VERSION "$Format:%h$"

NS_ :

BS_:

BU_: APB APP APS BCCEN BDY DAS DBG EAS EPAS EPAS2 EPAS3S EPB EPBM ESP GTW GTWU IBST IC MCU OCS PARK PARK3 RADAR RCM RT3000 SCCM SDM SEC TAS TAS2 TAS2DBG TOOL TPMS VCSEATD VCSEATP

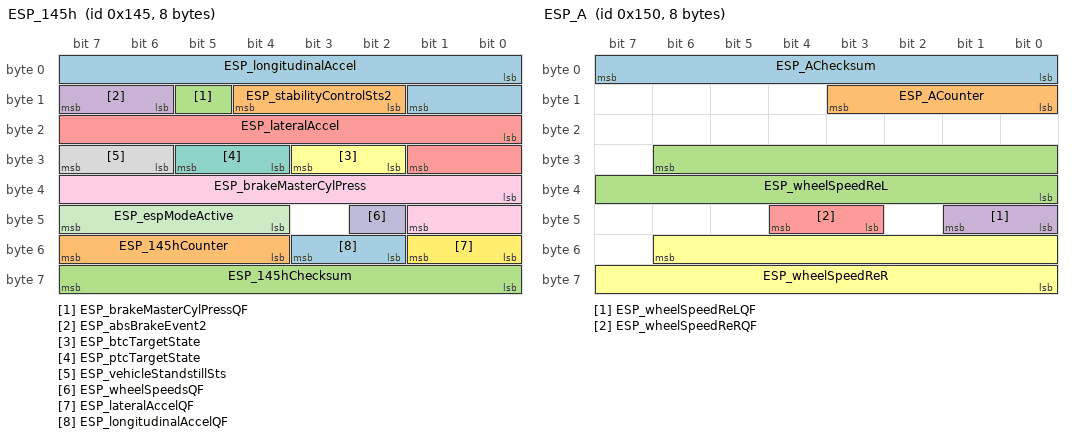
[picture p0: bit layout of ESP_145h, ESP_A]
BO_ 325 ESP_145h: 8 ESP
 SG_ ESP_longitudinalAccel : 0|10@1+ (0.05,-25.6) [-25.6|25.55] "m/s^2" DAS,GTW,PARK,TAS,EPB
 SG_ ESP_stabilityControlSts2 : 10|3@1+ (1,0) [0|0] "" RADAR,GTW,PARK,RCM,APS,TAS2
 SG_ ESP_brakeMasterCylPressQF : 13|1@1+ (1,0) [0|1] "" GTW
 SG_ ESP_absBrakeEvent2 : 14|2@1+ (1,0) [0|0] "" RADAR,GTW,PARK,RCM,APS,TAS2
 SG_ ESP_lateralAccel : 16|10@1+ (0.05,-25.6) [-25.6|25.55] "m/s^2" DAS,GTW,TAS
 SG_ ESP_btcTargetState : 26|2@1+ (1,0) [0|0] "" GTW
 SG_ ESP_ptcTargetState : 28|2@1+ (1,0) [0|0] "" GTW
 SG_ ESP_vehicleStandstillSts : 30|2@1+ (1,0) [0|0] "" RADAR,GTW
 SG_ ESP_brakeMasterCylPress : 32|10@1+ (0.25,-42.5) [-42.5|213.25] "bar" GTW
 SG_ ESP_wheelSpeedsQF : 42|1@1+ (1,0) [0|1] "" GTW,EPB,EPBM,APP
 SG_ ESP_espModeActive : 44|4@1+ (1,0) [0|15] "" GTW
 SG_ ESP_lateralAccelQF : 48|2@1+ (1,0) [0|3] "" GTW,APS,TAS
 SG_ ESP_longitudinalAccelQF : 50|2@1+ (1,0) [0|3] "" GTW,APS,TAS
 SG_ ESP_145hCounter : 52|4@1+ (1,0) [0|0] "" GTW,RCM,TAS
 SG_ ESP_145hChecksum : 56|8@1+ (1,0) [0|0] "" GTW,RCM,TAS

BO_ 336 ESP_A: 8 GTW
 SG_ ESP_AChecksum : 0|8@1+ (1,0) [0|0] "" EPAS
 SG_ ESP_ACounter : 8|4@1+ (1,0) [0|0] "" EPAS
 SG_ ESP_wheelSpeedReL : 30|15@0+ (0.01,0) [0|327.67] "km/h" EPAS
 SG_ ESP_wheelSpeedReLQF : 41|2@0+ (1,0) [0|0] "" EPAS
 SG_ ESP_wheelSpeedReRQF : 44|2@0+ (1,0) [0|0] "" EPAS
 SG_ ESP_wheelSpeedReR : 54|15@0+ (0.01,0) [0|327.67] "km/h" EPAS

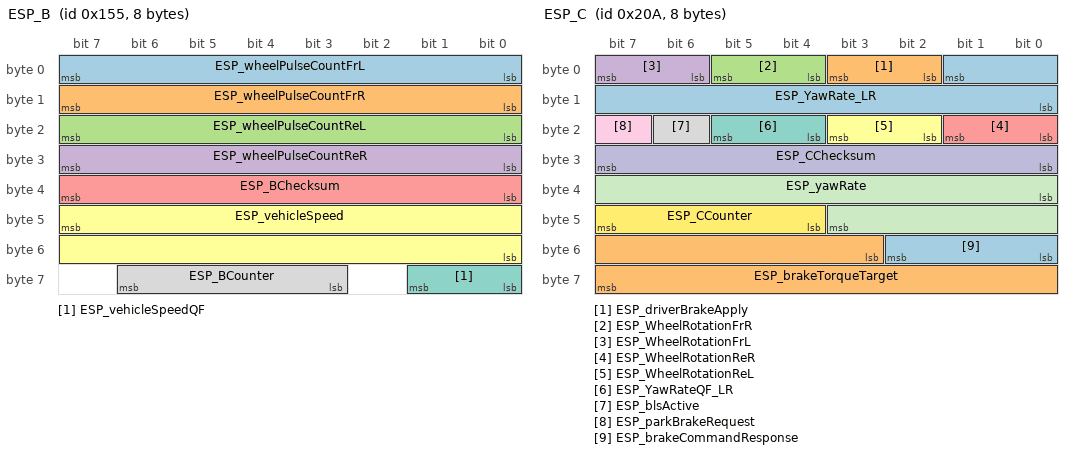
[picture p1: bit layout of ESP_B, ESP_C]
BO_ 341 ESP_B: 8 ESP
 SG_ ESP_wheelPulseCountFrL : 0|8@1+ (1,0) [0|254] "" GTW,TPMS,PARK,APS,APP,EPB,EPBM
 SG_ ESP_wheelPulseCountFrR : 8|8@1+ (1,0) [0|254] "" GTW,TPMS,PARK,APS,APP,EPB,EPBM
 SG_ ESP_wheelPulseCountReL : 16|8@1+ (1,0) [0|254] "" GTW,TPMS,PARK,DAS,EPB,EPBM
 SG_ ESP_wheelPulseCountReR : 24|8@1+ (1,0) [0|254] "" GTW,TPMS,PARK,DAS,EPB,EPBM
 SG_ ESP_BChecksum : 39|8@0+ (1,0) [0|0] "" PARK,SDM,RCM,TPMS,IC,EPAS,EPAS2,EPAS3S,EAS,GTW,TAS
 SG_ ESP_vehicleSpeed : 47|16@0+ (0.01,0) [0|655.35] "kph" PARK,TPMS,IC,SDM,RCM,EAS,EPAS,EPAS2,EPAS3S,GTW,APS,APP,TAS
 SG_ ESP_vehicleSpeedQF : 57|2@0+ (1,0) [0|0] "" PARK,SDM,RCM,TPMS,IC,EPAS,EPAS2,EPAS3S,EAS,GTW,APS,APP,TAS
 SG_ ESP_BCounter : 62|4@0+ (1,0) [0|15] "" PARK,SDM,RCM,TPMS,IC,EAS,EPAS,EPAS2,EPAS3S,GTW,APS,APP,TAS

BO_ 522 ESP_C: 8 ESP
 SG_ ESP_YawRate_LR : 1|10@0+ (0.2,-100) [-100|100] "Degrees/second" GTW,EPAS
 SG_ ESP_driverBrakeApply : 2|2@1+ (1,0) [0|3] "" DAS,GTW,RCM,EPB,TAS2
 SG_ ESP_WheelRotationFrR : 4|2@1+ (1,0) [0|3] "" GTW,PARK,RADAR,APS
 SG_ ESP_WheelRotationFrL : 6|2@1+ (1,0) [0|3] "" GTW,PARK,RADAR,APS
 SG_ ESP_WheelRotationReR : 16|2@1+ (1,0) [0|3] "" GTW,PARK,RADAR,APS
 SG_ ESP_WheelRotationReL : 18|2@1+ (1,0) [0|3] "" GTW,PARK,RADAR,APS
 SG_ ESP_YawRateQF_LR : 21|2@0+ (1,0) [0|0] "" GTW,EPAS,RADAR,APS
 SG_ ESP_blsActive : 22|1@1+ (1,0) [0|1] "" GTW
 SG_ ESP_parkBrakeRequest : 23|1@1+ (1,0) [0|1] "" EPB,EPBM,GTW
 SG_ ESP_CChecksum : 24|8@1+ (1,0) [0|0] "" GTW,EPB,EPBM,EPAS,RCM,TAS2
 SG_ ESP_yawRate : 32|12@1+ (0.001,-2) [-2|2] "rad/s" DAS,GTW,PARK
 SG_ ESP_CCounter : 44|4@1+ (1,0) [0|0] "" GTW,EPB,EPBM,EPAS,RCM,TAS2
 SG_ ESP_brakeCommandResponse : 48|3@1+ (1,0) [0|0] "" RADAR,GTW
 SG_ ESP_brakeTorqueTarget : 51|13@1+ (2,0) [0|16382] "Nm" RADAR,GTW

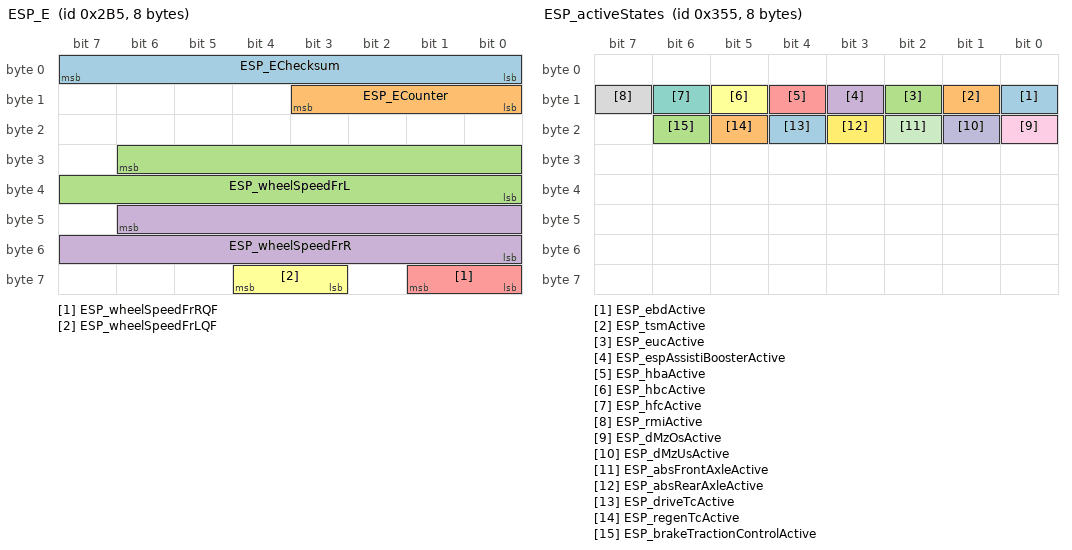
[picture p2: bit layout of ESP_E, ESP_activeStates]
BO_ 693 ESP_E: 8 GTW
 SG_ ESP_EChecksum : 0|8@1+ (1,0) [0|0] "" EPAS
 SG_ ESP_ECounter : 8|4@1+ (1,0) [0|0] "" EPAS
 SG_ ESP_wheelSpeedFrL : 30|15@0+ (0.01,0) [0|327.67] "km/h" EPAS
 SG_ ESP_wheelSpeedFrR : 46|15@0+ (0.01,0) [0|327.67] "km/h" EPAS
 SG_ ESP_wheelSpeedFrRQF : 57|2@0+ (1,0) [0|0] "" EPAS
 SG_ ESP_wheelSpeedFrLQF : 60|2@0+ (1,0) [0|0] "" EPAS

BO_ 853 ESP_activeStates: 8 ESP
 SG_ ESP_ebdActive : 8|1@1+ (1,0) [0|0] "" GTW
 SG_ ESP_tsmActive : 9|1@1+ (1,0) [0|0] "" GTW
 SG_ ESP_eucActive : 10|1@1+ (1,0) [0|0] "" GTW
 SG_ ESP_espAssistiBoosterActive : 11|1@1+ (1,0) [0|0] "" GTW
 SG_ ESP_hbaActive : 12|1@1+ (1,0) [0|0] "" GTW
 SG_ ESP_hbcActive : 13|1@1+ (1,0) [0|0] "" GTW
 SG_ ESP_hfcActive : 14|1@1+ (1,0) [0|0] "" GTW
 SG_ ESP_rmiActive : 15|1@1+ (1,0) [0|0] "" GTW
 SG_ ESP_dMzOsActive : 16|1@1+ (1,0) [0|0] "" GTW
 SG_ ESP_dMzUsActive : 17|1@1+ (1,0) [0|0] "" GTW
 SG_ ESP_absFrontAxleActive : 18|1@1+ (1,0) [0|0] "" GTW
 SG_ ESP_absRearAxleActive : 19|1@1+ (1,0) [0|0] "" GTW
 SG_ ESP_driveTcActive : 20|1@1+ (1,0) [0|0] "" GTW
 SG_ ESP_regenTcActive : 21|1@1+ (1,0) [0|0] "" GTW
 SG_ ESP_brakeTractionControlActive : 22|1@1+ (1,0) [0|0] "" GTW

BO_ 1285 ESP_alertLog: 8 ESP
 SG_ ESP_alertID M : 0|15@1+ (1,0) [0|0] "" GTW
 SG_ ESP_alertType : 15|1@1+ (1,0) [0|0] "" GTW
 SG_ ESP_acmHydReturnPumpWeak m16384 : 16|1@1+ (1,0) [0|0] "" GTW
 SG_ ESP_rfpActUbmrSupplyError m16384 : 17|1@1+ (1,0) [0|0] "" GTW
 SG_ ESP_rfpIFsTstFld m16384 : 18|1@1+ (1,0) [0|0] "" GTW
 SG_ ESP_rfpMrAuCLinTstFld m16384 : 19|1@1+ (1,0) [0|0] "" GTW
 SG_ ESP_rfpMrdSupErr m16384 : 20|1@1+ (1,0) [0|0] "" GTW
 SG_ ESP_rfpMrgInvrsTstFld m16384 : 21|1@1+ (1,0) [0|0] "" GTW
 SG_ ESP_rfpMrgTstFld m16384 : 22|1@1+ (1,0) [0|0] "" GTW
 SG_ ESP_rfpMRolErr m16384 : 23|1@1+ (1,0) [0|0] "" GTW
 SG_ ESP_rfpMrPuTstFld m16384 : 24|1@1+ (1,0) [0|0] "" GTW
 SG_ ESP_rfpMRscErr m16384 : 25|1@1+ (1,0) [0|0] "" GTW
 SG_ ESP_rfpPMTFld m16384 : 26|1@1+ (1,0) [0|0] "" GTW
 SG_ ESP_rfpStopMonFld m16384 : 27|1@1+ (1,0) [0|0] "" GTW
 SG_ ESP_acmHydPumpVoltHigh m16384 : 28|1@1+ (1,0) [0|0] "" GTW
 SG_ ESP_wssFLLineGnd m16385 : 16|1@1+ (1,0) [0|0] "" GTW
 SG_ ESP_wssFLLineHigh m16386 : 16|1@1+ (1,0) [0|0] "" GTW
 SG_ ESP_wssFLLineUndef m16387 : 16|1@1+ (1,0) [0|0] "" GTW
 SG_ ESP_wssMonRangeFL m16388 : 16|1@1+ (1,0) [0|0] "" GTW
 SG_ ESP_wssFLHetBufNoise m16388 : 17|1@1+ (1,0) [0|0] "" GTW
 SG_ ESP_wssSignalLostFL m16389 : 16|1@1+ (1,0) [0|0] "" GTW
 SG_ ESP_wssFLNoEdge m16389 : 17|1@1+ (1,0) [0|0] "" GTW
 SG_ ESP_wssFLWrongSen m16390 : 16|1@1+ (1,0) [0|0] "" GTW
 SG_ ESP_wssMonNoiseFL m16391 : 16|1@1+ (1,0) [0|0] "" GTW
 SG_ ESP_wssMonVDiffFL m16391 : 17|1@1+ (1,0) [0|0] "" GTW
 SG_ ESP_wssMonDoHiFL m16391 : 18|1@1+ (1,0) [0|0] "" GTW
 SG_ ESP_wssMonDoLoFL m16391 : 19|1@1+ (1,0) [0|0] "" GTW
 SG_ ESP_wssMonDynFL m16391 : 20|1@1+ (1,0) [0|0] "" GTW
 SG_ ESP_wssPermanentSusFL m16391 : 21|1@1+ (1,0) [0|0] "" GTW
 SG_ ESP_wssMonWheelDirFL m16392 : 16|1@1+ (1,0) [0|0] "" GTW
 SG_ ESP_wssSignFa m16392 : 17|1@1+ (1,0) [0|0] "" GTW
 SG_ ESP_wssFLAirGap m16393 : 16|1@1+ (1,0) [0|0] "" GTW
 SG_ ESP_wssFLSupGnd m16394 : 16|1@1+ (1,0) [0|0] "" GTW
 SG_ ESP_wssTstFLFld m16395 : 16|1@1+ (1,0) [0|0] "" GTW
 SG_ ESP_wssFRLineGnd m16396 : 16|1@1+ (1,0) [0|0] "" GTW
 SG_ ESP_wssFRLineHigh m16397 : 16|1@1+ (1,0) [0|0] "" GTW
 SG_ ESP_wssFRLineUndef m16398 : 16|1@1+ (1,0) [0|0] "" GTW
 SG_ ESP_wssMonRangeFR m16399 : 16|1@1+ (1,0) [0|0] "" GTW
 SG_ ESP_wssFRHetBufNoise m16399 : 17|1@1+ (1,0) [0|0] "" GTW
 SG_ ESP_wssSignalLostFR m16400 : 16|1@1+ (1,0) [0|0] "" GTW
 SG_ ESP_wssFRNoEdge m16400 : 17|1@1+ (1,0) [0|0] "" GTW
 SG_ ESP_wssFRWrongSen m16401 : 16|1@1+ (1,0) [0|0] "" GTW
 SG_ ESP_wssMonNoiseFR m16402 : 16|1@1+ (1,0) [0|0] "" GTW
 SG_ ESP_wssMonVDiffFR m16402 : 17|1@1+ (1,0) [0|0] "" GTW
 SG_ ESP_wssMonDoHiFR m16402 : 18|1@1+ (1,0) [0|0] "" GTW
 SG_ ESP_wssMonDoLoFR m16402 : 19|1@1+ (1,0) [0|0] "" GTW
 SG_ ESP_wssMonDynFR m16402 : 20|1@1+ (1,0) [0|0] "" GTW
 SG_ ESP_wssPermanentSusFR m16402 : 21|1@1+ (1,0) [0|0] "" GTW
 SG_ ESP_wssMonWheelDirFR m16403 : 16|1@1+ (1,0) [0|0] "" GTW
 SG_ ESP_wssFRAirGap m16404 : 16|1@1+ (1,0) [0|0] "" GTW
 SG_ ESP_wssFRSupGnd m16405 : 16|1@1+ (1,0) [0|0] "" GTW
 SG_ ESP_wssTstFRFld m16406 : 16|1@1+ (1,0) [0|0] "" GTW
 SG_ ESP_wssRLLineGnd m16407 : 16|1@1+ (1,0) [0|0] "" GTW
 SG_ ESP_wssRLLineHigh m16408 : 16|1@1+ (1,0) [0|0] "" GTW
 SG_ ESP_wssRLLineUndef m16409 : 16|1@1+ (1,0) [0|0] "" GTW
 SG_ ESP_wssMonRangeRL m16410 : 16|1@1+ (1,0) [0|0] "" GTW
 SG_ ESP_wssRLHetBufNoise m16410 : 17|1@1+ (1,0) [0|0] "" GTW
 SG_ ESP_wssSignalLostRL m16411 : 16|1@1+ (1,0) [0|0] "" GTW
 SG_ ESP_wssRLNoEdge m16411 : 17|1@1+ (1,0) [0|0] "" GTW
 SG_ ESP_wssRLWrongSen m16412 : 16|1@1+ (1,0) [0|0] "" GTW
 SG_ ESP_wssMonNoiseRL m16413 : 16|1@1+ (1,0) [0|0] "" GTW
 SG_ ESP_wssMonVDiffRL m16413 : 17|1@1+ (1,0) [0|0] "" GTW
 SG_ ESP_wssMonDoHiRL m16413 : 18|1@1+ (1,0) [0|0] "" GTW
 SG_ ESP_wssMonDoLoRL m16413 : 19|1@1+ (1,0) [0|0] "" GTW
 SG_ ESP_wssMonDynRL m16413 : 20|1@1+ (1,0) [0|0] "" GTW
 SG_ ESP_wssPermanentSusRL m16413 : 21|1@1+ (1,0) [0|0] "" GTW
 SG_ ESP_wssMonWheelDirRL m16414 : 16|1@1+ (1,0) [0|0] "" GTW
 SG_ ESP_wssSignRA m16414 : 17|1@1+ (1,0) [0|0] "" GTW
 SG_ ESP_wssRLAirGap m16415 : 16|1@1+ (1,0) [0|0] "" GTW
 SG_ ESP_wssRLSupGnd m16416 : 16|1@1+ (1,0) [0|0] "" GTW
 SG_ ESP_wssTstRLFld m16417 : 16|1@1+ (1,0) [0|0] "" GTW
 SG_ ESP_wssRRLineGnd m16418 : 16|1@1+ (1,0) [0|0] "" GTW
 SG_ ESP_wssRRLineHigh m16419 : 16|1@1+ (1,0) [0|0] "" GTW
 SG_ ESP_wssRRLineUndef m16420 : 16|1@1+ (1,0) [0|0] "" GTW
 SG_ ESP_wssMonRangeRR m16421 : 16|1@1+ (1,0) [0|0] "" GTW
 SG_ ESP_wssRRHetBufNoise m16421 : 17|1@1+ (1,0) [0|0] "" GTW
 SG_ ESP_wssSignalLostRR m16422 : 16|1@1+ (1,0) [0|0] "" GTW
 SG_ ESP_wssRRNoEdge m16422 : 17|1@1+ (1,0) [0|0] "" GTW
 SG_ ESP_wssRRWrongSen m16423 : 16|1@1+ (1,0) [0|0] "" GTW
 SG_ ESP_wssMonNoiseRR m16424 : 16|1@1+ (1,0) [0|0] "" GTW
 SG_ ESP_wssMonVDiffRR m16424 : 17|1@1+ (1,0) [0|0] "" GTW
 SG_ ESP_wssMonDoHiRR m16424 : 18|1@1+ (1,0) [0|0] "" GTW
 SG_ ESP_wssMonDoLoRR m16424 : 19|1@1+ (1,0) [0|0] "" GTW
 SG_ ESP_wssMonDynRR m16424 : 20|1@1+ (1,0) [0|0] "" GTW
 SG_ ESP_wssPermanentSusRR m16424 : 21|1@1+ (1,0) [0|0] "" GTW
 SG_ ESP_wssMonWheelDirRR m16425 : 16|1@1+ (1,0) [0|0] "" GTW
 SG_ ESP_wssRRAirGap m16426 : 16|1@1+ (1,0) [0|0] "" GTW
 SG_ ESP_wssRRSupGnd m16427 : 16|1@1+ (1,0) [0|0] "" GTW
 SG_ ESP_wssTstRRFld m16428 : 16|1@1+ (1,0) [0|0] "" GTW
 SG_ ESP_wssMonGenTempFld m16429 : 16|1@1+ (1,0) [0|0] "" GTW
 SG_ ESP_wssMonVDiffGen m16429 : 17|1@1+ (1,0) [0|0] "" GTW
 SG_ ESP_wssMonWheelDirGen m16429 : 18|1@1+ (1,0) [0|0] "" GTW
 SG_ ESP_wssMoreThanOneSusp m16429 : 19|1@1+ (1,0) [0|0] "" GTW
 SG_ ESP_wssMoreThanOneSuspSt m16429 : 20|1@1+ (1,0) [0|0] "" GTW
 SG_ ESP_wssReverseCurr m16429 : 21|1@1+ (1,0) [0|0] "" GTW
 SG_ ESP_acmBlsPermHigh m16430 : 16|1@1+ (1,0) [0|0] "" GTW
 SG_ ESP_acmBlsPermHighHhc m16430 : 17|1@1+ (1,0) [0|0] "" GTW
 SG_ ESP_blsStatusInvd m16431 : 16|1@1+ (1,0) [0|0] "" GTW
 SG_ ESP_acmPbsPlausPsBlsTh1 m16432 : 16|1@1+ (1,0) [0|0] "" GTW
 SG_ ESP_acmPbsPlausPsBlsTh3 m16432 : 17|1@1+ (1,0) [0|0] "" GTW
 SG_ ESP_pressSenMc1Line m16433 : 16|1@1+ (1,0) [0|0] "" GTW
 SG_ ESP_acmPsOfstMc1 m16434 : 16|1@1+ (1,0) [0|0] "" GTW
 SG_ ESP_acmPsTstpulseMc1 m16435 : 16|1@1+ (1,0) [0|0] "" GTW
 SG_ ESP_comSclLowBrakeFluid m16436 : 16|1@1+ (1,0) [0|0] "" GTW
 SG_ ESP_sasMonConstSig m16437 : 16|1@1+ (1,0) [0|0] "" GTW
 SG_ ESP_sasMonOfst m16438 : 16|1@1+ (1,0) [0|0] "" GTW
 SG_ ESP_sasPls m16439 : 16|1@1+ (1,0) [0|0] "" GTW
 SG_ ESP_sasSign m16439 : 17|1@1+ (1,0) [0|0] "" GTW
 SG_ ESP_sclMm3Ay1AltrnFlt m16440 : 16|1@1+ (1,0) [0|0] "" GTW
 SG_ ESP_sclMm3Ay1InitFl m16440 : 17|1@1+ (1,0) [0|0] "" GTW
 SG_ ESP_sclMm3Ay1InvlidVal m16440 : 18|1@1+ (1,0) [0|0] "" GTW
 SG_ ESP_sclMm3Ay1PermFl m16440 : 19|1@1+ (1,0) [0|0] "" GTW
 SG_ ESP_sclMm3Ay1SenNotAvail m16440 : 20|1@1+ (1,0) [0|0] "" GTW
 SG_ ESP_sclMm3Ay1SigFl m16440 : 21|1@1+ (1,0) [0|0] "" GTW
 SG_ ESP_aysMonRange m16441 : 16|1@1+ (1,0) [0|0] "" GTW
 SG_ ESP_aysOffset m16442 : 16|1@1+ (1,0) [0|0] "" GTW
 SG_ ESP_aysPlaus m16443 : 16|1@1+ (1,0) [0|0] "" GTW
 SG_ ESP_aysStandstill m16443 : 17|1@1+ (1,0) [0|0] "" GTW
 SG_ ESP_sclMm3CalInvValFlt m16444 : 16|1@1+ (1,0) [0|0] "" GTW
 SG_ ESP_sclMm3CalOfstPlsFlt m16444 : 17|1@1+ (1,0) [0|0] "" GTW
 SG_ ESP_sclMm3EEpromAcsErr m16444 : 18|1@1+ (1,0) [0|0] "" GTW
 SG_ ESP_sclMm3SenInfoTimeout m16444 : 19|1@1+ (1,0) [0|0] "" GTW
 SG_ ESP_sclMm3SerNumChanged m16444 : 20|1@1+ (1,0) [0|0] "" GTW
 SG_ ESP_sclMm3Ax1AltrnteFlts m16444 : 21|1@1+ (1,0) [0|0] "" GTW
 SG_ ESP_sclMm3Ax1InitFl m16444 : 22|1@1+ (1,0) [0|0] "" GTW
 SG_ ESP_sclMm3Ax1InvdVal m16444 : 23|1@1+ (1,0) [0|0] "" GTW
 SG_ ESP_sclMm3Ax1PermFl m16444 : 24|1@1+ (1,0) [0|0] "" GTW
 SG_ ESP_sclMm3Ax1SenNotAvail m16444 : 25|1@1+ (1,0) [0|0] "" GTW
 SG_ ESP_sclMm3Ax1SigFl m16444 : 26|1@1+ (1,0) [0|0] "" GTW
 SG_ ESP_axsMonRange m16445 : 16|1@1+ (1,0) [0|0] "" GTW
 SG_ ESP_acmBtmOverheatWarn m16446 : 16|1@1+ (1,0) [0|0] "" GTW
 SG_ ESP_axsOffset m16446 : 17|1@1+ (1,0) [0|0] "" GTW
 SG_ ESP_axsMonConstSig m16447 : 16|1@1+ (1,0) [0|0] "" GTW
 SG_ ESP_axsMonPlaus m16447 : 17|1@1+ (1,0) [0|0] "" GTW
 SG_ ESP_axsPlausHighAccel m16447 : 18|1@1+ (1,0) [0|0] "" GTW
 SG_ ESP_sclMm3Yaw1AltFlts m16448 : 16|1@1+ (1,0) [0|0] "" GTW
 SG_ ESP_sclMm3Yaw1InitFl m16448 : 17|1@1+ (1,0) [0|0] "" GTW
 SG_ ESP_sclMm3Yaw1InvdVal m16448 : 18|1@1+ (1,0) [0|0] "" GTW
 SG_ ESP_sclMm3Yaw1PermFl m16448 : 19|1@1+ (1,0) [0|0] "" GTW
 SG_ ESP_sclMm3Yaw1SenNotAvl m16448 : 20|1@1+ (1,0) [0|0] "" GTW
 SG_ ESP_sclMm3Yaw1SigFl m16448 : 21|1@1+ (1,0) [0|0] "" GTW
 SG_ ESP_yrsSign m16449 : 16|1@1+ (1,0) [0|0] "" GTW
 SG_ ESP_yrsPlaus m16449 : 17|1@1+ (1,0) [0|0] "" GTW
 SG_ ESP_absContCon m16450 : 16|1@1+ (1,0) [0|0] "" GTW
 SG_ ESP_absEmergencyBrake m16450 : 17|1@1+ (1,0) [0|0] "" GTW
 SG_ ESP_vdcContCon m16450 : 18|1@1+ (1,0) [0|0] "" GTW
 SG_ ESP_hydSupHwUndvolt m16451 : 16|1@1+ (1,0) [0|0] "" GTW
 SG_ ESP_hydSupUndvolt m16451 : 17|1@1+ (1,0) [0|0] "" GTW
 SG_ ESP_netUndvolt m16451 : 18|1@1+ (1,0) [0|0] "" GTW
 SG_ ESP_sysUndvolt m16451 : 19|1@1+ (1,0) [0|0] "" GTW
 SG_ ESP_sysNetUndvolt m16451 : 20|1@1+ (1,0) [0|0] "" GTW
 SG_ ESP_sysUBVrUndvolt m16451 : 21|1@1+ (1,0) [0|0] "" GTW
 SG_ ESP_wssUndvolt m16451 : 22|1@1+ (1,0) [0|0] "" GTW
 SG_ ESP_netOvrvolt m16452 : 16|1@1+ (1,0) [0|0] "" GTW
 SG_ ESP_supOvrvolt m16452 : 17|1@1+ (1,0) [0|0] "" GTW
 SG_ ESP_sysOvrvolt m16452 : 18|1@1+ (1,0) [0|0] "" GTW
 SG_ ESP_sysNetOvrvolt m16452 : 19|1@1+ (1,0) [0|0] "" GTW
 SG_ ESP_canEHwError m16453 : 16|1@1+ (1,0) [0|0] "" GTW
 SG_ ESP_pdurEPduInstanceLost m16453 : 17|1@1+ (1,0) [0|0] "" GTW
 SG_ ESP_bertFlt m16454 : 16|1@1+ (1,0) [0|0] "" GTW
 SG_ ESP_canETimeout m16454 : 17|1@1+ (1,0) [0|0] "" GTW
 SG_ ESP_ccmFlt m16454 : 18|1@1+ (1,0) [0|0] "" GTW
 SG_ ESP_cpuException m16454 : 19|1@1+ (1,0) [0|0] "" GTW
 SG_ ESP_deadlineMonTaskx1Ovr m16454 : 20|1@1+ (1,0) [0|0] "" GTW
 SG_ ESP_esmNmiFlt m16454 : 21|1@1+ (1,0) [0|0] "" GTW
 SG_ ESP_esmSafetyFlt m16454 : 22|1@1+ (1,0) [0|0] "" GTW
 SG_ ESP_hetRefError m16454 : 23|1@1+ (1,0) [0|0] "" GTW
 SG_ ESP_micInitSpiTstFld m16454 : 24|1@1+ (1,0) [0|0] "" GTW
 SG_ ESP_micInitSpiTransfError m16454 : 25|1@1+ (1,0) [0|0] "" GTW
 SG_ ESP_micIntMonGenBitMon m16454 : 26|1@1+ (1,0) [0|0] "" GTW
 SG_ ESP_micIntVoltMonFld m16454 : 27|1@1+ (1,0) [0|0] "" GTW
 SG_ ESP_micSpiTout m16454 : 28|1@1+ (1,0) [0|0] "" GTW
 SG_ ESP_micSpiTransferErr m16454 : 29|1@1+ (1,0) [0|0] "" GTW
 SG_ ESP_osErrHook m16454 : 30|1@1+ (1,0) [0|0] "" GTW
 SG_ ESP_pbistErr m16454 : 31|1@1+ (1,0) [0|0] "" GTW
 SG_ ESP_pdmCustomerIdMis m16454 : 32|1@1+ (1,0) [0|0] "" GTW
 SG_ ESP_pdmDtFormatMis m16454 : 33|1@1+ (1,0) [0|0] "" GTW
 SG_ ESP_pdmDeviceOutOfMemory m16454 : 34|1@1+ (1,0) [0|0] "" GTW
 SG_ ESP_pdmFieldSizeMis m16454 : 35|1@1+ (1,0) [0|0] "" GTW
 SG_ ESP_pdmHwAcsErr m16454 : 36|1@1+ (1,0) [0|0] "" GTW
 SG_ ESP_pdmInternalHWErr m16454 : 37|1@1+ (1,0) [0|0] "" GTW
 SG_ ESP_pdmWriteCyclesExceed m16454 : 38|1@1+ (1,0) [0|0] "" GTW
 SG_ ESP_ramInitErr m16454 : 39|1@1+ (1,0) [0|0] "" GTW
 SG_ ESP_ramsinlgeFlt m16454 : 40|1@1+ (1,0) [0|0] "" GTW
 SG_ ESP_rfpDiagHydrProt m16454 : 41|1@1+ (1,0) [0|0] "" GTW
 SG_ ESP_rtpEnaHigh m16454 : 42|1@1+ (1,0) [0|0] "" GTW
 SG_ ESP_smmOneReqsInit m16454 : 43|1@1+ (1,0) [0|0] "" GTW
 SG_ ESP_stackOvrUndFlow m16454 : 44|1@1+ (1,0) [0|0] "" GTW
 SG_ ESP_stmAswSysTout m16454 : 45|1@1+ (1,0) [0|0] "" GTW
 SG_ ESP_sysErrHook m16454 : 46|1@1+ (1,0) [0|0] "" GTW
 SG_ ESP_ucSafetyFlt m16454 : 47|1@1+ (1,0) [0|0] "" GTW
 SG_ ESP_unsupportedHw m16454 : 48|1@1+ (1,0) [0|0] "" GTW
 SG_ ESP_ecuAdcConversionErr m16455 : 16|1@1+ (1,0) [0|0] "" GTW
 SG_ ESP_ecuAdcSelftestErr m16455 : 17|1@1+ (1,0) [0|0] "" GTW
 SG_ ESP_ecuBandGap m16455 : 18|1@1+ (1,0) [0|0] "" GTW
 SG_ ESP_ecuEnableElFls m16455 : 19|1@1+ (1,0) [0|0] "" GTW
 SG_ ESP_ecuEnableHyFls m16455 : 20|1@1+ (1,0) [0|0] "" GTW
 SG_ ESP_ecuEnContErr m16455 : 21|1@1+ (1,0) [0|0] "" GTW
 SG_ ESP_ecuErrpinCntTstFls m16455 : 22|1@1+ (1,0) [0|0] "" GTW
 SG_ ESP_ecuHetException m16455 : 23|1@1+ (1,0) [0|0] "" GTW
 SG_ ESP_ecuHetTuAddErr m16455 : 24|1@1+ (1,0) [0|0] "" GTW
 SG_ ESP_ecuHetTuBusErr m16455 : 25|1@1+ (1,0) [0|0] "" GTW
 SG_ ESP_ecuHetTuBusyErr m16455 : 26|1@1+ (1,0) [0|0] "" GTW
 SG_ ESP_ecuHetTuException m16455 : 27|1@1+ (1,0) [0|0] "" GTW
 SG_ ESP_ecuRomCheck m16455 : 28|1@1+ (1,0) [0|0] "" GTW
 SG_ ESP_ecuSupVoltDivDrift m16455 : 29|1@1+ (1,0) [0|0] "" GTW
 SG_ ESP_ecuTaskMissing m16455 : 30|1@1+ (1,0) [0|0] "" GTW
 SG_ ESP_ecuVrOnWhileWdTout m16455 : 31|1@1+ (1,0) [0|0] "" GTW
 SG_ ESP_ecuVrViaSpiFls m16455 : 32|1@1+ (1,0) [0|0] "" GTW
 SG_ ESP_ecuWdErrCntContErr m16455 : 33|1@1+ (1,0) [0|0] "" GTW
 SG_ ESP_ecuWdFltCntTstFls m16455 : 34|1@1+ (1,0) [0|0] "" GTW
 SG_ ESP_ecuWdScheduleTout m16455 : 35|1@1+ (1,0) [0|0] "" GTW
 SG_ ESP_ecuWdStarttestFls m16455 : 36|1@1+ (1,0) [0|0] "" GTW
 SG_ ESP_ecuWdStatusContErr m16455 : 37|1@1+ (1,0) [0|0] "" GTW
 SG_ ESP_vlvInverseActTstFlt m16456 : 16|1@1+ (1,0) [0|0] "" GTW
 SG_ ESP_vlvOvrHeatProt m16456 : 17|1@1+ (1,0) [0|0] "" GTW
 SG_ ESP_vlvPwmCheckContOn m16456 : 18|1@1+ (1,0) [0|0] "" GTW
 SG_ ESP_vlvRefEepromErr m16456 : 19|1@1+ (1,0) [0|0] "" GTW
 SG_ ESP_vlvRefResistor m16456 : 20|1@1+ (1,0) [0|0] "" GTW
 SG_ ESP_vlvSvdtContOn m16456 : 21|1@1+ (1,0) [0|0] "" GTW
 SG_ ESP_vlvAsicCfgEchoErr m16456 : 22|1@1+ (1,0) [0|0] "" GTW
 SG_ ESP_vlvAvCfg m16456 : 23|1@1+ (1,0) [0|0] "" GTW
 SG_ ESP_vlvBist m16456 : 24|1@1+ (1,0) [0|0] "" GTW
 SG_ ESP_vlvINxFl m16456 : 25|1@1+ (1,0) [0|0] "" GTW
 SG_ ESP_vlvOpLdUndCurrFld m16456 : 26|1@1+ (1,0) [0|0] "" GTW
 SG_ ESP_vlvPromParityErr m16456 : 27|1@1+ (1,0) [0|0] "" GTW
 SG_ ESP_vlvSGndLoss m16456 : 28|1@1+ (1,0) [0|0] "" GTW
 SG_ ESP_vlvSupLineTst m16456 : 29|1@1+ (1,0) [0|0] "" GTW
 SG_ ESP_vlvU3VFld m16456 : 30|1@1+ (1,0) [0|0] "" GTW
 SG_ ESP_vlvUvrLowSpiBitFld m16456 : 31|1@1+ (1,0) [0|0] "" GTW
 SG_ ESP_vlvUVRmeasureCmpFld m16456 : 32|1@1+ (1,0) [0|0] "" GTW
 SG_ ESP_vlvUvrToUbvrLeakage m16456 : 33|1@1+ (1,0) [0|0] "" GTW
 SG_ ESP_vlvVzpFld m16456 : 34|1@1+ (1,0) [0|0] "" GTW
 SG_ ESP_voltPreRegModeFld m16456 : 35|1@1+ (1,0) [0|0] "" GTW
 SG_ ESP_vrHighOhmShToGndCont m16456 : 36|1@1+ (1,0) [0|0] "" GTW
 SG_ ESP_vrOnFls m16456 : 37|1@1+ (1,0) [0|0] "" GTW
 SG_ ESP_vrOnFlsCont m16456 : 38|1@1+ (1,0) [0|0] "" GTW
 SG_ ESP_vrSafetySwitchTout m16456 : 39|1@1+ (1,0) [0|0] "" GTW
 SG_ ESP_vrShortToGndCont m16456 : 40|1@1+ (1,0) [0|0] "" GTW
 SG_ ESP_vrStuck m16456 : 41|1@1+ (1,0) [0|0] "" GTW
 SG_ ESP_vrStuckCont m16456 : 42|1@1+ (1,0) [0|0] "" GTW
 SG_ ESP_wSSHetMonMuxSigErr m16456 : 43|1@1+ (1,0) [0|0] "" GTW
 SG_ ESP_wssModeFld m16456 : 44|1@1+ (1,0) [0|0] "" GTW
 SG_ ESP_wssTstSysICFl m16456 : 45|1@1+ (1,0) [0|0] "" GTW
 SG_ ESP_xpassEchoCountErr m16456 : 46|1@1+ (1,0) [0|0] "" GTW
 SG_ ESP_xpassToutErr m16456 : 47|1@1+ (1,0) [0|0] "" GTW
 SG_ ESP_vlvChanUnusedFreeWhl m16456 : 48|1@1+ (1,0) [0|0] "" GTW
 SG_ ESP_vlvFreeWhlContOn m16456 : 49|1@1+ (1,0) [0|0] "" GTW
 SG_ ESP_vlvAvFlGen m16457 : 16|1@1+ (1,0) [0|0] "" GTW
 SG_ ESP_vlvAvFlLeakage m16457 : 17|1@1+ (1,0) [0|0] "" GTW
 SG_ ESP_vlvAvFlPwm m16457 : 18|1@1+ (1,0) [0|0] "" GTW
 SG_ ESP_vlvAvFlQx m16457 : 19|1@1+ (1,0) [0|0] "" GTW
 SG_ ESP_vlvAvFlResOutOfRange m16457 : 20|1@1+ (1,0) [0|0] "" GTW
 SG_ ESP_vlvAvFlSvdt m16457 : 21|1@1+ (1,0) [0|0] "" GTW
 SG_ ESP_vlvAvFlVart m16457 : 22|1@1+ (1,0) [0|0] "" GTW
 SG_ ESP_vlvAvFrGen m16457 : 23|1@1+ (1,0) [0|0] "" GTW
 SG_ ESP_vlvAvFrLeakage m16457 : 24|1@1+ (1,0) [0|0] "" GTW
 SG_ ESP_vlvAvFrPwm m16457 : 25|1@1+ (1,0) [0|0] "" GTW
 SG_ ESP_vlvAvFrQx m16457 : 26|1@1+ (1,0) [0|0] "" GTW
 SG_ ESP_vlvAvFrResOutOfRange m16457 : 27|1@1+ (1,0) [0|0] "" GTW
 SG_ ESP_vlvAvFrSvdt m16457 : 28|1@1+ (1,0) [0|0] "" GTW
 SG_ ESP_vlvAvFrVart m16457 : 29|1@1+ (1,0) [0|0] "" GTW
 SG_ ESP_vlvAvRlGen m16457 : 30|1@1+ (1,0) [0|0] "" GTW
 SG_ ESP_vlvAvRlLeakage m16457 : 31|1@1+ (1,0) [0|0] "" GTW
 SG_ ESP_vlvAvRlPwm m16457 : 32|1@1+ (1,0) [0|0] "" GTW
 SG_ ESP_vlvAvRlQx m16457 : 33|1@1+ (1,0) [0|0] "" GTW
 SG_ ESP_vlvAvRlResOutOfRange m16457 : 34|1@1+ (1,0) [0|0] "" GTW
 SG_ ESP_vlvAvRlSvdt m16457 : 35|1@1+ (1,0) [0|0] "" GTW
 SG_ ESP_vlvAvRlVart m16457 : 36|1@1+ (1,0) [0|0] "" GTW
 SG_ ESP_vlvAvRrGen m16457 : 37|1@1+ (1,0) [0|0] "" GTW
 SG_ ESP_vlvAvRrLeakage m16457 : 38|1@1+ (1,0) [0|0] "" GTW
 SG_ ESP_vlvAvRrPwm m16457 : 39|1@1+ (1,0) [0|0] "" GTW
 SG_ ESP_vlvAvRrQx m16457 : 40|1@1+ (1,0) [0|0] "" GTW
 SG_ ESP_vlvAvRrResOutOfRange m16457 : 41|1@1+ (1,0) [0|0] "" GTW
 SG_ ESP_vlvAvRrSvdt m16457 : 42|1@1+ (1,0) [0|0] "" GTW
 SG_ ESP_vlvAvRrVart m16457 : 43|1@1+ (1,0) [0|0] "" GTW
 SG_ ESP_vlvEvFlFreeWhl m16458 : 16|1@1+ (1,0) [0|0] "" GTW
 SG_ ESP_vlvEvFlGen m16458 : 17|1@1+ (1,0) [0|0] "" GTW
 SG_ ESP_vlvEvFlLeakage m16458 : 18|1@1+ (1,0) [0|0] "" GTW
 SG_ ESP_vlvEvFlPwm m16458 : 19|1@1+ (1,0) [0|0] "" GTW
 SG_ ESP_vlvEvFlQx m16458 : 20|1@1+ (1,0) [0|0] "" GTW
 SG_ ESP_vlvEvFlResOutOfRange m16458 : 21|1@1+ (1,0) [0|0] "" GTW
 SG_ ESP_vlvEvFlSvdt m16458 : 22|1@1+ (1,0) [0|0] "" GTW
 SG_ ESP_vlvEvFlVart m16458 : 23|1@1+ (1,0) [0|0] "" GTW
 SG_ ESP_vlvEvFrFreeWhl m16458 : 24|1@1+ (1,0) [0|0] "" GTW
 SG_ ESP_vlvEvFrGen m16458 : 25|1@1+ (1,0) [0|0] "" GTW
 SG_ ESP_vlvEvFrLeakage m16458 : 26|1@1+ (1,0) [0|0] "" GTW
 SG_ ESP_vlvEvFrPwm m16458 : 27|1@1+ (1,0) [0|0] "" GTW
 SG_ ESP_vlvEvFrQx m16458 : 28|1@1+ (1,0) [0|0] "" GTW
 SG_ ESP_vlvEvFrResOutOfRange m16458 : 29|1@1+ (1,0) [0|0] "" GTW
 SG_ ESP_vlvEvFrSvdt m16458 : 30|1@1+ (1,0) [0|0] "" GTW
 SG_ ESP_vlvEvFrVart m16458 : 31|1@1+ (1,0) [0|0] "" GTW
 SG_ ESP_vlvEvRlFreeWhl m16458 : 32|1@1+ (1,0) [0|0] "" GTW
 SG_ ESP_vlvEvRlGen m16458 : 33|1@1+ (1,0) [0|0] "" GTW
 SG_ ESP_vlvEvRlLeakage m16458 : 34|1@1+ (1,0) [0|0] "" GTW
 SG_ ESP_vlvEvRlPwm m16458 : 35|1@1+ (1,0) [0|0] "" GTW
 SG_ ESP_vlvEvRlQx m16458 : 36|1@1+ (1,0) [0|0] "" GTW
 SG_ ESP_vlvEvRlResOutOfRange m16458 : 37|1@1+ (1,0) [0|0] "" GTW
 SG_ ESP_vlvEvRlSvdt m16458 : 38|1@1+ (1,0) [0|0] "" GTW
 SG_ ESP_vlvEvRlVart m16458 : 39|1@1+ (1,0) [0|0] "" GTW
 SG_ ESP_vlvEvRrFreeWhl m16458 : 40|1@1+ (1,0) [0|0] "" GTW
 SG_ ESP_vlvEvRrGen m16458 : 41|1@1+ (1,0) [0|0] "" GTW
 SG_ ESP_vlvEvRrLeakage m16458 : 42|1@1+ (1,0) [0|0] "" GTW
 SG_ ESP_vlvEvRrPwm m16458 : 43|1@1+ (1,0) [0|0] "" GTW
 SG_ ESP_vlvEvRrQx m16458 : 44|1@1+ (1,0) [0|0] "" GTW
 SG_ ESP_vlvEvRrResOutOfRange m16458 : 45|1@1+ (1,0) [0|0] "" GTW
 SG_ ESP_vlvEvRrSvdt m16458 : 46|1@1+ (1,0) [0|0] "" GTW
 SG_ ESP_vlvEvRrVart m16458 : 47|1@1+ (1,0) [0|0] "" GTW
 SG_ ESP_vlvHsv1FreeWhl m16459 : 16|1@1+ (1,0) [0|0] "" GTW
 SG_ ESP_vlvHsv1Gen m16459 : 17|1@1+ (1,0) [0|0] "" GTW
 SG_ ESP_vlvHsv1Leakage m16459 : 18|1@1+ (1,0) [0|0] "" GTW
 SG_ ESP_vlvHsv1Pwm m16459 : 19|1@1+ (1,0) [0|0] "" GTW
 SG_ ESP_vlvHsv1Qx m16459 : 20|1@1+ (1,0) [0|0] "" GTW
 SG_ ESP_vlvHsv1ResOutOfRange m16459 : 21|1@1+ (1,0) [0|0] "" GTW
 SG_ ESP_vlvHsv1Svdt m16459 : 22|1@1+ (1,0) [0|0] "" GTW
 SG_ ESP_vlvHsv1Vart m16459 : 23|1@1+ (1,0) [0|0] "" GTW
 SG_ ESP_vlvHsv2FreeWhl m16459 : 24|1@1+ (1,0) [0|0] "" GTW
 SG_ ESP_vlvHsv2Gen m16459 : 25|1@1+ (1,0) [0|0] "" GTW
 SG_ ESP_vlvHsv2Leakage m16459 : 26|1@1+ (1,0) [0|0] "" GTW
 SG_ ESP_vlvHsv2Pwm m16459 : 27|1@1+ (1,0) [0|0] "" GTW
 SG_ ESP_vlvHsv2Qx m16459 : 28|1@1+ (1,0) [0|0] "" GTW
 SG_ ESP_vlvHsv2ResOutOfRange m16459 : 29|1@1+ (1,0) [0|0] "" GTW
 SG_ ESP_vlvHsv2Svdt m16459 : 30|1@1+ (1,0) [0|0] "" GTW
 SG_ ESP_vlvHsv2Vart m16459 : 31|1@1+ (1,0) [0|0] "" GTW
 SG_ ESP_vlvUsv1FreeWhl m16460 : 16|1@1+ (1,0) [0|0] "" GTW
 SG_ ESP_vlvUsv1Gen m16460 : 17|1@1+ (1,0) [0|0] "" GTW
 SG_ ESP_vlvUsv1Leakage m16460 : 18|1@1+ (1,0) [0|0] "" GTW
 SG_ ESP_vlvUsv1Pwm m16460 : 19|1@1+ (1,0) [0|0] "" GTW
 SG_ ESP_vlvUsv1Qx m16460 : 20|1@1+ (1,0) [0|0] "" GTW
 SG_ ESP_vlvUsv1ResOutOfRange m16460 : 21|1@1+ (1,0) [0|0] "" GTW
 SG_ ESP_vlvUsv1Svdt m16460 : 22|1@1+ (1,0) [0|0] "" GTW
 SG_ ESP_vlvUsv1Vart m16460 : 23|1@1+ (1,0) [0|0] "" GTW
 SG_ ESP_vlvUsv1Vdc m16460 : 24|1@1+ (1,0) [0|0] "" GTW
 SG_ ESP_vlvUsv2FreeWhl m16460 : 25|1@1+ (1,0) [0|0] "" GTW
 SG_ ESP_vlvUsv2Gen m16460 : 26|1@1+ (1,0) [0|0] "" GTW
 SG_ ESP_vlvUsv2Leakage m16460 : 27|1@1+ (1,0) [0|0] "" GTW
 SG_ ESP_vlvUsv2Pwm m16460 : 28|1@1+ (1,0) [0|0] "" GTW
 SG_ ESP_vlvUsv2Qx m16460 : 29|1@1+ (1,0) [0|0] "" GTW
 SG_ ESP_vlvUsv2ResOutOfRange m16460 : 30|1@1+ (1,0) [0|0] "" GTW
 SG_ ESP_vlvUsv2Svdt m16460 : 31|1@1+ (1,0) [0|0] "" GTW
 SG_ ESP_vlvUsv2Vart m16460 : 32|1@1+ (1,0) [0|0] "" GTW
 SG_ ESP_vlvUsv2Vdc m16460 : 33|1@1+ (1,0) [0|0] "" GTW
 SG_ ESP_wssHetMonRefSigErr m16460 : 34|1@1+ (1,0) [0|0] "" GTW
 SG_ ESP_EsmNotHandledErr m16460 : 35|1@1+ (1,0) [0|0] "" GTW
 SG_ ESP_tcsRefNotInitInTime m16461 : 16|1@1+ (1,0) [0|0] "" GTW
 SG_ ESP_vdcRefNotInitInTime m16461 : 17|1@1+ (1,0) [0|0] "" GTW
 SG_ ESP_acmBtmOheatBraking m16462 : 16|1@1+ (1,0) [0|0] "" GTW
 SG_ ESP_acmBtmOverheatDeact m16462 : 17|1@1+ (1,0) [0|0] "" GTW
 SG_ ESP_varCodeEeprom m16463 : 16|1@1+ (1,0) [0|0] "" GTW
 SG_ ESP_varCodeValNotRel m16463 : 17|1@1+ (1,0) [0|0] "" GTW
 SG_ ESP_varEcuUncoded m16463 : 18|1@1+ (1,0) [0|0] "" GTW
 SG_ ESP_reverseGearHigh m16464 : 16|1@1+ (1,0) [0|0] "" GTW
 SG_ ESP_reverseGearLow m16464 : 17|1@1+ (1,0) [0|0] "" GTW
 SG_ ESP_comSclVinAllZeroFF m16465 : 16|1@1+ (1,0) [0|0] "" GTW
 SG_ ESP_comSclVip405HsImpVin m16466 : 16|1@1+ (1,0) [0|0] "" GTW
 SG_ ESP_comSclVip405HsDtCrpt m16467 : 16|1@1+ (1,0) [0|0] "" GTW
 SG_ ESP_comSclVip405HsTout m16468 : 16|1@1+ (1,0) [0|0] "" GTW
 SG_ ESP_comSclVinTout m16468 : 17|1@1+ (1,0) [0|0] "" GTW
 SG_ ESP_rollerBenchActv m16469 : 16|1@1+ (1,0) [0|0] "" GTW
 SG_ ESP_netBusOffNetwork0 m16470 : 16|1@1+ (1,0) [0|0] "" GTW
 SG_ ESP_netErrPassivNetwork0 m16470 : 17|1@1+ (1,0) [0|0] "" GTW
 SG_ ESP_netBusOffNetwork1 m16471 : 16|1@1+ (1,0) [0|0] "" GTW
 SG_ ESP_netErrPassivNetwork1 m16471 : 17|1@1+ (1,0) [0|0] "" GTW
 SG_ ESP_comSclDiBtcReqTout m16472 : 16|1@1+ (1,0) [0|0] "" GTW
 SG_ ESP_comSclDiEspConTout m16472 : 17|1@1+ (1,0) [0|0] "" GTW
 SG_ ESP_comSclDiTrq1Tout m16472 : 18|1@1+ (1,0) [0|0] "" GTW
 SG_ ESP_comSclDiTrq2Tout m16472 : 19|1@1+ (1,0) [0|0] "" GTW
 SG_ ESP_comSclDisTrq1Tout m16472 : 20|1@1+ (1,0) [0|0] "" GTW
 SG_ ESP_comSclDrsTxId1Tout m16473 : 16|1@1+ (1,0) [0|0] "" GTW
 SG_ ESP_comSclDrsTxId2Tout m16473 : 17|1@1+ (1,0) [0|0] "" GTW
 SG_ ESP_comSclDrsTxId7Tout m16473 : 18|1@1+ (1,0) [0|0] "" GTW
 SG_ ESP_comSclStwAnglhpTout m16474 : 16|1@1+ (1,0) [0|0] "" GTW
 SG_ ESP_comSclEpbStatusTout m16475 : 16|1@1+ (1,0) [0|0] "" GTW
 SG_ ESP_comSclIbEsp1Tout m16476 : 16|1@1+ (1,0) [0|0] "" GTW
 SG_ ESP_comSclIbEsp2Tout m16476 : 17|1@1+ (1,0) [0|0] "" GTW
 SG_ ESP_comSclBdyStatusTout m16477 : 16|1@1+ (1,0) [0|0] "" GTW
 SG_ ESP_comSclGtwEsp1Tout m16478 : 16|1@1+ (1,0) [0|0] "" GTW
 SG_ ESP_comSclGtwOdoTout m16479 : 16|1@1+ (1,0) [0|0] "" GTW
 SG_ ESP_comSclGtwCarCfgTout m16480 : 16|1@1+ (1,0) [0|0] "" GTW
 SG_ ESP_comSclDiReqCsumFlt m16481 : 16|1@1+ (1,0) [0|0] "" GTW
 SG_ ESP_comSclDiBtcReqDtCrpt m16481 : 17|1@1+ (1,0) [0|0] "" GTW
 SG_ ESP_comSclDiEspCsumFlt m16481 : 18|1@1+ (1,0) [0|0] "" GTW
 SG_ ESP_comSclDiEspConDtCrpt m16481 : 19|1@1+ (1,0) [0|0] "" GTW
 SG_ ESP_comSclDiTrq1CsumFlt m16481 : 20|1@1+ (1,0) [0|0] "" GTW
 SG_ ESP_comSclDiTrq1DtCrpt m16481 : 21|1@1+ (1,0) [0|0] "" GTW
 SG_ ESP_comSclDiTrq2CsumFlt m16481 : 22|1@1+ (1,0) [0|0] "" GTW
 SG_ ESP_comSclDiTrq2DtCrpt m16481 : 23|1@1+ (1,0) [0|0] "" GTW
 SG_ ESP_comSclDisTrq1CsumFlt m16481 : 24|1@1+ (1,0) [0|0] "" GTW
 SG_ ESP_comSclDisTrq1DtCrpt m16481 : 25|1@1+ (1,0) [0|0] "" GTW
 SG_ ESP_comSclDiBtcReqCntFlt m16482 : 16|1@1+ (1,0) [0|0] "" GTW
 SG_ ESP_comSclDiEspConCntFlt m16482 : 17|1@1+ (1,0) [0|0] "" GTW
 SG_ ESP_comSclDiTrq1CntFlt m16482 : 18|1@1+ (1,0) [0|0] "" GTW
 SG_ ESP_comSclDiTrq2CntFlt m16482 : 19|1@1+ (1,0) [0|0] "" GTW
 SG_ ESP_comSclDisTrq1CntFlt m16482 : 20|1@1+ (1,0) [0|0] "" GTW
 SG_ ESP_comSclDrvTrqFaInvd m16483 : 16|1@1+ (1,0) [0|0] "" GTW
 SG_ ESP_comSclDrvTrqRaInvd m16483 : 17|1@1+ (1,0) [0|0] "" GTW
 SG_ ESP_comSclMotorRpmFAInvd m16483 : 18|1@1+ (1,0) [0|0] "" GTW
 SG_ ESP_comSclMotorRpmRaInvd m16483 : 19|1@1+ (1,0) [0|0] "" GTW
 SG_ ESP_comSclMotorTrqFaInvd m16483 : 20|1@1+ (1,0) [0|0] "" GTW
 SG_ ESP_comSclMotorTrqRaInvd m16483 : 21|1@1+ (1,0) [0|0] "" GTW
 SG_ ESP_comSclPedalPosInvd m16483 : 22|1@1+ (1,0) [0|0] "" GTW
 SG_ ESP_comSclTrqIntfcInvd m16483 : 23|1@1+ (1,0) [0|0] "" GTW
 SG_ ESP_sclDiPtcStateInvd m16483 : 24|1@1+ (1,0) [0|0] "" GTW
 SG_ ESP_comSclEpbStatusCrpt m16484 : 16|1@1+ (1,0) [0|0] "" GTW
 SG_ ESP_comSclIbEsp1CsumFlt m16485 : 16|1@1+ (1,0) [0|0] "" GTW
 SG_ ESP_comSclIbEsp1DtCrpt m16485 : 17|1@1+ (1,0) [0|0] "" GTW
 SG_ ESP_comSclIbEsp2CsumFlt m16485 : 18|1@1+ (1,0) [0|0] "" GTW
 SG_ ESP_comSclIbEsp2DtCrpt m16485 : 19|1@1+ (1,0) [0|0] "" GTW
 SG_ ESP_comSclIbEsp1CntFlt m16486 : 16|1@1+ (1,0) [0|0] "" GTW
 SG_ ESP_comSclIbEsp2CntFlt m16486 : 17|1@1+ (1,0) [0|0] "" GTW
 SG_ ESP_sclIbEsp1SOtptRdInvd m16487 : 16|1@1+ (1,0) [0|0] "" GTW
 SG_ ESP_sclIbEsp2IbStatusOff m16487 : 17|1@1+ (1,0) [0|0] "" GTW
 SG_ ESP_sclIbEsp2PrunoInvd m16487 : 18|1@1+ (1,0) [0|0] "" GTW
 SG_ ESP_ibEsp2RampOffFFCBckup m16487 : 19|1@1+ (1,0) [0|0] "" GTW
 SG_ ESP_sclExtReqStatusNotAvail m16487 : 20|1@1+ (1,0) [0|0] "" GTW
 SG_ ESP_comSclBdyStatusCrpt m16488 : 16|1@1+ (1,0) [0|0] "" GTW
 SG_ ESP_comSclStwAngCsumFlt m16489 : 16|1@1+ (1,0) [0|0] "" GTW
 SG_ ESP_comSclStwAngDtCrpt m16489 : 17|1@1+ (1,0) [0|0] "" GTW
 SG_ ESP_comSclStwAngCntFlt m16490 : 16|1@1+ (1,0) [0|0] "" GTW
 SG_ ESP_sasMonMsgCnt m16490 : 17|1@1+ (1,0) [0|0] "" GTW
 SG_ ESP_comSclCanSasErr m16491 : 16|1@1+ (1,0) [0|0] "" GTW
 SG_ ESP_sasCondActvAboveThr m16491 : 17|1@1+ (1,0) [0|0] "" GTW
 SG_ ESP_comSclDrsTxID1DtCrpt m16492 : 16|1@1+ (1,0) [0|0] "" GTW
 SG_ ESP_comSclDrsTxID2DtCrpt m16492 : 17|1@1+ (1,0) [0|0] "" GTW
 SG_ ESP_comSclDrsTxID7DtCrpt m16492 : 18|1@1+ (1,0) [0|0] "" GTW
 SG_ ESP_sclMm3PwrOnMntrFlt m16493 : 16|1@1+ (1,0) [0|0] "" GTW
 SG_ ESP_sclMm3SysCfgErr m16493 : 17|1@1+ (1,0) [0|0] "" GTW
 SG_ ESP_sclMm3ScInternalFlt m16493 : 18|1@1+ (1,0) [0|0] "" GTW
 SG_ ESP_sclMm3ScOvrvoltDtctd m16493 : 19|1@1+ (1,0) [0|0] "" GTW
 SG_ ESP_sclMm3ScDtctsCrcFl m16493 : 20|1@1+ (1,0) [0|0] "" GTW
 SG_ ESP_sclMm3ScDtctsSyncFl m16493 : 21|1@1+ (1,0) [0|0] "" GTW
 SG_ ESP_sclMm3ScDtctsSyncOvr m16493 : 22|1@1+ (1,0) [0|0] "" GTW
 SG_ ESP_sclMm3ScDtctsSyncUnd m16493 : 23|1@1+ (1,0) [0|0] "" GTW
 SG_ ESP_sclMm3ScUndvoltDtctd m16493 : 24|1@1+ (1,0) [0|0] "" GTW
 SG_ ESP_comSclGtwEsp1CsumFlt m16494 : 16|1@1+ (1,0) [0|0] "" GTW
 SG_ ESP_comSclGtwEsp1DtCrpt m16494 : 17|1@1+ (1,0) [0|0] "" GTW
 SG_ ESP_comSclGtwEsp1CntFlt m16495 : 16|1@1+ (1,0) [0|0] "" GTW
 SG_ ESP_comSclGtwOdoDtCrpt m16496 : 16|1@1+ (1,0) [0|0] "" GTW
 SG_ ESP_comSclGtwCrCfgDtCrpt m16497 : 16|1@1+ (1,0) [0|0] "" GTW
 SG_ ESP_teslaChassisTypeSna m16498 : 16|1@1+ (1,0) [0|0] "" GTW
 SG_ ESP_varPlatCalMismtch m16499 : 16|1@1+ (1,0) [0|0] "" GTW
 SG_ ESP_ptsBlsStatusInvd m16500 : 16|1@1+ (1,0) [0|0] "" GTW
 SG_ ESP_comSclBdwReqInvalid m16501 : 16|1@1+ (1,0) [0|0] "" GTW
 SG_ ESP_rcmAx1SignalFail m16502 : 16|1@1+ (1,0) [0|0] "" GTW
 SG_ ESP_rcmAx1SensNotAvail m16502 : 17|1@1+ (1,0) [0|0] "" GTW
 SG_ ESP_rcmAx1InitFail m16502 : 18|1@1+ (1,0) [0|0] "" GTW
 SG_ ESP_rcmAx1InvalidValue m16502 : 19|1@1+ (1,0) [0|0] "" GTW
 SG_ ESP_rcmAx1AlternateFlt m16502 : 20|1@1+ (1,0) [0|0] "" GTW
 SG_ ESP_rcmAy1SignalFail m16503 : 16|1@1+ (1,0) [0|0] "" GTW
 SG_ ESP_rcmAy1SensNotAvail m16503 : 17|1@1+ (1,0) [0|0] "" GTW
 SG_ ESP_rcmAy1InitFail m16503 : 18|1@1+ (1,0) [0|0] "" GTW
 SG_ ESP_rcmAy1InvalidValue m16503 : 19|1@1+ (1,0) [0|0] "" GTW
 SG_ ESP_rcmAy1AlternateFlt m16503 : 20|1@1+ (1,0) [0|0] "" GTW
 SG_ ESP_rcmYaw1SignalFail m16504 : 16|1@1+ (1,0) [0|0] "" GTW
 SG_ ESP_rcmYaw1SensNotAvail m16504 : 17|1@1+ (1,0) [0|0] "" GTW
 SG_ ESP_rcmYaw1InitFail m16504 : 18|1@1+ (1,0) [0|0] "" GTW
 SG_ ESP_rcmYaw1InvalidVal m16504 : 19|1@1+ (1,0) [0|0] "" GTW
 SG_ ESP_rcmYaw1AlternateFlt m16504 : 20|1@1+ (1,0) [0|0] "" GTW
 SG_ ESP_comSclTxId7CsumFlt m16505 : 16|1@1+ (1,0) [0|0] "" GTW
 SG_ ESP_comSclTxId7DtCrpt m16505 : 17|1@1+ (1,0) [0|0] "" GTW
 SG_ ESP_comSclTxId2CsumFlt m16505 : 18|1@1+ (1,0) [0|0] "" GTW
 SG_ ESP_comSclTxId2DtCrpt m16505 : 19|1@1+ (1,0) [0|0] "" GTW
 SG_ ESP_comSclTxId1CsumFlt m16505 : 20|1@1+ (1,0) [0|0] "" GTW
 SG_ ESP_comSclTxId1DtCrpt m16505 : 21|1@1+ (1,0) [0|0] "" GTW
 SG_ ESP_comSclTxId7CntFlt m16506 : 16|1@1+ (1,0) [0|0] "" GTW
 SG_ ESP_comSclTxId2CntFlt m16506 : 17|1@1+ (1,0) [0|0] "" GTW
 SG_ ESP_comSclTxId1CntFlt m16506 : 18|1@1+ (1,0) [0|0] "" GTW
 SG_ ESP_comSclTxId7Tout m16507 : 16|1@1+ (1,0) [0|0] "" GTW
 SG_ ESP_comSclTxId2Tout m16507 : 17|1@1+ (1,0) [0|0] "" GTW
 SG_ ESP_comSclTxId1Tout m16507 : 18|1@1+ (1,0) [0|0] "" GTW
 SG_ ESP_rcmSensorInfoTout m16508 : 16|1@1+ (1,0) [0|0] "" GTW
 SG_ ESP_rcmSerialNumChanged m16509 : 16|1@1+ (1,0) [0|0] "" GTW
 SG_ ESP_rcmBothFramesReceived m16510 : 16|1@1+ (1,0) [0|0] "" GTW
 SG_ ESP_rcmNoFramesReceived m16510 : 17|1@1+ (1,0) [0|0] "" GTW
 SG_ ESP_rcmCalibInvValueFlt m16511 : 16|1@1+ (1,0) [0|0] "" GTW
 SG_ ESP_rcmCalibOffsPlausFlt m16511 : 17|1@1+ (1,0) [0|0] "" GTW
 SG_ ESP_comSclPmState2TOut m16512 : 16|1@1+ (1,0) [0|0] "" GTW
 SG_ ESP_sclBdwReqActiveInvd m16513 : 16|1@1+ (1,0) [0|0] "" GTW
 SG_ ESP_comSclPmState2CsumFlt m16514 : 16|1@1+ (1,0) [0|0] "" GTW
 SG_ ESP_comSclPmState2DtCrpt m16514 : 17|1@1+ (1,0) [0|0] "" GTW
 SG_ ESP_comSclPmState2CntFlt m16515 : 16|1@1+ (1,0) [0|0] "" GTW
 SG_ ESP_sclPmEbrCmdStateInvd m16516 : 16|1@1+ (1,0) [0|0] "" GTW
 SG_ ESP_acmVsSignalPlaus m16517 : 16|1@1+ (1,0) [0|0] "" GTW
 SG_ ESP_sasMonRange m16518 : 16|1@1+ (1,0) [0|0] "" GTW
 SG_ ESP_sasMonGrad m16519 : 16|1@1+ (1,0) [0|0] "" GTW
 SG_ ESP_yrsMonRangeDriving m16520 : 16|1@1+ (1,0) [0|0] "" GTW
 SG_ ESP_yrsMonRangeStandstill m16520 : 17|1@1+ (1,0) [0|0] "" GTW
 SG_ ESP_yrsMonGrad m16521 : 16|1@1+ (1,0) [0|0] "" GTW
 SG_ ESP_yrsOffset1 m16522 : 16|1@1+ (1,0) [0|0] "" GTW
 SG_ ESP_yrsOffset2 m16522 : 17|1@1+ (1,0) [0|0] "" GTW
 SG_ ESP_yrsGain m16522 : 18|1@1+ (1,0) [0|0] "" GTW
 SG_ ESP_yrsNormalOffset m16522 : 19|1@1+ (1,0) [0|0] "" GTW
 SG_ ESP_yrsStandstillComp m16522 : 20|1@1+ (1,0) [0|0] "" GTW
 SG_ ESP_evpFault m16523 : 16|1@1+ (1,0) [0|0] "" GTW
 SG_ ESP_vamEvpRuntimeFault m16523 : 17|1@1+ (1,0) [0|0] "" GTW
 SG_ ESP_acmVsBoosterLowVac m16524 : 16|1@1+ (1,0) [0|0] "" GTW
 SG_ ESP_acmVsLowVacHbcOff m16524 : 17|1@1+ (1,0) [0|0] "" GTW
 SG_ ESP_vamLowVacEvp m16524 : 18|1@1+ (1,0) [0|0] "" GTW
 SG_ ESP_vacFrntAdcSlftestErr m16525 : 16|1@1+ (1,0) [0|0] "" GTW
 SG_ ESP_vacFrntChamberLine m16525 : 17|1@1+ (1,0) [0|0] "" GTW
 SG_ ESP_vacSupply m16525 : 18|1@1+ (1,0) [0|0] "" GTW
 SG_ ESP_vacSupplyUndervolt m16525 : 19|1@1+ (1,0) [0|0] "" GTW
 SG_ ESP_cubasCanEHwError m16526 : 16|1@1+ (1,0) [0|0] "" GTW
 SG_ ESP_cubasCanETimeout m16526 : 17|1@1+ (1,0) [0|0] "" GTW
 SG_ ESP_cubasEPduInstLost m16526 : 18|1@1+ (1,0) [0|0] "" GTW
 SG_ ESP_mcuChassisContrDtCrpt m16527 : 16|1@1+ (1,0) [0|0] "" GTW
 SG_ ESP_mcuChassisContrTout m16528 : 16|1@1+ (1,0) [0|0] "" GTW

BO_ 1606 ESP_bootID: 8 ESP
 SG_ ESP_bootIdData : 0|64@1+ (1,0) [0|0] "" GTW

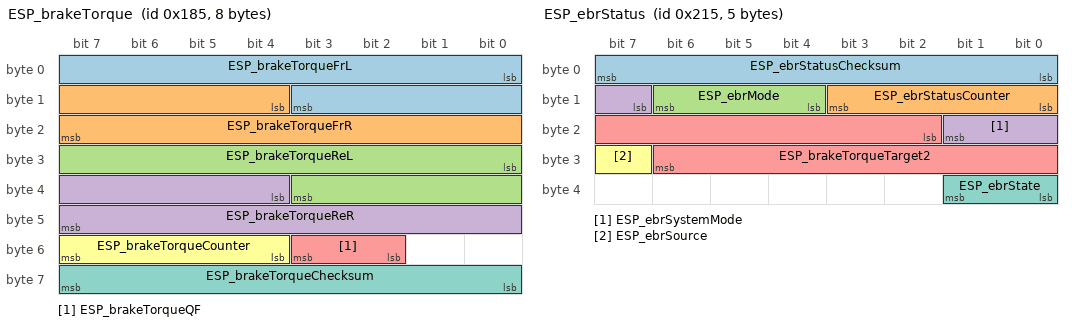
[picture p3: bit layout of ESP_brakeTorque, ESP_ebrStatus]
BO_ 389 ESP_brakeTorque: 8 ESP
 SG_ ESP_brakeTorqueFrL : 0|12@1+ (2,0) [0|8190] "Nm" GTW,TAS2
 SG_ ESP_brakeTorqueFrR : 12|12@1+ (2,0) [0|8190] "Nm" GTW,TAS2
 SG_ ESP_brakeTorqueReL : 24|12@1+ (2,0) [0|8190] "Nm" GTW,TAS2
 SG_ ESP_brakeTorqueReR : 36|12@1+ (2,0) [0|8190] "Nm" GTW,TAS2
 SG_ ESP_brakeTorqueQF : 50|2@1+ (1,0) [0|3] "" GTW,TAS2
 SG_ ESP_brakeTorqueCounter : 52|4@1+ (1,0) [0|0] "" GTW,TAS2
 SG_ ESP_brakeTorqueChecksum : 56|8@1+ (1,0) [0|0] "" GTW,TAS2

BO_ 949 ESP_dtcMatrix: 8 ESP
 SG_ ESP_dtcIndex M : 0|8@1+ (1,0) [0|255] "" GTW
 SG_ ESP_d000_absPumpMotorControl m0 : 8|2@1+ (1,0) [0|0] "" GTW
 SG_ ESP_d001_wssFLLineGnd m0 : 10|2@1+ (1,0) [0|0] "" GTW
 SG_ ESP_d002_wssFLLineHigh m0 : 12|2@1+ (1,0) [0|0] "" GTW
 SG_ ESP_d003_wssFLLineUndef m0 : 14|2@1+ (1,0) [0|0] "" GTW
 SG_ ESP_d004_wssFLOutOfRange m0 : 16|2@1+ (1,0) [0|0] "" GTW
 SG_ ESP_d005_wssFLSignalMissing m0 : 18|2@1+ (1,0) [0|0] "" GTW
 SG_ ESP_d006_wssFLWrongSen m0 : 20|2@1+ (1,0) [0|0] "" GTW
 SG_ ESP_d007_wssFLPlausibility m0 : 22|2@1+ (1,0) [0|0] "" GTW
 SG_ ESP_d008_wssFAWrongMounting m0 : 24|2@1+ (1,0) [0|0] "" GTW
 SG_ ESP_d009_wssFLAirGap m0 : 26|2@1+ (1,0) [0|0] "" GTW
 SG_ ESP_d010_wssFLSupGnd m0 : 28|2@1+ (1,0) [0|0] "" GTW
 SG_ ESP_d011_wssTstFLFld m0 : 30|2@1+ (1,0) [0|0] "" GTW
 SG_ ESP_d012_wssFRLineGnd m0 : 32|2@1+ (1,0) [0|0] "" GTW
 SG_ ESP_d013_wssFRLineHigh m0 : 34|2@1+ (1,0) [0|0] "" GTW
 SG_ ESP_d014_wssFRLineUndef m0 : 36|2@1+ (1,0) [0|0] "" GTW
 SG_ ESP_d015_wssFROutOfRange m0 : 38|2@1+ (1,0) [0|0] "" GTW
 SG_ ESP_d016_wssFRSignalMissing m0 : 40|2@1+ (1,0) [0|0] "" GTW
 SG_ ESP_d017_wssFRWrongSen m0 : 42|2@1+ (1,0) [0|0] "" GTW
 SG_ ESP_d018_wssFRPlausibility m0 : 44|2@1+ (1,0) [0|0] "" GTW
 SG_ ESP_d019_wssMonWheelDirFR m0 : 46|2@1+ (1,0) [0|0] "" GTW
 SG_ ESP_d020_wssFRAirGap m0 : 48|2@1+ (1,0) [0|0] "" GTW
 SG_ ESP_d021_wssFRSupGnd m0 : 50|2@1+ (1,0) [0|0] "" GTW
 SG_ ESP_d022_wssTstFRFld m0 : 52|2@1+ (1,0) [0|0] "" GTW
 SG_ ESP_d023_wssRLLineGnd m0 : 54|2@1+ (1,0) [0|0] "" GTW
 SG_ ESP_d024_wssRLLineHigh m0 : 56|2@1+ (1,0) [0|0] "" GTW
 SG_ ESP_d025_wssRLLineUndef m0 : 58|2@1+ (1,0) [0|0] "" GTW
 SG_ ESP_d026_wssRLOutOfRange m0 : 60|2@1+ (1,0) [0|0] "" GTW
 SG_ ESP_d027_wssRLSignalMissing m0 : 62|2@1+ (1,0) [0|0] "" GTW
 SG_ ESP_d028_wssRLWrongSen m1 : 8|2@1+ (1,0) [0|0] "" GTW
 SG_ ESP_d029_wssRLPlausibility m1 : 10|2@1+ (1,0) [0|0] "" GTW
 SG_ ESP_d030_wssRAWrongMounting m1 : 12|2@1+ (1,0) [0|0] "" GTW
 SG_ ESP_d031_wssRLAirGap m1 : 14|2@1+ (1,0) [0|0] "" GTW
 SG_ ESP_d032_wssRLSupGnd m1 : 16|2@1+ (1,0) [0|0] "" GTW
 SG_ ESP_d033_wssTstRLFld m1 : 18|2@1+ (1,0) [0|0] "" GTW
 SG_ ESP_d034_wssRRLineGnd m1 : 20|2@1+ (1,0) [0|0] "" GTW
 SG_ ESP_d035_wssRRLineHigh m1 : 22|2@1+ (1,0) [0|0] "" GTW
 SG_ ESP_d036_wssRRLineUndef m1 : 24|2@1+ (1,0) [0|0] "" GTW
 SG_ ESP_d037_wssRROutOfRange m1 : 26|2@1+ (1,0) [0|0] "" GTW
 SG_ ESP_d038_wssRRSignalMissing m1 : 28|2@1+ (1,0) [0|0] "" GTW
 SG_ ESP_d039_wssRRWrongSen m1 : 30|2@1+ (1,0) [0|0] "" GTW
 SG_ ESP_d040_wssRRPlausibility m1 : 32|2@1+ (1,0) [0|0] "" GTW
 SG_ ESP_d041_wssMonWheelDirRR m1 : 34|2@1+ (1,0) [0|0] "" GTW
 SG_ ESP_d042_wssRRAirGap m1 : 36|2@1+ (1,0) [0|0] "" GTW
 SG_ ESP_d043_wssRRSupGnd m1 : 38|2@1+ (1,0) [0|0] "" GTW
 SG_ ESP_d044_wssTstRRFld m1 : 40|2@1+ (1,0) [0|0] "" GTW
 SG_ ESP_d045_wssGeneralFault m1 : 42|2@1+ (1,0) [0|0] "" GTW
 SG_ ESP_d046_brakeSwitchStuckHigh m1 : 44|2@1+ (1,0) [0|0] "" GTW
 SG_ ESP_d047_blsStatusInvd m1 : 46|2@1+ (1,0) [0|0] "" GTW
 SG_ ESP_d048_brakeSwitchPlausib m1 : 48|2@1+ (1,0) [0|0] "" GTW
 SG_ ESP_d049_pressSenMc1Line m1 : 50|2@1+ (1,0) [0|0] "" GTW
 SG_ ESP_d050_acmPsOfstMc1 m1 : 52|2@1+ (1,0) [0|0] "" GTW
 SG_ ESP_d051_acmPsTstpulseMc1 m1 : 54|2@1+ (1,0) [0|0] "" GTW
 SG_ ESP_d052_comSclLowBrakeFluid m1 : 56|2@1+ (1,0) [0|0] "" GTW
 SG_ ESP_d053_sasMonConstSig m1 : 58|2@1+ (1,0) [0|0] "" GTW
 SG_ ESP_d054_sasMonOfst m1 : 60|2@1+ (1,0) [0|0] "" GTW
 SG_ ESP_d055_sasPlausibility m1 : 62|2@1+ (1,0) [0|0] "" GTW
 SG_ ESP_d056_aySensorFault m2 : 8|2@1+ (1,0) [0|0] "" GTW
 SG_ ESP_d057_aysMonRange m2 : 10|2@1+ (1,0) [0|0] "" GTW
 SG_ ESP_d058_aysOffset m2 : 12|2@1+ (1,0) [0|0] "" GTW
 SG_ ESP_d059_aysPlaus m2 : 14|2@1+ (1,0) [0|0] "" GTW
 SG_ ESP_d060_axSensorFault m2 : 16|2@1+ (1,0) [0|0] "" GTW
 SG_ ESP_d061_axsMonRange m2 : 18|2@1+ (1,0) [0|0] "" GTW
 SG_ ESP_d062_axOffsTooLarge m2 : 20|2@1+ (1,0) [0|0] "" GTW
 SG_ ESP_d063_axSensorPlaus m2 : 22|2@1+ (1,0) [0|0] "" GTW
 SG_ ESP_d064_yawSensorFault m2 : 24|2@1+ (1,0) [0|0] "" GTW
 SG_ ESP_d065_yawSensorPlaus m2 : 26|2@1+ (1,0) [0|0] "" GTW
 SG_ ESP_d066_absVdcContControl m2 : 28|2@1+ (1,0) [0|0] "" GTW
 SG_ ESP_d067_undervoltage m2 : 30|2@1+ (1,0) [0|0] "" GTW
 SG_ ESP_d068_overvoltage m2 : 32|2@1+ (1,0) [0|0] "" GTW
 SG_ ESP_d069_memoryFault m2 : 34|2@1+ (1,0) [0|0] "" GTW
 SG_ ESP_d070_ecuInternalGeneric m2 : 36|2@1+ (1,0) [0|0] "" GTW
 SG_ ESP_d071_ecuInternalEcu m2 : 38|2@1+ (1,0) [0|0] "" GTW
 SG_ ESP_d072_valveGeneric m2 : 40|2@1+ (1,0) [0|0] "" GTW
 SG_ ESP_d073_valveAvFaults m2 : 42|2@1+ (1,0) [0|0] "" GTW
 SG_ ESP_d074_valveEvFaults m2 : 44|2@1+ (1,0) [0|0] "" GTW
 SG_ ESP_d075_valveHsvFaults m2 : 46|2@1+ (1,0) [0|0] "" GTW
 SG_ ESP_d076_valveUsvFaults m2 : 48|2@1+ (1,0) [0|0] "" GTW
 SG_ ESP_d077_refNotInitInTime m2 : 50|2@1+ (1,0) [0|0] "" GTW
 SG_ ESP_d078_acmBtmOheatBraking m2 : 52|2@1+ (1,0) [0|0] "" GTW
 SG_ ESP_d079_varCodeEeprom m2 : 54|2@1+ (1,0) [0|0] "" GTW
 SG_ ESP_d080_reverseGearPlaus m2 : 56|2@1+ (1,0) [0|0] "" GTW
 SG_ ESP_d081_comSclVinAllZeroFF m2 : 58|2@1+ (1,0) [0|0] "" GTW
 SG_ ESP_d082_comSclVip405HsImpVin m2 : 60|2@1+ (1,0) [0|0] "" GTW
 SG_ ESP_d083_comSclVip405HsDtCrpt m2 : 62|2@1+ (1,0) [0|0] "" GTW
 SG_ ESP_d084_comSclVip405HsTout m3 : 8|2@1+ (1,0) [0|0] "" GTW
 SG_ ESP_d085_rollerBenchActv m3 : 10|2@1+ (1,0) [0|0] "" GTW
 SG_ ESP_d086_network0 m3 : 12|2@1+ (1,0) [0|0] "" GTW
 SG_ ESP_d087_network1 m3 : 14|2@1+ (1,0) [0|0] "" GTW
 SG_ ESP_d088_comMotorTOut m3 : 16|2@1+ (1,0) [0|0] "" GTW
 SG_ ESP_d089_comDrsTxTOut m3 : 18|2@1+ (1,0) [0|0] "" GTW
 SG_ ESP_d090_comSclStwAnglhpTout m3 : 20|2@1+ (1,0) [0|0] "" GTW
 SG_ ESP_d091_comSclEpbStatusTout m3 : 22|2@1+ (1,0) [0|0] "" GTW
 SG_ ESP_d092_comIbEsptTOut m3 : 24|2@1+ (1,0) [0|0] "" GTW
 SG_ ESP_d093_comSclBdyStatusTout m3 : 26|2@1+ (1,0) [0|0] "" GTW
 SG_ ESP_d094_comSclGtwEsp1Tout m3 : 28|2@1+ (1,0) [0|0] "" GTW
 SG_ ESP_d095_comSclGtwOdoTout m3 : 30|2@1+ (1,0) [0|0] "" GTW
 SG_ ESP_d096_comSclGtwCarCfgTout m3 : 32|2@1+ (1,0) [0|0] "" GTW
 SG_ ESP_d097_comMotorCrpt m3 : 34|2@1+ (1,0) [0|0] "" GTW
 SG_ ESP_d098_comMotorMsgCount m3 : 36|2@1+ (1,0) [0|0] "" GTW
 SG_ ESP_d099_comMotorInvalidSig m3 : 38|2@1+ (1,0) [0|0] "" GTW
 SG_ ESP_d100_comSclEpbStatusCrpt m3 : 40|2@1+ (1,0) [0|0] "" GTW
 SG_ ESP_d101_comIbEspCrpt m3 : 42|2@1+ (1,0) [0|0] "" GTW
 SG_ ESP_d102_comIbEspMsgCount m3 : 44|2@1+ (1,0) [0|0] "" GTW
 SG_ ESP_d103_sclIbEspInvalidSig m3 : 46|2@1+ (1,0) [0|0] "" GTW
 SG_ ESP_d104_comSclBdyStatusCrpt m3 : 48|2@1+ (1,0) [0|0] "" GTW
 SG_ ESP_d105_comStwAnglHpCrpt m3 : 50|2@1+ (1,0) [0|0] "" GTW
 SG_ ESP_d106_comStwAnglHpMsgCount m3 : 52|2@1+ (1,0) [0|0] "" GTW
 SG_ ESP_d107_comSasInvalidSig m3 : 54|2@1+ (1,0) [0|0] "" GTW
 SG_ ESP_d108_comDrsTxCrpt m3 : 56|2@1+ (1,0) [0|0] "" GTW
 SG_ ESP_d109_sclMm3InvalidSig m3 : 58|2@1+ (1,0) [0|0] "" GTW
 SG_ ESP_d110_comGtwEsp1Crpt m3 : 60|2@1+ (1,0) [0|0] "" GTW
 SG_ ESP_d111_comSclGtwEsp1CntFlt m3 : 62|2@1+ (1,0) [0|0] "" GTW
 SG_ ESP_d112_comSclGtwOdoDtCrpt m4 : 8|2@1+ (1,0) [0|0] "" GTW
 SG_ ESP_d113_comSclGtwCrCfgDtCrpt m4 : 10|2@1+ (1,0) [0|0] "" GTW
 SG_ ESP_d114_teslaChassisTypeSna m4 : 12|2@1+ (1,0) [0|0] "" GTW
 SG_ ESP_d115_varPlatCalMismtch m4 : 14|2@1+ (1,0) [0|0] "" GTW
 SG_ ESP_d116_ptsBlsStatusInvd m4 : 16|2@1+ (1,0) [0|0] "" GTW
 SG_ ESP_d117_comSclBdwReqInvalid m4 : 18|2@1+ (1,0) [0|0] "" GTW
 SG_ ESP_d118_rcmInvalidAx m4 : 20|2@1+ (1,0) [0|0] "" GTW
 SG_ ESP_d119_rcmInvalidAy m4 : 22|2@1+ (1,0) [0|0] "" GTW
 SG_ ESP_d120_rcmInvalidYaw m4 : 24|2@1+ (1,0) [0|0] "" GTW
 SG_ ESP_d121_rcmInvalidFrame1 m4 : 26|2@1+ (1,0) [0|0] "" GTW
 SG_ ESP_d122_rcmInvalidFrame2 m4 : 28|2@1+ (1,0) [0|0] "" GTW
 SG_ ESP_d123_rcmLostComm m4 : 30|2@1+ (1,0) [0|0] "" GTW
 SG_ ESP_d124_rcmIncompleteSensInfo m4 : 32|2@1+ (1,0) [0|0] "" GTW
 SG_ ESP_d125_rcmSerialNumMismatch m4 : 34|2@1+ (1,0) [0|0] "" GTW
 SG_ ESP_d126_rcmWrongSensorConfig m4 : 36|2@1+ (1,0) [0|0] "" GTW
 SG_ ESP_d127_rcmInvalidCalibration m4 : 38|2@1+ (1,0) [0|0] "" GTW
 SG_ ESP_d128_comSclPmState2TOut m4 : 40|2@1+ (1,0) [0|0] "" GTW
 SG_ ESP_d129_sclBdwReqActiveInvd m4 : 42|2@1+ (1,0) [0|0] "" GTW
 SG_ ESP_d130_comPmState2Crpt m4 : 44|2@1+ (1,0) [0|0] "" GTW
 SG_ ESP_d131_comSclPmState2CntFlt m4 : 46|2@1+ (1,0) [0|0] "" GTW
 SG_ ESP_d132_sclPmEbrCmdStateInvd m4 : 48|2@1+ (1,0) [0|0] "" GTW
 SG_ ESP_d133_acmVsSignalPlaus m5 : 8|2@1+ (1,0) [0|0] "" GTW
 SG_ ESP_d134_sasMonRange m5 : 10|2@1+ (1,0) [0|0] "" GTW
 SG_ ESP_d135_sasMonGrad m5 : 12|2@1+ (1,0) [0|0] "" GTW
 SG_ ESP_d136_yrsSignalOutOfRange m5 : 14|2@1+ (1,0) [0|0] "" GTW
 SG_ ESP_d137_yrsMonGrad m5 : 16|2@1+ (1,0) [0|0] "" GTW
 SG_ ESP_d138_yrsOffsetTooLarge m5 : 18|2@1+ (1,0) [0|0] "" GTW
 SG_ ESP_d139_evpSigPlausibility m5 : 20|2@1+ (1,0) [0|0] "" GTW
 SG_ ESP_d140_evpVacSigLow m5 : 22|2@1+ (1,0) [0|0] "" GTW
 SG_ ESP_d141_vacSensorElectFail m5 : 24|2@1+ (1,0) [0|0] "" GTW
 SG_ ESP_d142_canCommGeneral m5 : 26|2@1+ (1,0) [0|0] "" GTW
 SG_ ESP_d143_mcuChassisContrDtCrpt m5 : 28|2@1+ (1,0) [0|0] "" GTW
 SG_ ESP_d144_mcuChassisContrTout m5 : 30|2@1+ (1,0) [0|0] "" GTW

BO_ 533 ESP_ebrStatus: 5 ESP
 SG_ ESP_ebrStatusChecksum : 0|8@1+ (1,0) [0|255] "" GTW
 SG_ ESP_ebrStatusCounter : 8|4@1+ (1,0) [0|15] "" GTW
 SG_ ESP_ebrMode : 12|3@1+ (1,0) [0|7] "" GTW
 SG_ ESP_ebrSystemMode : 15|3@1+ (1,0) [0|7] "" GTW
 SG_ ESP_brakeTorqueTarget2 : 18|13@1+ (2,0) [0|16382] "Nm" GTW
 SG_ ESP_ebrSource : 31|1@1+ (1,0) [0|2] "" GTW
 SG_ ESP_ebrState : 32|2@1+ (1,0) [0|3] "" GTW

BO_ 805 ESP_info: 8 ESP
 SG_ ESP_infoIndex M : 0|8@1+ (1,0) [0|255] "" GTW
 SG_ ESP_buildType m10 : 8|8@1+ (1,0) [0|255] "" GTW
 SG_ ESP_componentId m10 : 48|16@1+ (1,0) [0|65535] "" GTW
 SG_ ESP_pcbaId m11 : 16|8@1+ (1,0) [0|0] "" GTW
 SG_ ESP_assemblyId m11 : 24|8@1+ (1,0) [0|0] "" GTW
 SG_ ESP_usageId m11 : 32|16@1+ (1,0) [0|0] "" GTW
 SG_ ESP_applicationCrc m13 : 32|32@1+ (1,0) [0|0] "" GTW
 SG_ ESP_vehicleVariant m16 : 16|8@1+ (1,0) [0|0] "" GTW
 SG_ ESP_udsProtocolVersion m20 : 8|8@1+ (1,0) [0|0] "" GTW
 SG_ ESP_bootloaderCrc m20 : 32|32@1+ (1,0) [0|0] "" GTW
 SG_ ESP_variantCrc m22 : 32|32@1+ (1,0) [0|0] "" GTW,GTWU

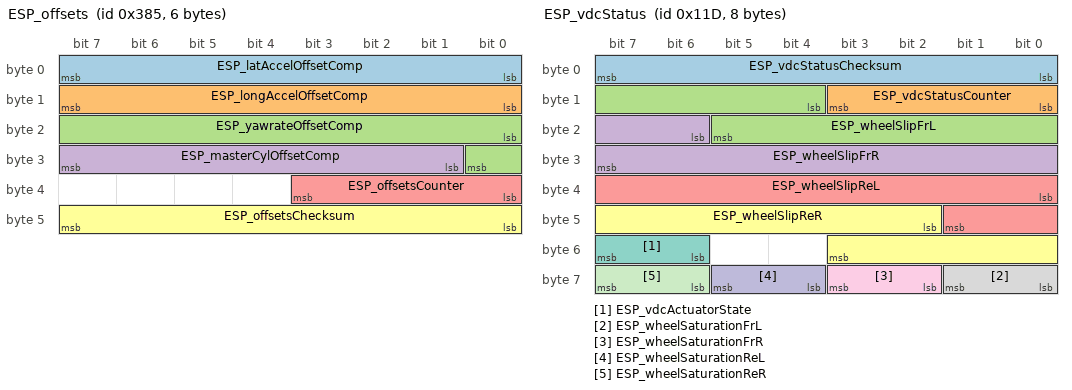
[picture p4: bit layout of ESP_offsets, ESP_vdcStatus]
BO_ 901 ESP_offsets: 6 ESP
 SG_ ESP_latAccelOffsetComp : 0|8@1+ (0.02,-2.25) [-2.25|2.25] "m/s^2" GTW
 SG_ ESP_longAccelOffsetComp : 8|8@1+ (0.02,-2.25) [-2.25|2.25] "m/s^2" GTW
 SG_ ESP_yawrateOffsetComp : 16|9@1+ (0.0009765625,-0.24) [-0.24|0.24] "rad/s" GTW
 SG_ ESP_masterCylOffsetComp : 25|7@1+ (0.25,-16) [-16|15.75] "bar" GTW
 SG_ ESP_offsetsCounter : 32|4@1+ (1,0) [0|0] "" GTW
 SG_ ESP_offsetsChecksum : 40|8@1+ (1,0) [0|0] "" GTW

BO_ 1621 ESP_udsResponse: 8 ESP
 SG_ ESP_udsResponse : 7|64@0+ (1,0) [0|0] "" GTW,GTWU

BO_ 285 ESP_vdcStatus: 8 ESP
 SG_ ESP_vdcStatusChecksum : 0|8@1+ (1,0) [0|0] "" GTW
 SG_ ESP_vdcStatusCounter : 8|4@1+ (1,0) [0|0] "" GTW
 SG_ ESP_wheelSlipFrL : 12|10@1+ (0.001,0) [0|1] "1" GTW
 SG_ ESP_wheelSlipFrR : 22|10@1+ (0.001,0) [0|1] "1" GTW
 SG_ ESP_wheelSlipReL : 32|10@1+ (0.001,0) [0|1] "1" GTW
 SG_ ESP_wheelSlipReR : 42|10@1+ (0.001,0) [0|1] "1" GTW
 SG_ ESP_vdcActuatorState : 54|2@1+ (1,0) [0|0] "" GTW
 SG_ ESP_wheelSaturationFrL : 56|2@1+ (1,0) [0|0] "" GTW
 SG_ ESP_wheelSaturationFrR : 58|2@1+ (1,0) [0|0] "" GTW
 SG_ ESP_wheelSaturationReL : 60|2@1+ (1,0) [0|0] "" GTW
 SG_ ESP_wheelSaturationReR : 62|2@1+ (1,0) [0|0] "" GTW

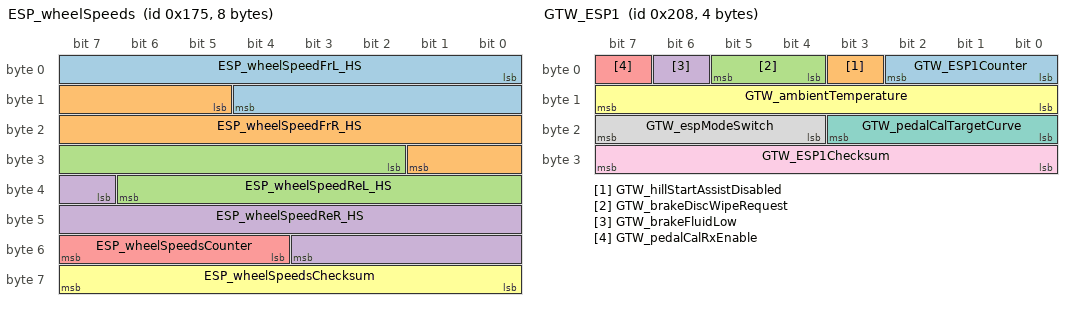
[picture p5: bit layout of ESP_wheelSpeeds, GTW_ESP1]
BO_ 373 ESP_wheelSpeeds: 8 ESP
 SG_ ESP_wheelSpeedFrL_HS : 0|13@1+ (0.04,0) [0|327.64] "km/h" GTW,PARK,RADAR,EPAS,EPB,EPBM,APS,APP,TAS2
 SG_ ESP_wheelSpeedFrR_HS : 13|13@1+ (0.04,0) [0|327.64] "km/h" GTW,PARK,RADAR,EPAS,EPB,EPBM,APS,APP,TAS2
 SG_ ESP_wheelSpeedReL_HS : 26|13@1+ (0.04,0) [0|327.64] "km/h" GTW,PARK,RADAR,EPAS,EPB,EPBM,APS,APP,TAS2
 SG_ ESP_wheelSpeedReR_HS : 39|13@1+ (0.04,0) [0|327.64] "km/h" GTW,PARK,RADAR,EPAS,EPB,EPBM,APS,APP,TAS2
 SG_ ESP_wheelSpeedsCounter : 52|4@1+ (1,0) [0|0] "" GTW,PARK,DAS,EPAS,APS,TAS2
 SG_ ESP_wheelSpeedsChecksum : 56|8@1+ (1,0) [0|0] "" GTW,PARK,EPAS,APS,TAS2

BO_ 520 GTW_ESP1: 4 GTW
 SG_ GTW_ESP1Counter : 0|3@1+ (1,0) [0|1] "" IBST,ESP,TAS
 SG_ GTW_hillStartAssistDisabled : 3|1@1+ (1,0) [0|0] "" ESP
 SG_ GTW_brakeDiscWipeRequest : 4|2@1+ (1,0) [0|0] "" ESP
 SG_ GTW_brakeFluidLow : 6|1@1+ (1,0) [0|0] "" ESP
 SG_ GTW_pedalCalRxEnable : 7|1@1+ (1,0) [0|1] "" IBST
 SG_ GTW_ambientTemperature : 8|8@1+ (0.5,-40) [-40|60] "dgr. Celsius" BDY,BCCEN,ESP,TAS
 SG_ GTW_pedalCalTargetCurve : 16|4@1+ (1,0) [0|15] "" IBST
 SG_ GTW_espModeSwitch : 20|4@1+ (1,0) [0|15] "" ESP
 SG_ GTW_ESP1Checksum : 24|8@1+ (1,0) [0|0] "" IBST,ESP,TAS

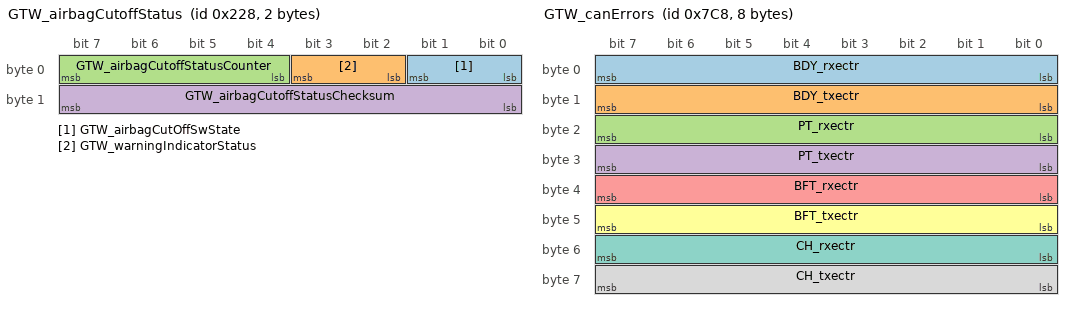
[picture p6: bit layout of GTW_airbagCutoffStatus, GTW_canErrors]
BO_ 552 GTW_airbagCutoffStatus: 2 GTW
 SG_ GTW_airbagCutOffSwState : 0|2@1+ (1,0) [0|3] "" SDM,RCM
 SG_ GTW_warningIndicatorStatus : 2|2@1+ (1,0) [0|3] "" SDM,RCM
 SG_ GTW_airbagCutoffStatusCounter : 4|4@1+ (1,0) [0|15] "" SDM,RCM
 SG_ GTW_airbagCutoffStatusChecksum : 8|8@1+ (1,0) [0|255] "" SDM,RCM

BO_ 1992 GTW_canErrors: 8 GTW
 SG_ BDY_rxectr : 0|8@1+ (1,0) [0|0] "" Vector__XXX
 SG_ BDY_txectr : 8|8@1+ (1,0) [0|0] "" Vector__XXX
 SG_ PT_rxectr : 16|8@1+ (1,0) [0|0] "" Vector__XXX
 SG_ PT_txectr : 24|8@1+ (1,0) [0|0] "" Vector__XXX
 SG_ BFT_rxectr : 32|8@1+ (1,0) [0|0] "" Vector__XXX
 SG_ BFT_txectr : 40|8@1+ (1,0) [0|0] "" Vector__XXX
 SG_ CH_rxectr : 48|8@1+ (1,0) [0|0] "" Vector__XXX
 SG_ CH_txectr : 56|8@1+ (1,0) [0|0] "" Vector__XXX

BO_ 920 GTW_carConfig: 8 GTW
 SG_ GTW_performanceConfig : 2|3@0+ (1,0) [0|7] "" ESP
 SG_ GTW_fourWheelDrive : 4|2@0+ (1,0) [0|3] "" APP,APS,ESP,RADAR,TAS
 SG_ GTW_rearDriveUnitType : 5|1@0+ (1,0) [0|1] "" TAS
 SG_ GTW_brakeHwType : 7|2@0+ (1,0) [0|2] "" EPB,EPBM
 SG_ GTW_parkAssistInstalled : 9|2@0+ (1,0) [0|3] "" DAS
 SG_ GTW_forwardRadarHw : 11|2@0+ (1,0) [0|2] "" APP,APS,RADAR
 SG_ GTW_airSuspensionInstalled : 14|3@0+ (1,0) [0|5] "" DAS
 SG_ GTW_foldingMirrorsInstalled : 15|1@0+ (1,0) [0|1] "" DAS
 SG_ GTW_country : 23|16@0+ (1,0) [0|65535] "" APS,BDY,PARK
 SG_ GTW_parkSensorGeometryType : 33|2@0+ (1,0) [0|2] "" PARK
 SG_ GTW_rhd : 34|1@0+ (1,0) [0|1] "" APP,APS,RCM,VCSEATD,VCSEATP
 SG_ GTW_bodyControlsType : 35|1@0+ (1,0) [0|1] "" APS
 SG_ GTW_radarPosition : 39|4@0+ (1,0) [0|2] "" APP,APS,RADAR
 SG_ GTW_dasHw : 43|4@0+ (1,0) [0|4] "" APP,EPB
 SG_ GTW_epasType : 46|3@0+ (1,0) [0|4] "" DAS,EPB,RADAR
 SG_ GTW_restraintControlsType : 47|1@0+ (1,0) [0|1] "" DAS
 SG_ GTW_wheelType : 52|5@0+ (1,0) [0|31] "" PARK,TAS
 SG_ GTW_rearSeatControllerMask : 55|3@0+ (1,0) [0|7] "" RCM
 SG_ GTW_efuseType : 57|2@0+ (1,0) [0|1] "" EPB,TAS
 SG_ GTW_autopilot : 61|3@0+ (1,0) [0|4] "" DAS,EPB
 SG_ GTW_chassisType : 63|2@0+ (1,0) [0|2] "" APP,DAS,EPB,EPBM,TAS

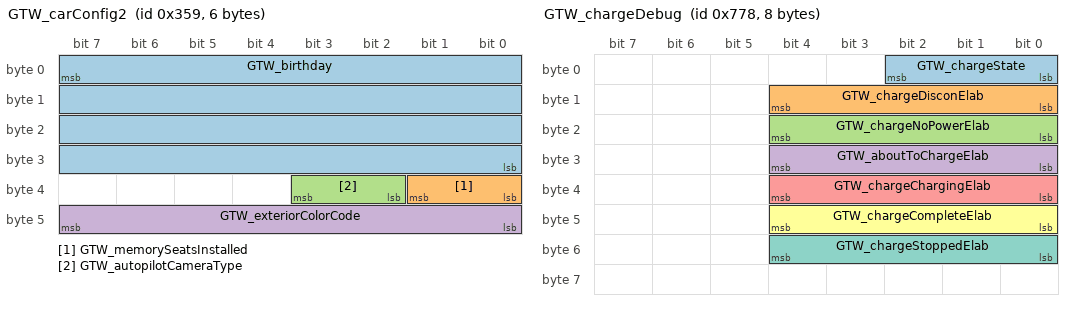
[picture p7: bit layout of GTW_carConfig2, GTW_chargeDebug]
BO_ 857 GTW_carConfig2: 6 GTW
 SG_ GTW_birthday : 7|32@0+ (1,0) [0|4294967295] "" APP
 SG_ GTW_memorySeatsInstalled : 33|2@0+ (1,0) [0|3] "" APP,APS
 SG_ GTW_autopilotCameraType : 35|2@0+ (1,0) [0|2] "" APP
 SG_ GTW_exteriorColorCode : 47|8@0+ (1,0) [0|255] "" Vector__XXX

BO_ 792 GTW_carState: 8 GTW
 SG_ YEAR : 0|7@1+ (1,2000) [2000|2127] "Year" RCM,EAS
 SG_ CERRD : 7|1@1+ (1,0) [0|1] "" EAS
 SG_ MONTH : 8|4@1+ (1,0) [1|12] "Month" RCM,EAS
 SG_ DOOR_STATE_FL : 12|2@1+ (1,0) [0|3] "" EAS,TAS,APP,VCSEATD,VCSEATP
 SG_ DOOR_STATE_FR : 14|2@1+ (1,0) [0|3] "" EAS,TAS,APP,VCSEATD,VCSEATP
 SG_ SECOND : 16|6@1+ (1,0) [0|59] "s" RCM,EAS
 SG_ DOOR_STATE_RL : 22|2@1+ (1,0) [0|3] "" EAS,TAS,APP
 SG_ Hour : 24|5@1+ (1,0) [0|23] "h" RCM,EAS
 SG_ DOOR_STATE_RR : 29|2@1+ (1,0) [0|3] "" EAS,TAS,APP
 SG_ DAY : 32|5@1+ (1,0) [0|31] "" RCM,EAS
 SG_ MCU_gameMode : 37|1@1+ (1,0) [0|1] "" Vector__XXX
 SG_ BC_courtesyLightingActive : 39|2@0+ (1,0) [0|3] "" VCSEATD
 SG_ MINUTE : 40|6@1+ (1,0) [0|59] "min" RCM,EAS
 SG_ BOOT_STATE : 46|2@1+ (1,0) [0|3] "" EAS,TAS
 SG_ GTW_updateInProgress : 48|2@1+ (1,0) [0|3] "" EPB,EPBM,TAS,APS,APP
 SG_ DOOR_STATE_FrontTrunk : 50|2@1+ (1,0) [0|3] "" EAS,TAS
 SG_ MCU_factoryMode : 52|1@1+ (1,0) [0|1] "" TAS,APP,APS
 SG_ MCU_transportModeOn : 53|1@0+ (1,0) [0|1] "" TAS,APP,APS
 SG_ BC_headLightLStatus : 55|2@0+ (1,0) [0|3] "" APP,APS
 SG_ BC_headLightRStatus : 57|2@0+ (1,0) [0|3] "" APP,APS
 SG_ BC_indicatorLStatus : 59|2@0+ (1,0) [0|3] "" APP,APS
 SG_ BC_indicatorRStatus : 61|2@0+ (1,0) [0|3] "" APP,APS
 SG_ GTW_apGoToFullPower : 63|1@1+ (1,0) [0|1] "" APP,APS

BO_ 1048 GTW_chNm: 1 GTW
 SG_ GTW_chGotoSleep : 0|1@1+ (1,0) [0|0] "" IC,DAS,TAS,EPB,EPBM
 SG_ GTW_chHeartBeatCounter : 4|4@1+ (1,0) [0|0] "" IC,TAS

BO_ 1912 GTW_chargeDebug: 8 GTW
 SG_ GTW_chargeState : 2|3@0+ (1,0) [0|0] "" Vector__XXX
 SG_ GTW_chargeDisconElab : 12|5@0+ (1,0) [0|0] "" Vector__XXX
 SG_ GTW_chargeNoPowerElab : 20|5@0+ (1,0) [0|0] "" Vector__XXX
 SG_ GTW_aboutToChargeElab : 28|5@0+ (1,0) [0|0] "" Vector__XXX
 SG_ GTW_chargeChargingElab : 36|5@0+ (1,0) [0|0] "" Vector__XXX
 SG_ GTW_chargeCompleteElab : 44|5@0+ (1,0) [0|0] "" Vector__XXX
 SG_ GTW_chargeStoppedElab : 52|5@0+ (1,0) [0|0] "" Vector__XXX

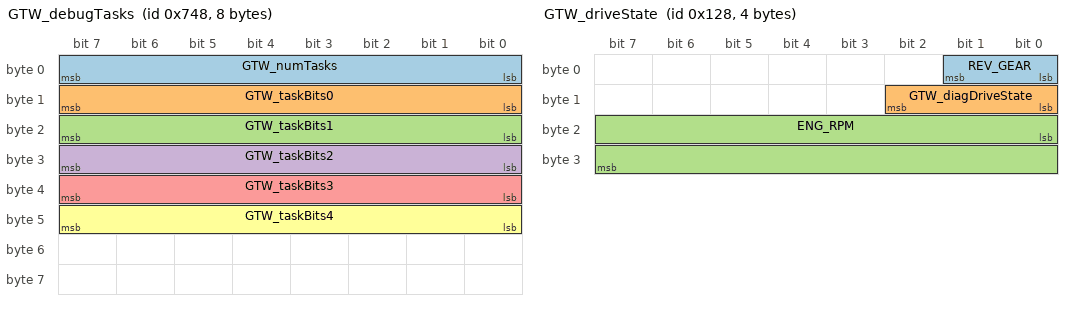
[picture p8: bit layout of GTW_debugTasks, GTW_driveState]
BO_ 1864 GTW_debugTasks: 8 GTW
 SG_ GTW_numTasks : 7|8@0+ (1,0) [0|0] "" GTW
 SG_ GTW_taskBits0 : 15|8@0+ (1,0) [0|0] "" Vector__XXX
 SG_ GTW_taskBits1 : 23|8@0+ (1,0) [0|0] "" Vector__XXX
 SG_ GTW_taskBits2 : 31|8@0+ (1,0) [0|0] "" Vector__XXX
 SG_ GTW_taskBits3 : 39|8@0+ (1,0) [0|0] "" Vector__XXX
 SG_ GTW_taskBits4 : 47|8@0+ (1,0) [0|0] "" Vector__XXX

BO_ 296 GTW_driveState: 4 GTW
 SG_ REV_GEAR : 0|2@1+ (1,0) [0|3] "" EAS
 SG_ GTW_diagDriveState : 8|3@1+ (1,0) [0|4] "" TOOL
 SG_ ENG_RPM : 16|16@1+ (1,0) [0|65533] "rpm" EAS

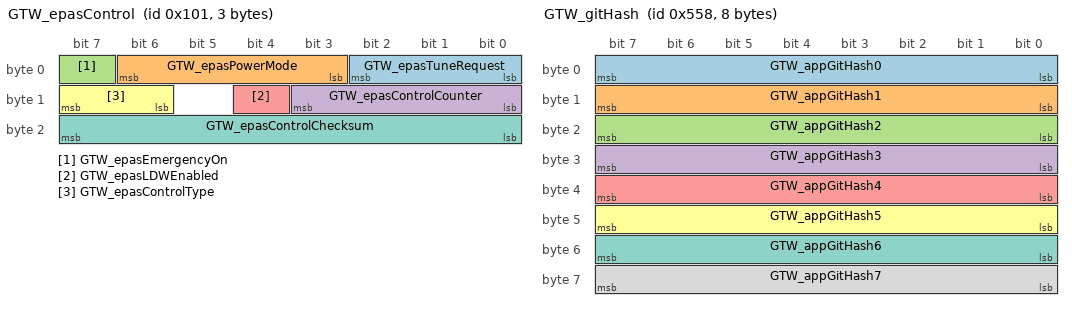
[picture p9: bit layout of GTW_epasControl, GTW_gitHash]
BO_ 257 GTW_epasControl: 3 GTW
 SG_ GTW_epasTuneRequest : 2|3@0+ (1,0) [0|0] "" EPAS,EPAS2,EPAS3S
 SG_ GTW_epasPowerMode : 6|4@0+ (1,0) [0|0] "" EPAS,EPAS2,EPAS3S
 SG_ GTW_epasEmergencyOn : 7|1@0+ (1,0) [0|1] "" EPAS,EPAS2,EPAS3S
 SG_ GTW_epasControlCounter : 11|4@0+ (1,0) [0|0] "" EPAS,EPAS2,EPAS3S
 SG_ GTW_epasLDWEnabled : 12|1@0+ (1,0) [0|1] "" EPAS,EPAS2,EPAS3S
 SG_ GTW_epasControlType : 15|2@0+ (1,0) [0|0] "" EPAS,EPAS2,EPAS3S,APS
 SG_ GTW_epasControlChecksum : 23|8@0+ (1,0) [0|0] "" EPAS,EPAS2,EPAS3S

BO_ 1281 GTW_epasNM: 8 GTW
 SG_ EPAS_destinationAddress : 0|8@1+ (1,0) [0|0] "" EPAS
 SG_ EPAS_controlField : 8|8@1+ (1,0) [0|0] "" EPAS

BO_ 1368 GTW_gitHash: 8 GTW
 SG_ GTW_appGitHash0 : 0|8@1+ (1,0) [0|0] "" APS
 SG_ GTW_appGitHash1 : 8|8@1+ (1,0) [0|0] "" APS
 SG_ GTW_appGitHash2 : 16|8@1+ (1,0) [0|0] "" APS
 SG_ GTW_appGitHash3 : 24|8@1+ (1,0) [0|0] "" APS
 SG_ GTW_appGitHash4 : 32|8@1+ (1,0) [0|0] "" APS
 SG_ GTW_appGitHash5 : 40|8@1+ (1,0) [0|0] "" APS
 SG_ GTW_appGitHash6 : 48|8@1+ (1,0) [0|0] "" APS
 SG_ GTW_appGitHash7 : 56|8@1+ (1,0) [0|0] "" APS

BO_ 888 GTW_ibsData: 8 GTW
 SG_ GTW_ibsVoltage : 39|16@0+ (1,0) [0|50000] "mV" PARK

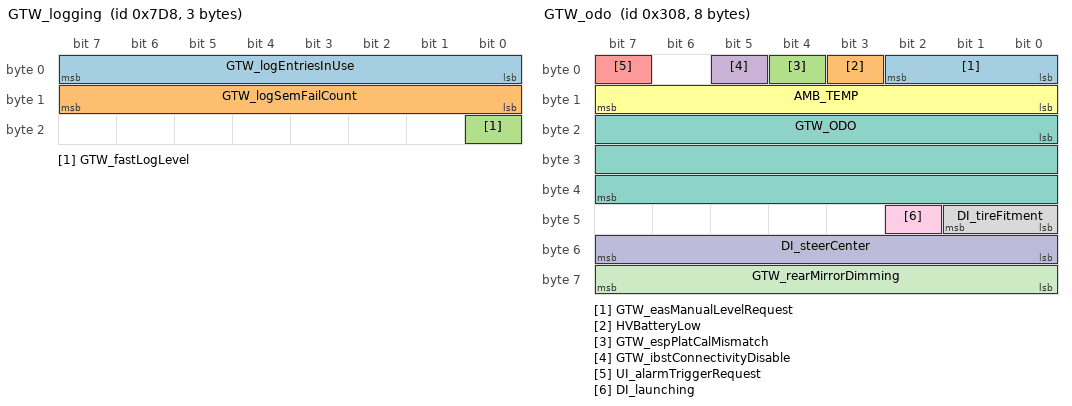
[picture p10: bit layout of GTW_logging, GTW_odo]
BO_ 2008 GTW_logging: 3 GTW
 SG_ GTW_logEntriesInUse : 7|8@0+ (1,0) [0|255] "" Vector__XXX
 SG_ GTW_logSemFailCount : 15|8@0+ (1,0) [0|255] "" Vector__XXX
 SG_ GTW_fastLogLevel : 16|1@0+ (1,0) [0|1] "" GTW

BO_ 776 GTW_odo: 8 GTW
 SG_ GTW_easManualLevelRequest : 0|3@1+ (1,0) [0|7] "" EAS
 SG_ HVBatteryLow : 3|1@1+ (1,0) [0|1] "" EAS,TAS
 SG_ GTW_espPlatCalMismatch : 4|1@1+ (1,0) [0|1] "" ESP
 SG_ GTW_ibstConnectivityDisable : 5|1@1+ (1,0) [0|1] "" IBST
 SG_ UI_alarmTriggerRequest : 7|1@0+ (1,0) [0|0] "" APP
 SG_ AMB_TEMP : 8|8@1+ (0.5,-40) [-40|87.5] "C" TPMS,PARK,EAS,EPB,EPBM,TAS,DAS,EPAS,EPAS2
 SG_ GTW_ODO : 16|24@1+ (0.1,0) [0|1677721.5] "km" ESP,RCM,EAS,RADAR,PARK,DAS
 SG_ DI_tireFitment : 40|2@1+ (1,0) [0|3] "" PARK,TAS2
 SG_ DI_launching : 42|1@1+ (1,0) [0|0] "" TAS2
 SG_ DI_steerCenter : 48|8@1- (0.2,0) [-25.6|25.4] "deg" TAS2
 SG_ GTW_rearMirrorDimming : 56|8@1+ (1,0) [0|255] "" APP

BO_ 1960 GTW_powerDebug: 8 GTW
 SG_ GTW_powerControlFlags : 7|32@0+ (1,0) [0|0] "" Vector__XXX
 SG_ GTW_powerRailsFlags : 39|32@0+ (1,0) [0|0] "" Vector__XXX

BO_ 936 GTW_sleepDebug: 8 GTW
 SG_ GTW_accRailReqIsOn : 0|1@0+ (1,0) [0|0] "" Vector__XXX
 SG_ GTW_hvacRailReqIsOn : 1|1@0+ (1,0) [0|0] "" Vector__XXX
 SG_ GTW_driveRailReqIsOn : 2|1@0+ (1,0) [0|0] "" Vector__XXX
 SG_ GTW_bdyBusAwake : 4|1@0+ (1,0) [0|0] "" Vector__XXX
 SG_ GTW_bftBusAwake : 5|1@0+ (1,0) [0|0] "" Vector__XXX
 SG_ GTW_chgWantsKeepAwake : 6|1@0+ (1,0) [0|0] "" Vector__XXX
 SG_ GTW_sleepInhibitedByXfer : 7|1@0+ (1,0) [0|0] "" Vector__XXX
 SG_ GTW_secHadKeepWake : 8|1@0+ (1,0) [0|0] "" Vector__XXX
 SG_ GTW_bdyHadKeepWake : 9|1@0+ (1,0) [0|0] "" Vector__XXX
 SG_ GTW_sunHadKeepWake : 10|1@0+ (1,0) [0|0] "" Vector__XXX
 SG_ GTW_lftHadKeepWake : 11|1@0+ (1,0) [0|0] "" Vector__XXX
 SG_ GTW_ddmHadKeepWake : 12|1@0+ (1,0) [0|0] "" Vector__XXX
 SG_ GTW_pdmHadKeepWake : 13|1@0+ (1,0) [0|0] "" Vector__XXX
 SG_ GTW_cpWantsKeepAwake : 14|1@0+ (1,0) [0|0] "" Vector__XXX
 SG_ GTW_wouldSleep : 15|1@0+ (1,0) [0|0] "" Vector__XXX
 SG_ GTW_ethLocked : 17|1@0+ (1,0) [0|0] "" Vector__XXX
 SG_ MCU_requestBusWake : 18|2@1+ (1,0) [0|0] "" Vector__XXX
 SG_ GTW_icOff : 20|1@0+ (1,0) [0|0] "" Vector__XXX
 SG_ GTW_icWillBePoweredOff : 21|1@0+ (1,0) [0|0] "" Vector__XXX
 SG_ GTW_willBeGoingToSleep : 23|2@0+ (1,0) [0|0] "" Vector__XXX
 SG_ GTW_clusterState : 26|3@0+ (1,0) [0|0] "" Vector__XXX
 SG_ MCU_clusterInstantOn : 27|1@1+ (1,0) [0|0] "" Vector__XXX
 SG_ GTW_keyAuthenticated : 28|1@0+ (1,0) [0|0] "" Vector__XXX
 SG_ MCU_gatewaySleepReq : 29|3@1+ (1,0) [0|0] "" Vector__XXX
 SG_ MCU_updaterSleepDelay : 47|8@0+ (5,0) [0|0] "" Vector__XXX
 SG_ GTW_delayMinutesRemaining : 48|8@1+ (1,0) [0|0] "min" Vector__XXX
 SG_ GTW_updaterMinutesRemaining : 56|8@1+ (1,0) [0|0] "min" Vector__XXX

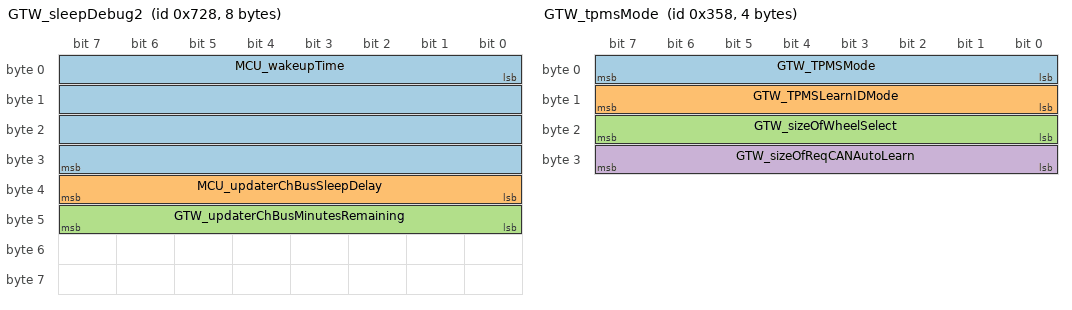
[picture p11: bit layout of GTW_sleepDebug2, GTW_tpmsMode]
BO_ 1832 GTW_sleepDebug2: 8 GTW
 SG_ MCU_wakeupTime : 0|32@1+ (1,0) [0|0] "" Vector__XXX
 SG_ MCU_updaterChBusSleepDelay : 39|8@0+ (5,0) [0|0] "" Vector__XXX
 SG_ GTW_updaterChBusMinutesRemaining : 47|8@0+ (1,0) [0|0] "min" Vector__XXX

BO_ 1880 GTW_sleepDebug3: 8 GTW
 SG_ GTW_deepSleepMinutes : 7|14@0+ (1,0) [0|0] "" Vector__XXX
 SG_ GTW_wantDeepSleep : 8|1@0+ (1,0) [0|0] "" Vector__XXX

BO_ 1896 GTW_sleepDebug4: 8 GTW
 SG_ GTW_lastUserAction : 7|32@0+ (1,0) [0|0] "secs" Vector__XXX

BO_ 840 GTW_status: 8 GTW
 SG_ GTW_driveRailReq : 0|1@0+ (1,0) [0|1] "" IBST,IC,EPB,EPBM,DAS,TAS
 SG_ GTW_brakePressed : 1|1@0+ (1,0) [0|0] "" EPB,EPBM
 SG_ GTW_driverPresent : 2|1@0+ (1,0) [0|0] "" DAS
 SG_ GTW_notEnough12VForDrive : 3|1@0+ (1,0) [0|0] "" EPB,EPBM
 SG_ GTW_icPowerOff : 4|1@0+ (1,0) [0|0] "" IC
 SG_ GTW_driverIsLeaving : 5|1@0+ (1,0) [0|0] "" EPB,EPBM
 SG_ GTW_accGoingDown : 6|1@0+ (1,0) [0|0] "" EPB,EPBM
 SG_ GTW_driveGoingDown : 7|1@0+ (1,0) [0|0] "" EPB,EPBM
 SG_ GTW_accRailReq : 8|1@0+ (1,0) [0|1] "" IBST,DAS,TAS,EPB,EPBM
 SG_ GTW_hvacRailReq : 9|1@0+ (1,0) [0|1] "" DAS
 SG_ GTW_preconditionCabinRequest : 10|1@0+ (1,0) [0|1] "" DAS
 SG_ GTW_hvacGoingDown : 11|1@1+ (1,0) [0|0] "" DAS
 SG_ GTW_ptBusAwake : 12|1@0+ (1,0) [0|0] "" EPB,EPBM
 SG_ GTW_mcuOff : 13|1@0+ (1,0) [0|0] "" APP
 SG_ GTW_hvacRailIsOn : 14|1@0+ (1,0) [0|0] "" APS
 SG_ GTW_gameModeAvailable : 15|1@0+ (1,0) [0|4] "" Vector__XXX
 SG_ GTW_vehiclePowerState : 16|1@0+ (1,0) [0|1] "" TAS
 SG_ GTW_driverIsLeavingAnySpeed : 17|1@0+ (1,0) [0|1] "" BCCEN
 SG_ DOOR_STATE_RearTrunk : 18|2@1+ (1,0) [0|3] "" EAS,TAS
 SG_ GTW_statusCounter : 51|4@0+ (1,0) [0|0] "" IC,TAS
 SG_ GTW_statusChecksum : 63|8@0+ (1,0) [0|0] "" IC,TAS

BO_ 1800 GTW_time: 4 GTW
 SG_ GTW_timeSecs : 7|32@0+ (1,0) [0|0] "" IC

BO_ 856 GTW_tpmsMode: 4 GTW
 SG_ GTW_TPMSMode : 0|8@1+ (1,0) [0|0] "" TPMS
 SG_ GTW_TPMSLearnIDMode : 8|8@1+ (1,0) [0|0] "" TPMS
 SG_ GTW_sizeOfWheelSelect : 16|8@1+ (1,0) [0|0] "" TPMS
 SG_ GTW_sizeOfReqCANAutoLearn : 24|8@1+ (1,0) [0|0] "" TPMS

BO_ 1469 IBST_alertLog: 8 IBST
 SG_ IBST_alertID M : 0|15@1+ (1,0) [0|0] "" GTW
 SG_ IBST_alertType : 15|1@1+ (1,0) [0|0] "" GTW
 SG_ IBST_bmsInitTestFail m16384 : 16|1@1+ (1,0) [0|0] "" GTW
 SG_ IBST_bmcSingleTransTest m16385 : 16|1@1+ (1,0) [0|0] "" GTW
 SG_ IBST_tle5012SsccrcFail m16386 : 16|1@1+ (1,0) [0|0] "" GTW
 SG_ IBST_tle5012Config m16387 : 16|1@1+ (1,0) [0|0] "" GTW
 SG_ IBST_deadlMonTaskx1Ovr m16388 : 16|1@1+ (1,0) [0|0] "" GTW
 SG_ IBST_ecuWdFltCntTstFls m16389 : 16|1@1+ (1,0) [0|0] "" GTW
 SG_ IBST_ecuWdScheduleTout m16390 : 16|1@1+ (1,0) [0|0] "" GTW
 SG_ IBST_ecuWdStarttestFls m16391 : 16|1@1+ (1,0) [0|0] "" GTW
 SG_ IBST_ecuWdStatusContErr m16392 : 16|1@1+ (1,0) [0|0] "" GTW
 SG_ IBST_netOvrvolt m16393 : 16|1@1+ (1,0) [0|0] "" GTW
 SG_ IBST_micSpiTout m16394 : 16|1@1+ (1,0) [0|0] "" GTW
 SG_ IBST_micSpiTransferErr m16395 : 16|1@1+ (1,0) [0|0] "" GTW
 SG_ IBST_netUndvolt m16396 : 16|1@1+ (1,0) [0|0] "" GTW
 SG_ IBST_xpassToutErr m16397 : 16|1@1+ (1,0) [0|0] "" GTW
 SG_ IBST_rpsOffsEeReadEmpty m16398 : 16|1@1+ (1,0) [0|0] "" GTW
 SG_ IBST_rtpEnaHigh m16399 : 16|1@1+ (1,0) [0|0] "" GTW
 SG_ IBST_xpassEchoCountErr m16400 : 16|1@1+ (1,0) [0|0] "" GTW
 SG_ IBST_preDriveChckFail m16401 : 16|1@1+ (1,0) [0|0] "" GTW
 SG_ IBST_ucSafetyFlt m16402 : 16|1@1+ (1,0) [0|0] "" GTW
 SG_ IBST_unsupportedHw m16403 : 16|1@1+ (1,0) [0|0] "" GTW
 SG_ IBST_voltPreRegModeFld m16404 : 16|1@1+ (1,0) [0|0] "" GTW
 SG_ IBST_ubbSupplyLine m16405 : 16|1@1+ (1,0) [0|0] "" GTW
 SG_ IBST_stmAswSysTout m16406 : 16|1@1+ (1,0) [0|0] "" GTW
 SG_ IBST_stackOvrUndFlow m16407 : 16|1@1+ (1,0) [0|0] "" GTW
 SG_ IBST_smmOneReqsInit m16408 : 16|1@1+ (1,0) [0|0] "" GTW
 SG_ IBST_ptsSupply m16409 : 16|1@1+ (1,0) [0|0] "" GTW
 SG_ IBST_ptsSupplyUndvolt m16410 : 16|1@1+ (1,0) [0|0] "" GTW
 SG_ IBST_tempB6Plaus m16411 : 16|1@1+ (1,0) [0|0] "" GTW
 SG_ IBST_ecuWdErrCntContErr m16412 : 16|1@1+ (1,0) [0|0] "" GTW
 SG_ IBST_bmcShortedGateTest m16413 : 16|1@1+ (1,0) [0|0] "" GTW
 SG_ IBST_controllerDevTooBig m16414 : 16|1@1+ (1,0) [0|0] "" GTW
 SG_ IBST_ibDtrFail m16415 : 16|1@1+ (1,0) [0|0] "" GTW
 SG_ IBST_oc6InitTestFail m16416 : 16|1@1+ (1,0) [0|0] "" GTW
 SG_ IBST_oc6Monitor m16417 : 16|1@1+ (1,0) [0|0] "" GTW
 SG_ IBST_motorOscillationDet m16418 : 16|1@1+ (1,0) [0|0] "" GTW
 SG_ IBST_rpsOffsEeReadFail m16419 : 16|1@1+ (1,0) [0|0] "" GTW
 SG_ IBST_sysErrHook m16420 : 16|1@1+ (1,0) [0|0] "" GTW
 SG_ IBST_calIdlePosNotPlaus m16421 : 16|1@1+ (1,0) [0|0] "" GTW
 SG_ IBST_boostSupUndrvolt m16422 : 16|1@1+ (1,0) [0|0] "" GTW
 SG_ IBST_calRoutineAbort m16423 : 16|1@1+ (1,0) [0|0] "" GTW
 SG_ IBST_bmcGateUndervoltPro m16424 : 16|1@1+ (1,0) [0|0] "" GTW
 SG_ IBST_hswInitPhseUndrvolt m16425 : 16|1@1+ (1,0) [0|0] "" GTW
 SG_ IBST_ltmWarnLevelReached m16426 : 16|1@1+ (1,0) [0|0] "" GTW
 SG_ IBST_rpsVctrLengthRelErr m16427 : 16|1@1+ (1,0) [0|0] "" GTW
 SG_ IBST_b6TempDegradeLevel1 m16428 : 16|1@1+ (1,0) [0|0] "" GTW
 SG_ IBST_B6TempDegradeLevel2 m16429 : 16|1@1+ (1,0) [0|0] "" GTW
 SG_ IBST_spiAnglOrRawNotUp m16430 : 16|1@1+ (1,0) [0|0] "" GTW
 SG_ IBST_dcomIboosterNotInit m16431 : 16|1@1+ (1,0) [0|0] "" GTW
 SG_ IBST_unintendMotorReturn m16432 : 16|1@1+ (1,0) [0|0] "" GTW
 SG_ IBST_cdmOvrvoltLevel1 m16433 : 16|1@1+ (1,0) [0|0] "" GTW
 SG_ IBST_cdmUndrvoltLevel2 m16434 : 16|1@1+ (1,0) [0|0] "" GTW
 SG_ IBST_cdmUndrvoltLevel1 m16435 : 16|1@1+ (1,0) [0|0] "" GTW
 SG_ IBST_motTrvlRelReadFail m16436 : 16|1@1+ (1,0) [0|0] "" GTW
 SG_ IBST_tle5012UnexpReset m16437 : 16|1@1+ (1,0) [0|0] "" GTW
 SG_ IBST_bmsGateUndrvolt m16438 : 16|1@1+ (1,0) [0|0] "" GTW
 SG_ IBST_kl15HwPlausSw m16439 : 16|1@1+ (1,0) [0|0] "" GTW
 SG_ IBST_ibNotShutDownRight m16440 : 16|1@1+ (1,0) [0|0] "" GTW
 SG_ IBST_cdmHardUndrvolt m16441 : 16|1@1+ (1,0) [0|0] "" GTW
 SG_ IBST_cdmHardOvrvolt m16442 : 16|1@1+ (1,0) [0|0] "" GTW
 SG_ IBST_maxTrvlAdjstUpdFail m16443 : 16|1@1+ (1,0) [0|0] "" GTW
 SG_ IBST_ltmLimitReached m16444 : 16|1@1+ (1,0) [0|0] "" GTW
 SG_ IBST_dcomEcuDefect m16445 : 16|1@1+ (1,0) [0|0] "" GTW
 SG_ IBST_inputStroke1RngHigh m16446 : 16|1@1+ (1,0) [0|0] "" GTW
 SG_ IBST_inputStroke1RngLow m16447 : 16|1@1+ (1,0) [0|0] "" GTW
 SG_ IBST_inputStroke2RngHigh m16448 : 16|1@1+ (1,0) [0|0] "" GTW
 SG_ IBST_inputStroke2RngLow m16449 : 16|1@1+ (1,0) [0|0] "" GTW
 SG_ IBST_ibSupVoltDivDrift m16450 : 16|1@1+ (1,0) [0|0] "" GTW
 SG_ IBST_sOutRodToPressVal m16451 : 16|1@1+ (1,0) [0|0] "" GTW
 SG_ IBST_tle5012LifeCnt m16452 : 16|1@1+ (1,0) [0|0] "" GTW
 SG_ IBST_cdmExtendedUndrvolt m16453 : 16|1@1+ (1,0) [0|0] "" GTW
 SG_ IBST_cdmExtendedOvrvolt m16454 : 16|1@1+ (1,0) [0|0] "" GTW
 SG_ IBST_tempB6Ch1LineHigh m16455 : 16|1@1+ (1,0) [0|0] "" GTW
 SG_ IBST_tempB6Ch1LineLow m16456 : 16|1@1+ (1,0) [0|0] "" GTW
 SG_ IBST_tempB6Ch2LineHigh m16457 : 16|1@1+ (1,0) [0|0] "" GTW
 SG_ IBST_tempB6Ch2LineLow m16458 : 16|1@1+ (1,0) [0|0] "" GTW
 SG_ IBST_hevSwitchOffDcom m16459 : 16|1@1+ (1,0) [0|0] "" GTW
 SG_ IBST_tle5012VoltFail m16460 : 16|1@1+ (1,0) [0|0] "" GTW
 SG_ IBST_bcsFltCurrentHigh m16461 : 16|1@1+ (1,0) [0|0] "" GTW
 SG_ IBST_bcsFltCurrentLow m16462 : 16|1@1+ (1,0) [0|0] "" GTW
 SG_ IBST_ecuSupVoltDivDrift m16463 : 16|1@1+ (1,0) [0|0] "" GTW
 SG_ IBST_inputstroke1Grad m16464 : 16|1@1+ (1,0) [0|0] "" GTW
 SG_ IBST_pts1Err m16465 : 16|1@1+ (1,0) [0|0] "" GTW
 SG_ IBST_pts1LineGnd m16466 : 16|1@1+ (1,0) [0|0] "" GTW
 SG_ IBST_pts1LineHigh m16467 : 16|1@1+ (1,0) [0|0] "" GTW
 SG_ IBST_inputStroke2Grad m16468 : 16|1@1+ (1,0) [0|0] "" GTW
 SG_ IBST_pts2Err m16469 : 16|1@1+ (1,0) [0|0] "" GTW
 SG_ IBST_pts2LineGnd m16470 : 16|1@1+ (1,0) [0|0] "" GTW
 SG_ IBST_pts2LineHigh m16471 : 16|1@1+ (1,0) [0|0] "" GTW
 SG_ IBST_faildevInputStroke m16472 : 16|1@1+ (1,0) [0|0] "" GTW
 SG_ IBST_ptsOffsTooHigh m16473 : 16|1@1+ (1,0) [0|0] "" GTW
 SG_ IBST_pbistErr m16474 : 16|1@1+ (1,0) [0|0] "" GTW
 SG_ IBST_ramInitErr m16475 : 16|1@1+ (1,0) [0|0] "" GTW
 SG_ IBST_ramsinlgeFlt m16476 : 16|1@1+ (1,0) [0|0] "" GTW
 SG_ IBST_bertFlt m16477 : 16|1@1+ (1,0) [0|0] "" GTW
 SG_ IBST_CalDataNotPlaus m16478 : 16|1@1+ (1,0) [0|0] "" GTW
 SG_ IBST_canEHwError m16479 : 16|1@1+ (1,0) [0|0] "" GTW
 SG_ IBST_canETout m16480 : 16|1@1+ (1,0) [0|0] "" GTW
 SG_ IBST_cpuException m16481 : 16|1@1+ (1,0) [0|0] "" GTW
 SG_ IBST_ecuBandGap m16482 : 16|1@1+ (1,0) [0|0] "" GTW
 SG_ IBST_ecuBmsOnWhileWdTout m16483 : 16|1@1+ (1,0) [0|0] "" GTW
 SG_ IBST_ecuErrpinCntTstFls m16484 : 16|1@1+ (1,0) [0|0] "" GTW
 SG_ IBST_ecuHetException m16485 : 16|1@1+ (1,0) [0|0] "" GTW
 SG_ IBST_ecuHetTuAddErr m16486 : 16|1@1+ (1,0) [0|0] "" GTW
 SG_ IBST_ecuHetTuBusErr m16487 : 16|1@1+ (1,0) [0|0] "" GTW
 SG_ IBST_ecuHetTuBusyErr m16488 : 16|1@1+ (1,0) [0|0] "" GTW
 SG_ IBST_ecuHetTuException m16489 : 16|1@1+ (1,0) [0|0] "" GTW
 SG_ IBST_ecuTaskMissing m16490 : 16|1@1+ (1,0) [0|0] "" GTW
 SG_ IBST_hetRefError m16491 : 16|1@1+ (1,0) [0|0] "" GTW
 SG_ IBST_micInitSpiTstFld m16492 : 16|1@1+ (1,0) [0|0] "" GTW
 SG_ IBST_micInitSpiTransfErr m16493 : 16|1@1+ (1,0) [0|0] "" GTW
 SG_ IBST_micIntMonGenBitMon m16494 : 16|1@1+ (1,0) [0|0] "" GTW
 SG_ IBST_micIntVoltMonFld m16495 : 16|1@1+ (1,0) [0|0] "" GTW
 SG_ IBST_motPosTrvlReadEmpty m16496 : 16|1@1+ (1,0) [0|0] "" GTW
 SG_ IBST_motAngBoundReadEmpt m16497 : 16|1@1+ (1,0) [0|0] "" GTW
 SG_ IBST_motShaftShiftDetect m16498 : 16|1@1+ (1,0) [0|0] "" GTW
 SG_ IBST_osErrHook m16499 : 16|1@1+ (1,0) [0|0] "" GTW
 SG_ IBST_pdurEInitFail m16500 : 16|1@1+ (1,0) [0|0] "" GTW
 SG_ IBST_pdurEPduInstLost m16501 : 16|1@1+ (1,0) [0|0] "" GTW
 SG_ IBST_pts1OffsEeReadEmpty m16502 : 16|1@1+ (1,0) [0|0] "" GTW
 SG_ IBST_pts2OffsEeReadEmpty m16503 : 16|1@1+ (1,0) [0|0] "" GTW
 SG_ IBST_rpsOffsXEeReadFail m16504 : 16|1@1+ (1,0) [0|0] "" GTW
 SG_ IBST_rpsOffsYEeReadFail m16505 : 16|1@1+ (1,0) [0|0] "" GTW
 SG_ IBST_rpsSynchEeReadFail m16506 : 16|1@1+ (1,0) [0|0] "" GTW
 SG_ IBST_rpsAnglRecalcErr m16507 : 16|1@1+ (1,0) [0|0] "" GTW
 SG_ IBST_motTrvlRelWriteFail m16508 : 16|1@1+ (1,0) [0|0] "" GTW
 SG_ IBST_motTrvlRelReadEmpty m16509 : 16|1@1+ (1,0) [0|0] "" GTW
 SG_ IBST_ptsEeReadEmpty m16510 : 16|1@1+ (1,0) [0|0] "" GTW
 SG_ IBST_ecuAdcConversionErr m16511 : 16|1@1+ (1,0) [0|0] "" GTW
 SG_ IBST_ecuAdcSelftestErr m16512 : 16|1@1+ (1,0) [0|0] "" GTW
 SG_ IBST_ccmFlt m16513 : 16|1@1+ (1,0) [0|0] "" GTW
 SG_ IBST_ecuRomCheck m16514 : 16|1@1+ (1,0) [0|0] "" GTW
 SG_ IBST_esmNmiFlt m16515 : 16|1@1+ (1,0) [0|0] "" GTW
 SG_ IBST_esmSafetyFlt m16516 : 16|1@1+ (1,0) [0|0] "" GTW
 SG_ IBST_motPosTrvlReadFail m16517 : 16|1@1+ (1,0) [0|0] "" GTW
 SG_ IBST_motPosTrvlWriteFail m16518 : 16|1@1+ (1,0) [0|0] "" GTW
 SG_ IBST_motAnglBndReadErr m16519 : 16|1@1+ (1,0) [0|0] "" GTW
 SG_ IBST_motAnglBndWriteErr m16520 : 16|1@1+ (1,0) [0|0] "" GTW
 SG_ IBST_motAnglGradTooLarge m16521 : 16|1@1+ (1,0) [0|0] "" GTW
 SG_ IBST_pdmCustomerIdMis m16522 : 16|1@1+ (1,0) [0|0] "" GTW
 SG_ IBST_pdmDtFormatMis m16523 : 16|1@1+ (1,0) [0|0] "" GTW
 SG_ IBST_pdmOutOfMemory m16524 : 16|1@1+ (1,0) [0|0] "" GTW
 SG_ IBST_pdmFieldSizeMis m16525 : 16|1@1+ (1,0) [0|0] "" GTW
 SG_ IBST_pdmHwAcsErr m16526 : 16|1@1+ (1,0) [0|0] "" GTW
 SG_ IBST_pdmMaxWriteCycles m16526 : 17|1@1+ (1,0) [0|0] "" GTW
 SG_ IBST_pdmInternalHWErr m16527 : 16|1@1+ (1,0) [0|0] "" GTW
 SG_ IBST_ptsCalHysWritFail m16528 : 16|1@1+ (1,0) [0|0] "" GTW
 SG_ IBST_ptsCalValuesChkFail m16529 : 16|1@1+ (1,0) [0|0] "" GTW
 SG_ IBST_pts1CalEeReadFail m16530 : 16|1@1+ (1,0) [0|0] "" GTW
 SG_ IBST_pts1CalEeWriteFail m16531 : 16|1@1+ (1,0) [0|0] "" GTW
 SG_ IBST_rpsFailCompErr m16532 : 16|1@1+ (1,0) [0|0] "" GTW
 SG_ IBST_pts1OffsEeWriteFail m16533 : 16|1@1+ (1,0) [0|0] "" GTW
 SG_ IBST_pts2CalEeReadFail m16534 : 16|1@1+ (1,0) [0|0] "" GTW
 SG_ IBST_pts2CalEeWriteFail m16535 : 16|1@1+ (1,0) [0|0] "" GTW
 SG_ IBST_pts2OffsEeReadFail m16536 : 16|1@1+ (1,0) [0|0] "" GTW
 SG_ IBST_pts2OffsEeWriteFail m16537 : 16|1@1+ (1,0) [0|0] "" GTW
 SG_ IBST_rpsOffsXEeReadEmpty m16538 : 16|1@1+ (1,0) [0|0] "" GTW
 SG_ IBST_rpsOffsXEeWriteFail m16539 : 16|1@1+ (1,0) [0|0] "" GTW
 SG_ IBST_rpsOffsYEeReadEmpty m16540 : 16|1@1+ (1,0) [0|0] "" GTW
 SG_ IBST_rpsOffsYEeWriteFail m16541 : 16|1@1+ (1,0) [0|0] "" GTW
 SG_ IBST_rpsSynchEeReadEmpty m16542 : 16|1@1+ (1,0) [0|0] "" GTW
 SG_ IBST_rpsSynchEeWriteFail m16543 : 16|1@1+ (1,0) [0|0] "" GTW
 SG_ IBST_assertionFail m16544 : 16|1@1+ (1,0) [0|0] "" GTW
 SG_ IBST_comsclBrkPrsPduLen m16545 : 16|1@1+ (1,0) [0|0] "" GTW
 SG_ IBST_comsclBrkPrsPduTout m16546 : 16|1@1+ (1,0) [0|0] "" GTW
 SG_ IBST_comsclEspIb1CntErr m16547 : 16|1@1+ (1,0) [0|0] "" GTW
 SG_ IBST_comsclEspIb1CsErr m16548 : 16|1@1+ (1,0) [0|0] "" GTW
 SG_ IBST_comsclEspIb1DlcErr m16549 : 16|1@1+ (1,0) [0|0] "" GTW
 SG_ IBST_comsclEspIb1Tout m16550 : 16|1@1+ (1,0) [0|0] "" GTW
 SG_ IBST_comsclEspIb2CntErr m16551 : 16|1@1+ (1,0) [0|0] "" GTW
 SG_ IBST_comsclEspIb2CsErr m16552 : 16|1@1+ (1,0) [0|0] "" GTW
 SG_ IBST_comsclEspIb2DlcErr m16553 : 16|1@1+ (1,0) [0|0] "" GTW
 SG_ IBST_comsclEspIb2Tout m16554 : 16|1@1+ (1,0) [0|0] "" GTW
 SG_ IBST_comsclEspIb3CntErr m16555 : 16|1@1+ (1,0) [0|0] "" GTW
 SG_ IBST_comsclEspIb3CsErr m16556 : 16|1@1+ (1,0) [0|0] "" GTW
 SG_ IBST_comsclEspIb3DlcErr m16557 : 16|1@1+ (1,0) [0|0] "" GTW
 SG_ IBST_comsclEspIb3Tout m16558 : 16|1@1+ (1,0) [0|0] "" GTW
 SG_ IBST_comsclGtwEsp1CntErr m16559 : 16|1@1+ (1,0) [0|0] "" GTW
 SG_ IBST_comsclGtwEsp1CsErr m16560 : 16|1@1+ (1,0) [0|0] "" GTW
 SG_ IBST_comsclGtwEsp1Corrpt m16561 : 16|1@1+ (1,0) [0|0] "" GTW
 SG_ IBST_comsclGtwEsp1Tout m16562 : 16|1@1+ (1,0) [0|0] "" GTW
 SG_ IBST_dcomSmrtActuNotInit m16563 : 16|1@1+ (1,0) [0|0] "" GTW
 SG_ IBST_rpsLengthAbsolHigh m16564 : 16|1@1+ (1,0) [0|0] "" GTW
 SG_ IBST_rpsLengthAbsolLow m16565 : 16|1@1+ (1,0) [0|0] "" GTW
 SG_ IBST_shutDownEeReadFail m16566 : 16|1@1+ (1,0) [0|0] "" GTW
 SG_ IBST_shutDownEeWriteFail m16567 : 16|1@1+ (1,0) [0|0] "" GTW
 SG_ IBST_maxTrvlAdjstReadErr m16568 : 16|1@1+ (1,0) [0|0] "" GTW
 SG_ IBST_psOffsMcEeReadFail m16569 : 16|1@1+ (1,0) [0|0] "" GTW
 SG_ IBST_psOffsMcEeWriteFail m16570 : 16|1@1+ (1,0) [0|0] "" GTW
 SG_ IBST_ltmSelfProtDeact m16571 : 16|1@1+ (1,0) [0|0] "" GTW
 SG_ IBST_pts1OffsEeReadFail m16572 : 16|1@1+ (1,0) [0|0] "" GTW
 SG_ IBST_diffStrokeRange m16573 : 16|1@1+ (1,0) [0|0] "" GTW
 SG_ IBST_notProgVin m16574 : 16|1@1+ (1,0) [0|0] "" GTW
 SG_ IBST_plausVin m16575 : 16|1@1+ (1,0) [0|0] "" GTW
 SG_ IBST_dlCorCSumVin m16576 : 16|1@1+ (1,0) [0|0] "" GTW
 SG_ IBST_ToutVin m16577 : 16|1@1+ (1,0) [0|0] "" GTW
 SG_ IBST_ecuEnableB6Fail m16578 : 16|1@1+ (1,0) [0|0] "" GTW
 SG_ IBST_ecuIbEnContErr m16579 : 16|1@1+ (1,0) [0|0] "" GTW
 SG_ IBST_sclEspIb1pEstMax m16580 : 16|1@1+ (1,0) [0|0] "" GTW
 SG_ IBST_sclEspIb1VehSpd m16581 : 16|1@1+ (1,0) [0|0] "" GTW
 SG_ IBST_sclEspIb2pLimExt m16582 : 16|1@1+ (1,0) [0|0] "" GTW
 SG_ IBST_sclEspIb2qTarExt m16583 : 16|1@1+ (1,0) [0|0] "" GTW
 SG_ IBST_sclEspIb3pFBlend m16584 : 16|1@1+ (1,0) [0|0] "" GTW
 SG_ IBST_sclEspIb3pMc1 m16585 : 16|1@1+ (1,0) [0|0] "" GTW
 SG_ IBST_sclEspIb3pTarDriver m16586 : 16|1@1+ (1,0) [0|0] "" GTW
 SG_ IBST_netBusOffNet0 m16587 : 16|1@1+ (1,0) [0|0] "" GTW
 SG_ IBST_netErrPassivNet0 m16588 : 16|1@1+ (1,0) [0|0] "" GTW
 SG_ IBST_netBusOffNet1 m16589 : 16|1@1+ (1,0) [0|0] "" GTW
 SG_ IBST_netErrPassivNet1 m16590 : 16|1@1+ (1,0) [0|0] "" GTW
 SG_ IBST_maxStrokeReached m16591 : 16|1@1+ (1,0) [0|0] "" GTW
 SG_ IBST_sysSwClockMismatch m16592 : 16|1@1+ (1,0) [0|0] "" GTW
 SG_ IBST_comsclGtwOdoCorrpt m16593 : 16|1@1+ (1,0) [0|0] "" GTW
 SG_ IBST_comsclGtwStatCorrpt m16594 : 16|1@1+ (1,0) [0|0] "" GTW
 SG_ IBST_comsclEpbStatCorrpt m16595 : 16|1@1+ (1,0) [0|0] "" GTW
 SG_ IBST_comsclGtwOdoTout m16596 : 16|1@1+ (1,0) [0|0] "" GTW
 SG_ IBST_comsclGtwStatTout m16597 : 16|1@1+ (1,0) [0|0] "" GTW
 SG_ IBST_comsclEpbStatTout m16598 : 16|1@1+ (1,0) [0|0] "" GTW
 SG_ IBST_comSclEpbStatCsErr m16599 : 16|1@1+ (1,0) [0|0] "" GTW
 SG_ IBST_comSclEpbStatCntFlt m16600 : 16|1@1+ (1,0) [0|0] "" GTW
 SG_ IBST_comSclDiTrq1Tout m16601 : 16|1@1+ (1,0) [0|0] "" GTW
 SG_ IBST_comSclDiTrq1Corrpt m16602 : 16|1@1+ (1,0) [0|0] "" GTW
 SG_ IBST_comSclDiTrq1CsErr m16603 : 16|1@1+ (1,0) [0|0] "" GTW
 SG_ IBST_comSclDiTrq1CntFlt m16604 : 16|1@1+ (1,0) [0|0] "" GTW

BO_ 1645 IBST_bootID: 8 IBST
 SG_ IBST_bootIdData : 0|64@1+ (1,0) [0|0] "" Vector__XXX

CM_ BO_ 853 "Indicates ESP controller states.";
CM_ BO_ 901 "Slow-speed message for sensor offsets";
CM_ BO_ 520 "These are signals the brake system needs from us";
CM_ SG_ 325 ESP_longitudinalAccel "Positive acceleration when the vehicle is accelerating. Offset compensated.";
CM_ SG_ 325 ESP_stabilityControlSts2 "Indicates the availability and active state of stability control including SNA.";
CM_ SG_ 325 ESP_brakeMasterCylPressQF "Qualifier from ESP for master cylinder pressure sensor.";
CM_ SG_ 325 ESP_absBrakeEvent2 "Indicates if ABS is active and on which axle.";
CM_ SG_ 325 ESP_lateralAccel "Positive acceleration during a left turn. Offset compensated.";
CM_ SG_ 325 ESP_btcTargetState "ESP commanded Tesla brake traction control state";
CM_ SG_ 325 ESP_ptcTargetState "ESP commanded Tesla motor traction control state";
CM_ SG_ 325 ESP_vehicleStandstillSts "Indicates that the vehicle is completely stationary.";
CM_ SG_ 325 ESP_brakeMasterCylPress "Master cylinder pressure measured within the ESP.";
CM_ SG_ 325 ESP_wheelSpeedsQF "Qualifier from ESP for wheel speed signals. Single QF covers all wheel speed signals.";
CM_ SG_ 325 ESP_espModeActive "Indicates the active ESP mode, which correlates to stability control and traction control settings.";
CM_ SG_ 325 ESP_lateralAccelQF "Laterall accel sensor quialifier from ESP";
CM_ SG_ 325 ESP_longitudinalAccelQF "Longitudinal accel sensor quialifier from ESP";
CM_ SG_ 325 ESP_145hCounter "Message counter for ESP_145h message: increments in each message.";
CM_ SG_ 325 ESP_145hChecksum "Message checksum for ESP_145h message: sum of all bytes in message + 0x46";
CM_ SG_ 341 ESP_wheelPulseCountFrL "Wheel speed sensor cumulative pulse counter for front left wheel.";
CM_ SG_ 341 ESP_wheelPulseCountFrR "Wheel speed sensor cumulative pulse counter for front right wheel.";
CM_ SG_ 341 ESP_wheelPulseCountReL "Wheel speed sensor cumulative pulse counter for rear left wheel.";
CM_ SG_ 341 ESP_wheelPulseCountReR "Wheel speed sensor cumulative pulse counter for rear right wheel.";
CM_ SG_ 341 ESP_BChecksum "Unique checksum calculation. See Electronic Stability Control Specification.";
CM_ SG_ 341 ESP_vehicleSpeed "ESP calculated vehicle speed. Average of front wheels on rear wheel drive vehicles. Average of all four wheels on dual motor vehicles.";
CM_ SG_ 341 ESP_vehicleSpeedQF "Qualifier for the validity of the vehicle speed signal.";
CM_ SG_ 341 ESP_BCounter "4 Bit counter, min 0, max 15 (0x0 - 0xF)";
CM_ SG_ 522 ESP_YawRate_LR "Low resolution yaw rate. Positive during a right turn. Offset compensated.";
CM_ SG_ 522 ESP_driverBrakeApply "Indicates when the driver applies the brake pedal.";
CM_ SG_ 522 ESP_WheelRotationFrR "Rolling direction for front right wheel.";
CM_ SG_ 522 ESP_WheelRotationFrL "Rolling direction for front left wheel.";
CM_ SG_ 522 ESP_WheelRotationReR "Rolling direction for rear right wheel.";
CM_ SG_ 522 ESP_WheelRotationReL "Rolling direction for rear left wheel.";
CM_ SG_ 522 ESP_YawRateQF_LR "Yaw rate sensor qualifier";
CM_ SG_ 522 ESP_blsActive "Indicates when the brakes are applied by the driver or through ESP build.";
CM_ SG_ 522 ESP_parkBrakeRequest "ESP request to apply the park brake.";
CM_ SG_ 522 ESP_CChecksum "Message checksum for ESP_C: sum of all bytes in message (Unused fields are set to 0) + originating CAN ID (0x2 + 0x0A = 0x0C).";
CM_ SG_ 522 ESP_yawRate "Yaw rate is positive during a left turn. Offset compensated.";
CM_ SG_ 522 ESP_CCounter "Message counter for ESP_C message: increments in each message.";
CM_ SG_ 522 ESP_brakeCommandResponse "Brake command type executed by ESP.";
CM_ SG_ 522 ESP_brakeTorqueTarget "Brake torque that the ESP targets in response to an external request.";
CM_ SG_ 853 ESP_ebdActive "Electronic Brake Force Distribution is active. 1 = active.";
CM_ SG_ 853 ESP_tsmActive "Trailer Sway Mitigation controller is active. 1 = active.";
CM_ SG_ 853 ESP_eucActive "Enhanced Understeer Controler is active. 1 = active.";
CM_ SG_ 853 ESP_espAssistiBoosterActive "Active when the ESP builds pressure to assist the brake booster. 1 = active. (example blocked pedal)";
CM_ SG_ 853 ESP_hbaActive "Hydraulic Brake Assist is active. 1 = active.";
CM_ SG_ 853 ESP_hbcActive "Hydraulic Boost Compensation is active. 1 = active.";
CM_ SG_ 853 ESP_hfcActive "Hydrauluc Fade Compensation is active. 1 = active.";
CM_ SG_ 853 ESP_rmiActive "Rollover Mitigation Controller is active. 1 = active.";
CM_ SG_ 853 ESP_dMzOsActive "dMz oversteer controller is active. 1 = active.";
CM_ SG_ 853 ESP_dMzUsActive "dMz understeer controller is active. 1 = active.";
CM_ SG_ 853 ESP_absFrontAxleActive "ABS is active on the front axle. 1 = active.";
CM_ SG_ 853 ESP_absRearAxleActive "ABS is active on the rear axle. 1 = active.";
CM_ SG_ 853 ESP_driveTcActive "Traction controller is reducing motor drive torque magnitude. 1 = active.";
CM_ SG_ 853 ESP_regenTcActive "Traction controller is reducing motor regen torque magnitude. 1 = active.";
CM_ SG_ 853 ESP_brakeTractionControlActive "ESP is building pressure for brake traction control. 1 = active.";
CM_ SG_ 389 ESP_brakeTorqueFrL "ESP estimate of brake torque applied at front left wheel";
CM_ SG_ 389 ESP_brakeTorqueFrR "ESP estimate of brake torque applied at front right wheel";
CM_ SG_ 389 ESP_brakeTorqueReL "ESP estimate of brake torque applied at rear left wheel";
CM_ SG_ 389 ESP_brakeTorqueReR "ESP estimate of brake torque applied at rear right wheel";
CM_ SG_ 389 ESP_brakeTorqueQF "ESP Brake torque qualifier";
CM_ SG_ 389 ESP_brakeTorqueCounter "Message counter for ESP_brakeTorque message: increments in each message.";
CM_ SG_ 389 ESP_brakeTorqueChecksum "Message checksum for ESP_brakeTorque message: sum of all bytes in message (Unused fields are set to 0) + originating CAN ID (0x1 + 0x85 = 0x86).";
CM_ SG_ 949 ESP_d000_absPumpMotorControl "Bosch DTC value: 0x00402009";
CM_ SG_ 949 ESP_d001_wssFLLineGnd "Bosch DTC value: 0x00403111";
CM_ SG_ 949 ESP_d002_wssFLLineHigh "Bosch DTC value: 0x00403112";
CM_ SG_ 949 ESP_d003_wssFLLineUndef "Bosch DTC value: 0x00403114";
CM_ SG_ 949 ESP_d004_wssFLOutOfRange "Bosch DTC value: 0x00403122";
CM_ SG_ 949 ESP_d005_wssFLSignalMissing "Bosch DTC value: 0x00403131";
CM_ SG_ 949 ESP_d006_wssFLWrongSen "Bosch DTC value: 0x0040314A";
CM_ SG_ 949 ESP_d007_wssFLPlausibility "Bosch DTC value: 0x00403162";
CM_ SG_ 949 ESP_d008_wssFAWrongMounting "Bosch DTC value: 0x00403176";
CM_ SG_ 949 ESP_d009_wssFLAirGap "Bosch DTC value: 0x00403178";
CM_ SG_ 949 ESP_d010_wssFLSupGnd "Bosch DTC value: 0x00403211";
CM_ SG_ 949 ESP_d011_wssTstFLFld "Bosch DTC value: 0x00403212";
CM_ SG_ 949 ESP_d012_wssFRLineGnd "Bosch DTC value: 0x00403411";
CM_ SG_ 949 ESP_d013_wssFRLineHigh "Bosch DTC value: 0x00403412";
CM_ SG_ 949 ESP_d014_wssFRLineUndef "Bosch DTC value: 0x00403414";
CM_ SG_ 949 ESP_d015_wssFROutOfRange "Bosch DTC value: 0x00403422";
CM_ SG_ 949 ESP_d016_wssFRSignalMissing "Bosch DTC value: 0x00403431";
CM_ SG_ 949 ESP_d017_wssFRWrongSen "Bosch DTC value: 0x0040344A";
CM_ SG_ 949 ESP_d018_wssFRPlausibility "Bosch DTC value: 0x00403462";
CM_ SG_ 949 ESP_d019_wssMonWheelDirFR "Bosch DTC value: 0x00403476";
CM_ SG_ 949 ESP_d020_wssFRAirGap "Bosch DTC value: 0x00403478";
CM_ SG_ 949 ESP_d021_wssFRSupGnd "Bosch DTC value: 0x00403511";
CM_ SG_ 949 ESP_d022_wssTstFRFld "Bosch DTC value: 0x00403512";
CM_ SG_ 949 ESP_d023_wssRLLineGnd "Bosch DTC value: 0x00403711";
CM_ SG_ 949 ESP_d024_wssRLLineHigh "Bosch DTC value: 0x00403712";
CM_ SG_ 949 ESP_d025_wssRLLineUndef "Bosch DTC value: 0x00403714";
CM_ SG_ 949 ESP_d026_wssRLOutOfRange "Bosch DTC value: 0x00403722";
CM_ SG_ 949 ESP_d027_wssRLSignalMissing "Bosch DTC value: 0x00403731";
CM_ SG_ 949 ESP_d028_wssRLWrongSen "Bosch DTC value: 0x0040374A";
CM_ SG_ 949 ESP_d029_wssRLPlausibility "Bosch DTC value: 0x00403762";
CM_ SG_ 949 ESP_d030_wssRAWrongMounting "Bosch DTC value: 0x00403776";
CM_ SG_ 949 ESP_d031_wssRLAirGap "Bosch DTC value: 0x00403778";
CM_ SG_ 949 ESP_d032_wssRLSupGnd "Bosch DTC value: 0x00403811";
CM_ SG_ 949 ESP_d033_wssTstRLFld "Bosch DTC value: 0x00403812";
CM_ SG_ 949 ESP_d034_wssRRLineGnd "Bosch DTC value: 0x00403A11";
CM_ SG_ 949 ESP_d035_wssRRLineHigh "Bosch DTC value: 0x00403A12";
CM_ SG_ 949 ESP_d036_wssRRLineUndef "Bosch DTC value: 0x00403A14";
CM_ SG_ 949 ESP_d037_wssRROutOfRange "Bosch DTC value: 0x00403A22";
CM_ SG_ 949 ESP_d038_wssRRSignalMissing "Bosch DTC value: 0x00403A31";
CM_ SG_ 949 ESP_d039_wssRRWrongSen "Bosch DTC value: 0x00403A4A";
CM_ SG_ 949 ESP_d040_wssRRPlausibility "Bosch DTC value: 0x00403A62";
CM_ SG_ 949 ESP_d041_wssMonWheelDirRR "Bosch DTC value: 0x00403A76";
CM_ SG_ 949 ESP_d042_wssRRAirGap "Bosch DTC value: 0x00403A78";
CM_ SG_ 949 ESP_d043_wssRRSupGnd "Bosch DTC value: 0x00403B11";
CM_ SG_ 949 ESP_d044_wssTstRRFld "Bosch DTC value: 0x00403B12";
CM_ SG_ 949 ESP_d045_wssGeneralFault "Bosch DTC value: 0x00403D00";
CM_ SG_ 949 ESP_d046_brakeSwitchStuckHigh "Bosch DTC value: 0x00404024";
CM_ SG_ 949 ESP_d047_blsStatusInvd "Bosch DTC value: 0x00404029";
CM_ SG_ 949 ESP_d048_brakeSwitchPlausib "Bosch DTC value: 0x00404062";
CM_ SG_ 949 ESP_d049_pressSenMc1Line "Bosch DTC value: 0x00404414";
CM_ SG_ 949 ESP_d050_acmPsOfstMc1 "Bosch DTC value: 0x00404428";
CM_ SG_ 949 ESP_d051_acmPsTstpulseMc1 "Bosch DTC value: 0x00404462";
CM_ SG_ 949 ESP_d052_comSclLowBrakeFluid "Bosch DTC value: 0x0040497B";
CM_ SG_ 949 ESP_d053_sasMonConstSig "Bosch DTC value: 0x00405126";
CM_ SG_ 949 ESP_d054_sasMonOfst "Bosch DTC value: 0x00405128";
CM_ SG_ 949 ESP_d055_sasPlausibility "Bosch DTC value: 0x00405162";
CM_ SG_ 949 ESP_d056_aySensorFault "Bosch DTC value: 0x00406109";
CM_ SG_ 949 ESP_d057_aysMonRange "Bosch DTC value: 0x00406122";
CM_ SG_ 949 ESP_d058_aysOffset "Bosch DTC value: 0x00406128";
CM_ SG_ 949 ESP_d059_aysPlaus "Bosch DTC value: 0x00406162";
CM_ SG_ 949 ESP_d060_axSensorFault "Bosch DTC value: 0x00406209";
CM_ SG_ 949 ESP_d061_axsMonRange "Bosch DTC value: 0x00406222";
CM_ SG_ 949 ESP_d062_axOffsTooLarge "Bosch DTC value: 0x00406228";
CM_ SG_ 949 ESP_d063_axSensorPlaus "Bosch DTC value: 0x00406262";
CM_ SG_ 949 ESP_d064_yawSensorFault "Bosch DTC value: 0x00406309";
CM_ SG_ 949 ESP_d065_yawSensorPlaus "Bosch DTC value: 0x00406362";
CM_ SG_ 949 ESP_d066_absVdcContControl "Bosch DTC value: 0x00406B62";
CM_ SG_ 949 ESP_d067_undervoltage "Bosch DTC value: 0x00406C16";
CM_ SG_ 949 ESP_d068_overvoltage "Bosch DTC value: 0x00406C17";
CM_ SG_ 949 ESP_d069_memoryFault "Bosch DTC value: 0x00406C42";
CM_ SG_ 949 ESP_d070_ecuInternalGeneric "Bosch DTC value: 0x00406C49";
CM_ SG_ 949 ESP_d071_ecuInternalEcu "Bosch DTC value: 0x00406C49";
CM_ SG_ 949 ESP_d072_valveGeneric "Bosch DTC value: 0x00406C49";
CM_ SG_ 949 ESP_d073_valveAvFaults "Bosch DTC value: 0x00406C49";
CM_ SG_ 949 ESP_d074_valveEvFaults "Bosch DTC value: 0x00406C49";
CM_ SG_ 949 ESP_d075_valveHsvFaults "Bosch DTC value: 0x00406C49";
CM_ SG_ 949 ESP_d076_valveUsvFaults "Bosch DTC value: 0x00406C49";
CM_ SG_ 949 ESP_d077_refNotInitInTime "Bosch DTC value: 0x00406C68";
CM_ SG_ 949 ESP_d078_acmBtmOheatBraking "Bosch DTC value: 0x00407268";
CM_ SG_ 949 ESP_d079_varCodeEeprom "Bosch DTC value: 0x00520086";
CM_ SG_ 949 ESP_d080_reverseGearPlaus "Bosch DTC value: 0x00521062";
CM_ SG_ 949 ESP_d081_comSclVinAllZeroFF "Bosch DTC value: 0x00522051";
CM_ SG_ 949 ESP_d082_comSclVip405HsImpVin "Bosch DTC value: 0x00522062";
CM_ SG_ 949 ESP_d083_comSclVip405HsDtCrpt "Bosch DTC value: 0x00522081";
CM_ SG_ 949 ESP_d084_comSclVip405HsTout "Bosch DTC value: 0x00522087";
CM_ SG_ 949 ESP_d085_rollerBenchActv "Bosch DTC value: 0x00530068";
CM_ SG_ 949 ESP_d086_network0 "Bosch DTC value: 0x00B02800";
CM_ SG_ 949 ESP_d087_network1 "Bosch DTC value: 0x00B03700";
CM_ SG_ 949 ESP_d088_comMotorTOut "Bosch DTC value: 0x00C11087";
CM_ SG_ 949 ESP_d089_comDrsTxTOut "Bosch DTC value: 0x00C12587";
CM_ SG_ 949 ESP_d090_comSclStwAnglhpTout "Bosch DTC value: 0x00C12687";
CM_ SG_ 949 ESP_d091_comSclEpbStatusTout "Bosch DTC value: 0x00C12887";
CM_ SG_ 949 ESP_d092_comIbEsptTOut "Bosch DTC value: 0x00C12987";
CM_ SG_ 949 ESP_d093_comSclBdyStatusTout "Bosch DTC value: 0x00C14087";
CM_ SG_ 949 ESP_d094_comSclGtwEsp1Tout "Bosch DTC value: 0x00C14687";
CM_ SG_ 949 ESP_d095_comSclGtwOdoTout "Bosch DTC value: 0x00C14787";
CM_ SG_ 949 ESP_d096_comSclGtwCarCfgTout "Bosch DTC value: 0x00C14887";
CM_ SG_ 949 ESP_d097_comMotorCrpt "Bosch DTC value: 0x00C41181";
CM_ SG_ 949 ESP_d098_comMotorMsgCount "Bosch DTC value: 0x00C41182";
CM_ SG_ 949 ESP_d099_comMotorInvalidSig "Bosch DTC value: 0x00C41186";
CM_ SG_ 949 ESP_d100_comSclEpbStatusCrpt "Bosch DTC value: 0x00C41781";
CM_ SG_ 949 ESP_d101_comIbEspCrpt "Bosch DTC value: 0x00C41881";
CM_ SG_ 949 ESP_d102_comIbEspMsgCount "Bosch DTC value: 0x00C41882";
CM_ SG_ 949 ESP_d103_sclIbEspInvalidSig "Bosch DTC value: 0x00C41886";
CM_ SG_ 949 ESP_d104_comSclBdyStatusCrpt "Bosch DTC value: 0x00C42281";
CM_ SG_ 949 ESP_d105_comStwAnglHpCrpt "Bosch DTC value: 0x00C42881";
CM_ SG_ 949 ESP_d106_comStwAnglHpMsgCount "Bosch DTC value: 0x00C42882";
CM_ SG_ 949 ESP_d107_comSasInvalidSig "Bosch DTC value: 0x00C42886";
CM_ SG_ 949 ESP_d108_comDrsTxCrpt "Bosch DTC value: 0x00C43281";
CM_ SG_ 949 ESP_d109_sclMm3InvalidSig "Bosch DTC value: 0x00C43286";
CM_ SG_ 949 ESP_d110_comGtwEsp1Crpt "Bosch DTC value: 0x00C44781";
CM_ SG_ 949 ESP_d111_comSclGtwEsp1CntFlt "Bosch DTC value: 0x00C44782";
CM_ SG_ 949 ESP_d112_comSclGtwOdoDtCrpt "Bosch DTC value: 0x00C44881";
CM_ SG_ 949 ESP_d113_comSclGtwCrCfgDtCrpt "Bosch DTC value: 0x00C44981";
CM_ SG_ 949 ESP_d114_teslaChassisTypeSna "Bosch DTC value: 0x00C44986";
CM_ SG_ 949 ESP_d115_varPlatCalMismtch "Bosch DTC value: 0x00406C46";
CM_ SG_ 949 ESP_d116_ptsBlsStatusInvd "Bosch DTC value: 0x00C41986";
CM_ SG_ 949 ESP_d117_comSclBdwReqInvalid "Bosch DTC value: 0x00C44790";
CM_ SG_ 949 ESP_d118_rcmInvalidAx "Bosch DTC value: 0x00407209";
CM_ SG_ 949 ESP_d119_rcmInvalidAy "Bosch DTC value: 0x00407109";
CM_ SG_ 949 ESP_d120_rcmInvalidYaw "Bosch DTC value: 0x00407309";
CM_ SG_ 949 ESP_d121_rcmInvalidFrame1 "Bosch DTC value: 0x00C46281";
CM_ SG_ 949 ESP_d122_rcmInvalidFrame2 "Bosch DTC value: 0x00C13582";
CM_ SG_ 949 ESP_d123_rcmLostComm "Bosch DTC value: 0x00C13587";
CM_ SG_ 949 ESP_d124_rcmIncompleteSensInfo "Bosch DTC value: 0x00407202";
CM_ SG_ 949 ESP_d125_rcmSerialNumMismatch "Bosch DTC value: 0x00407203";
CM_ SG_ 949 ESP_d126_rcmWrongSensorConfig "Bosch DTC value: 0x00407200";
CM_ SG_ 949 ESP_d127_rcmInvalidCalibration "Bosch DTC value: 0x00407201";
CM_ SG_ 949 ESP_d128_comSclPmState2TOut "Bosch DTC value: 0x00C14987";
CM_ SG_ 949 ESP_d129_sclBdwReqActiveInvd "Bosch DTC value: 0x00C44791";
CM_ SG_ 949 ESP_d130_comPmState2Crpt "Bosch DTC value: 0x00C44A81";
CM_ SG_ 949 ESP_d131_comSclPmState2CntFlt "Bosch DTC value: 0x00C44A82";
CM_ SG_ 949 ESP_d132_sclPmEbrCmdStateInvd "Bosch DTC value: 0x00C44A86";
CM_ SG_ 949 ESP_d133_acmVsSignalPlaus "Bosch DTC value: 0x00404784";
CM_ SG_ 949 ESP_d134_sasMonRange "Bosch DTC value: 0x00405122";
CM_ SG_ 949 ESP_d135_sasMonGrad "Bosch DTC value: 0x00405127";
CM_ SG_ 949 ESP_d136_yrsSignalOutOfRange "Bosch DTC value: 0x00406322";
CM_ SG_ 949 ESP_d137_yrsMonGrad "Bosch DTC value: 0x00406327";
CM_ SG_ 949 ESP_d138_yrsOffsetTooLarge "Bosch DTC value: 0x00406328";
CM_ SG_ 949 ESP_d139_evpSigPlausibility "Bosch DTC value: 0x00501062";
CM_ SG_ 949 ESP_d140_evpVacSigLow "Bosch DTC value: 0x00501084";
CM_ SG_ 949 ESP_d141_vacSensorElectFail "Bosch DTC value: 0x00502001";
CM_ SG_ 949 ESP_d142_canCommGeneral "Bosch DTC value: 0x00B00100";
CM_ SG_ 949 ESP_d143_mcuChassisContrDtCrpt "Bosch DTC value: 0x00C90181";
CM_ SG_ 949 ESP_d144_mcuChassisContrTout "Bosch DTC value: 0x00C60187";
CM_ SG_ 533 ESP_ebrStatusChecksum "Message checksum for ESP_ebrStatus message: sum of all bytes in message (Unused fields are set to 0) + originating CAN ID (0x2 + 0x15 = 0x17).";
CM_ SG_ 533 ESP_ebrStatusCounter "Message counter: increments in each message.";
CM_ SG_ 533 ESP_ebrMode "State of ESP only to perform autonomous braking.";
CM_ SG_ 533 ESP_ebrSystemMode "State of system (ESP and IBST) to perform autonomous braking.";
CM_ SG_ 533 ESP_brakeTorqueTarget2 "Brake torque that the ESP targets in response to an external request.";
CM_ SG_ 533 ESP_ebrSource "Current source of external brake torque";
CM_ SG_ 533 ESP_ebrState "Current EBR activity";
CM_ SG_ 901 ESP_latAccelOffsetComp "Lateral acclereation sensor offset";
CM_ SG_ 901 ESP_longAccelOffsetComp "Longitudinal sensor offset";
CM_ SG_ 901 ESP_yawrateOffsetComp "Yaw rate sensor offset";
CM_ SG_ 901 ESP_masterCylOffsetComp "Offset for master cylinder pressure sensor.";
CM_ SG_ 901 ESP_offsetsCounter "Message counter for ESP_offsets message, increments in each message.";
CM_ SG_ 901 ESP_offsetsChecksum "Message checksum for ESP_offsets message: sum of all bytes in message (Unused fields are set to 0) + originating CAN ID (0x3 + 0x85 = 0x88)";
CM_ SG_ 285 ESP_vdcStatusChecksum "Message checksum for ESP_vdcStatus message: sum of all bytes in message + 0x1E";
CM_ SG_ 285 ESP_vdcStatusCounter "Message counter for ESP_vdcStatus message: increments in each message.";
CM_ SG_ 285 ESP_wheelSlipFrL "Front left wheel brake slip";
CM_ SG_ 285 ESP_wheelSlipFrR "Front right wheel brake slip";
CM_ SG_ 285 ESP_wheelSlipReL "Rear left wheel brake slip";
CM_ SG_ 285 ESP_wheelSlipReR "Rear right wheel brake slip";
CM_ SG_ 285 ESP_vdcActuatorState "ESP actuatior availability to perform VDC adn BTC brake commands.";
CM_ SG_ 285 ESP_wheelSaturationFrL "Front left wheel saturation reason during VDC command";
CM_ SG_ 285 ESP_wheelSaturationFrR "Front right wheel saturation reason during VDC command";
CM_ SG_ 285 ESP_wheelSaturationReL "Rear left wheel saturation reason during VDC command";
CM_ SG_ 285 ESP_wheelSaturationReR "Rear right wheel saturation reason during VDC command";
CM_ SG_ 373 ESP_wheelSpeedFrL_HS "High rate wheel speed signal for front left.";
CM_ SG_ 373 ESP_wheelSpeedFrR_HS "High rate wheel speed signal for front right.";
CM_ SG_ 373 ESP_wheelSpeedReL_HS "High rate wheel speed signal for rear left.";
CM_ SG_ 373 ESP_wheelSpeedReR_HS "High rate wheel speed signal for rear right.";
CM_ SG_ 373 ESP_wheelSpeedsCounter "Message counter for ESP_wheelSpeeds message: increments in each message.";
CM_ SG_ 373 ESP_wheelSpeedsChecksum "Message checksum for ESP_wheelSpeeds: sum of all bytes in message (Unused fields are set to 0) + originating CAN ID (0x1 + 0x75 = 0x76).";
CM_ SG_ 520 GTW_ESP1Counter "Message counter for esp message, increments in each message.";
CM_ SG_ 520 GTW_hillStartAssistDisabled "Signal to disable the hill start assist feature. Was implemented as an enable signal prior to BL6.";
CM_ SG_ 520 GTW_brakeDiscWipeRequest "Request to trigger the brake disc wipe function in the ESP.";
CM_ SG_ 520 GTW_brakeFluidLow "Low brake fluid warning. Bosch qualification time on this is 20 seconds.";
CM_ SG_ 520 GTW_pedalCalRxEnable "Indication whether switching of pedal calibration target curves is allowed.";
CM_ SG_ 520 GTW_ambientTemperature "Ambient temperature (unfiltered value)";
CM_ SG_ 520 GTW_pedalCalTargetCurve "Indicates the desired iBooster pedal feel curve.";
CM_ SG_ 520 GTW_espModeSwitch "Periodic signal that is implemented like a momentary switch to indicate the user selected ESP mode.";
CM_ SG_ 520 GTW_ESP1Checksum "Message checksum for GTW_ESP1 message: sum of all bytes in message + originating CAN ID (0x2 + 0x08 = 0x0A)";
CM_ SG_ 552 GTW_airbagCutoffStatusChecksum "Checksum method for GTW_airbagCutoffStatus: sum of byte0 + originating CAN ID (0x2 + 0x28 = 0x2A).";
CM_ SG_ 920 GTW_country "2 character country code as defined in http://en.wikipedia.org/wiki/ISO_3166-1";
CM_ SG_ 792 YEAR "Current Year";
CM_ SG_ 792 CERRD "Enables CAN error detection in EAS";
CM_ SG_ 792 MONTH "Current Month";
CM_ SG_ 792 DOOR_STATE_FL "Door status front left";
CM_ SG_ 792 DOOR_STATE_FR "Door status front riht";
CM_ SG_ 792 SECOND "Current Secound";
CM_ SG_ 792 DOOR_STATE_RL "Door status rear left";
CM_ SG_ 792 Hour "Current hour";
CM_ SG_ 792 DOOR_STATE_RR "Door status rear right";
CM_ SG_ 792 DAY "Current Day";
CM_ SG_ 792 BC_courtesyLightingActive "Status of courtesy lighting";
CM_ SG_ 792 MINUTE "Current Minute";
CM_ SG_ 792 BOOT_STATE "Tailgate/Boot status";
CM_ SG_ 792 GTW_updateInProgress "Update in progress. Car not operable";
CM_ SG_ 792 DOOR_STATE_FrontTrunk "Door status front trunk";
CM_ SG_ 792 BC_headLightLStatus "Left headlight status";
CM_ SG_ 792 BC_headLightRStatus "Right headlight status";
CM_ SG_ 792 BC_indicatorLStatus "Left indicator status";
CM_ SG_ 792 BC_indicatorRStatus "Right indicator status";
CM_ SG_ 296 REV_GEAR "Reverse gear information";
CM_ SG_ 296 GTW_diagDriveState "Diagnostic drive session state";
CM_ SG_ 296 ENG_RPM "Engine revolutions per minute";
CM_ SG_ 257 GTW_epasLDWEnabled "Sets whether the gear should obey LDW requests or not.";
CM_ SG_ 257 GTW_epasControlChecksum "Checksum for the epasControl message. Sum of all data bytes + originating ID (0x01 + 0x01)";
CM_ SG_ 776 GTW_easManualLevelRequest "UI (MCU) customer level request; Jack mode is used to disable leveling.";
CM_ SG_ 776 HVBatteryLow "Indication to Conti that we don't want them to use energy by leveling in postrun.";
CM_ SG_ 776 GTW_espPlatCalMismatch "Indication to the ESP that the calibration version does not match.";
CM_ SG_ 776 GTW_ibstConnectivityDisable "Signal to disable the iBooster from transmitting the connectivity messages for logging.";
CM_ SG_ 776 AMB_TEMP "Ambience temperature";
CM_ SG_ 776 GTW_ODO "Odometer";
CM_ SG_ 936 GTW_wouldSleep "The conditions for gateway sleep are all met. We would sleep if the UI told us.";
CM_ SG_ 840 GTW_icPowerOff "Indicates that the gateway may soon pull power away from the instrument cluster.  This allows the IC to do a controlled shutdown.";
CM_ SG_ 840 GTW_hvacRailIsOn "GTW reporting HVAC rail is ON when set 1.";
CM_ SG_ 1800 GTW_timeSecs "Seconds from Jan. 1, 1970";
BA_DEF_ BO_ "AlertLogSubSystemId" INT 0 0;
BA_DEF_ BO_ "AlertType" INT 0 4;
BA_DEF_ BO_ "AppBotschaft" ENUM "nein","ja";
BA_DEF_ BO_ "DiagRequest" ENUM "No","Yes";
BA_DEF_ BO_ "DiagResponse" ENUM "No","Yes";
BA_DEF_ BO_ "ETHGatewayMessageSendType" ENUM "UseGenMsgSendType","onWrite","noAutoCode";
BA_DEF_ BO_ "ETHId" STRING ;
BA_DEF_ BO_ "GatewayHandlerEnum" ENUM "noHandler","uds","alertLog","messageLogOnReception","udsClient";
BA_DEF_ BO_ "GatewayMessageAtomic" ENUM "No","Yes";
BA_DEF_ BO_ "GatewayMessageSendType" ENUM "UseGenMsgSendType","onWrite","noAutoCode";
BA_DEF_ BO_ "GenMsgCycleTime" INT 0 0;
BA_DEF_ BO_ "GenMsgCycleTimeFast" INT 0 0;
BA_DEF_ BO_ "GenMsgDelayTime" INT 0 0;
BA_DEF_ BO_ "GenMsgForceMiaCheck" ENUM "No","Yes";
BA_DEF_ BO_ "GenMsgGatewayNotification" STRING ;
BA_DEF_ BO_ "GenMsgILSupport" ENUM "No","Yes";
BA_DEF_ BO_ "GenMsgSaltingFunction" ENUM "No","Yes";
BA_DEF_ BO_ "GenMsgSendType" ENUM "Cyclic","NotUsed","NotUsed","NotUsed","NotUsed","NotUsed","NotUsed","IfActive","NoMsgSendType","Sporadic";
BA_DEF_ BO_ "GenMsgStartValue" STRING ;
BA_DEF_ BO_ "GenMsgTimeOut" INT 0 0;
BA_DEF_ BO_ "MessageIdType" ENUM "normal","udsRequest","udsResponse","udsReserved","udsFunctionalRequest","networkManagement","bootloader","xcp","dtc","diagnostic","vendorExempt";
BA_DEF_ BO_ "NWMBotschaft" ENUM "nein","ja";
BA_DEF_ BO_ "NmMessage" ENUM "No","Yes";
BA_DEF_ BO_ "SubSystemId" INT 0 256;
BA_DEF_ BO_ "UsesChecksum" ENUM "No","Yes";
BA_DEF_ SG_ "FieldType" STRING ;
BA_DEF_ SG_ "FlexKomComment" STRING ;
BA_DEF_ SG_ "FlexKomIsMotorola" ENUM "nein","ja";
BA_DEF_ SG_ "FlexKomSID" INT 0 2147483647;
BA_DEF_ SG_ "FlexKomSigLaenge" INT 0 64;
BA_DEF_ SG_ "FlexKomSigName" STRING ;
BA_DEF_ SG_ "FlexKomSigStartPos" INT 0 63;
BA_DEF_ SG_ "FlexKomSigStartValue" STRING ;
BA_DEF_ SG_ "Gatewaysignal" INT 0 1;
BA_DEF_ SG_ "GenSigCycleTime" INT 0 0;
BA_DEF_ SG_ "GenSigCycleTimeActive" INT 0 0;
BA_DEF_ SG_ "GenSigPersistent" ENUM "No","Yes";
BA_DEF_ SG_ "GenSigSNA" STRING ;
BA_DEF_ SG_ "GenSigSendType" ENUM "Cyclic","OnWrite","OnWriteWithRepetition","OnChange","OnChangeWithRepetition","IfActive","IfActiveWithRepetition","NoSigSendType","NotUsed","NotUsed","NotUsed","NotUsed","NotUsed";
BA_DEF_ SG_ "GenSigStartValue" INT 0 0;
BA_DEF_ SG_ "GenSigTimeout_CGW" INT 0 65535;
BA_DEF_ SG_ "GenSigTimeout_DRVU" INT 0 65535;
BA_DEF_ SG_ "GenSigTimeout_ECM" INT 0 65535;
BA_DEF_ SG_ "GenSigTimeout_EIS" INT 0 65535;
BA_DEF_ SG_ "GenSigTimeout_EPS" INT 0 65535;
BA_DEF_ SG_ "GenSigTimeout_ESP_ABR" INT 0 65535;
BA_DEF_ SG_ "GenSigTimeout_IC" INT 0 65535;
BA_DEF_ SG_ "GenSigTimeout_MPC" INT 0 65535;
BA_DEF_ SG_ "GenSigTimeout_NV" INT 0 65535;
BA_DEF_ SG_ "GenSigTimeout_ORC" INT 0 65535;
BA_DEF_ SG_ "GenSigTimeout_PTS" INT 0 65535;
BA_DEF_ SG_ "GenSigTimeout_RBTM_FL" INT 0 65535;
BA_DEF_ SG_ "GenSigTimeout_RBTM_FR" INT 0 65535;
BA_DEF_ SG_ "GenSigTimeout_RDU" INT 0 65535;
BA_DEF_ SG_ "GenSigTimeout_SCCM" INT 0 65535;
BA_DEF_ SG_ "GenSigTimeout_SPC" INT 0 65535;
BA_DEF_ SG_ "GenSigTimeout_TPM" INT 0 65535;
BA_DEF_ SG_ "LogSignal" STRING ;
BA_DEF_ SG_ "PektronUpdateBitType" ENUM "Not used","Has update bit","Is update bit";
BA_DEF_REL_ BU_SG_REL_ "GenSigTimeoutTime" INT 0 0;

BA_DEF_DEF_ "AlertLogSubSystemId" 0;
BA_DEF_DEF_ "AlertType" 4;
BA_DEF_DEF_ "AppBotschaft" "nein";
BA_DEF_DEF_ "DiagRequest" "No";
BA_DEF_DEF_ "DiagResponse" "No";
BA_DEF_DEF_ "ETHGatewayMessageSendType" "UseGenMsgSendType";
BA_DEF_DEF_ "ETHId" "";
BA_DEF_DEF_ "FieldType" "";
BA_DEF_DEF_ "FlexKomComment" "";
BA_DEF_DEF_ "FlexKomIsMotorola" "";
BA_DEF_DEF_ "FlexKomSID" 0;
BA_DEF_DEF_ "FlexKomSigLaenge" 0;
BA_DEF_DEF_ "FlexKomSigName" "";
BA_DEF_DEF_ "FlexKomSigStartPos" 0;
BA_DEF_DEF_ "FlexKomSigStartValue" "";
BA_DEF_DEF_ "GatewayHandlerEnum" "noHandler";
BA_DEF_DEF_ "GatewayMessageAtomic" "No";
BA_DEF_DEF_ "GatewayMessageSendType" "UseGenMsgSendType";
BA_DEF_DEF_ "Gatewaysignal" 0;
BA_DEF_DEF_ "GenMsgCycleTime" 0;
BA_DEF_DEF_ "GenMsgCycleTimeFast" 0;
BA_DEF_DEF_ "GenMsgDelayTime" 0;
BA_DEF_DEF_ "GenMsgForceMiaCheck" "No";
BA_DEF_DEF_ "GenMsgGatewayNotification" "";
BA_DEF_DEF_ "GenMsgILSupport" "Yes";
BA_DEF_DEF_ "GenMsgSaltingFunction" "No";
BA_DEF_DEF_ "GenMsgSendType" "Cyclic";
BA_DEF_DEF_ "GenMsgStartValue" "";
BA_DEF_DEF_ "GenMsgTimeOut" 0;
BA_DEF_DEF_ "GenSigCycleTime" 0;
BA_DEF_DEF_ "GenSigCycleTimeActive" 0;
BA_DEF_DEF_ "GenSigPersistent" "No";
BA_DEF_DEF_ "GenSigSNA" "";
BA_DEF_DEF_ "GenSigSendType" "Cyclic";
BA_DEF_DEF_ "GenSigStartValue" 0;
BA_DEF_DEF_ "GenSigTimeout_CGW" 0;
BA_DEF_DEF_ "GenSigTimeout_DRVU" 0;
BA_DEF_DEF_ "GenSigTimeout_ECM" 0;
BA_DEF_DEF_ "GenSigTimeout_EIS" 0;
BA_DEF_DEF_ "GenSigTimeout_EPS" 0;
BA_DEF_DEF_ "GenSigTimeout_ESP_ABR" 0;
BA_DEF_DEF_ "GenSigTimeout_IC" 0;
BA_DEF_DEF_ "GenSigTimeout_MPC" 0;
BA_DEF_DEF_ "GenSigTimeout_NV" 0;
BA_DEF_DEF_ "GenSigTimeout_ORC" 0;
BA_DEF_DEF_ "GenSigTimeout_PTS" 0;
BA_DEF_DEF_ "GenSigTimeout_RBTM_FL" 0;
BA_DEF_DEF_ "GenSigTimeout_RBTM_FR" 0;
BA_DEF_DEF_ "GenSigTimeout_RDU" 0;
BA_DEF_DEF_ "GenSigTimeout_SCCM" 0;
BA_DEF_DEF_ "GenSigTimeout_SPC" 0;
BA_DEF_DEF_ "GenSigTimeout_TPM" 0;
BA_DEF_DEF_ "LogSignal" "";
BA_DEF_DEF_ "MessageIdType" "normal";
BA_DEF_DEF_ "NWMBotschaft" "nein";
BA_DEF_DEF_ "NmMessage" "No";
BA_DEF_DEF_ "PektronUpdateBitType" "Not used";
BA_DEF_DEF_ "SubSystemId" 0;
BA_DEF_DEF_ "UsesChecksum" "No";
BA_DEF_DEF_REL_ "GenSigTimeoutTime" 0;
BA_ "GenMsgCycleTime" BO_ 325 20;
BA_ "GenMsgCycleTime" BO_ 336 500;
BA_ "GenMsgSaltingFunction" BO_ 336 1;
BA_ "GenMsgCycleTime" BO_ 341 20;
BA_ "GenMsgTimeOut" BO_ 341 500;
BA_ "GenMsgCycleTime" BO_ 522 20;
BA_ "MessageIdType" BO_ 522 10;
BA_ "GenMsgCycleTime" BO_ 693 500;
BA_ "GenMsgSaltingFunction" BO_ 693 1;
BA_ "GenMsgDelayTime" BO_ 853 20;
BA_ "GenMsgGatewayNotification" BO_ 853 "espActiveStatesHandler";
BA_ "GenMsgSendType" BO_ 853 8;
BA_ "AlertLogSubSystemId" BO_ 1285 17;
BA_ "GatewayHandlerEnum" BO_ 1285 2;
BA_ "GenMsgSendType" BO_ 1285 8;
BA_ "GenMsgCycleTime" BO_ 1606 500;
BA_ "GenMsgCycleTime" BO_ 389 20;
BA_ "GenMsgCycleTime" BO_ 949 1000;
BA_ "GenMsgCycleTime" BO_ 533 20;
BA_ "GenMsgCycleTime" BO_ 805 10000;
BA_ "GenMsgCycleTime" BO_ 901 200;
BA_ "DiagResponse" BO_ 1621 1;
BA_ "GatewayHandlerEnum" BO_ 1621 4;
BA_ "GenMsgCycleTime" BO_ 1621 100;
BA_ "GenMsgCycleTimeFast" BO_ 1621 100;
BA_ "GenMsgDelayTime" BO_ 1621 20;
BA_ "GenMsgSendType" BO_ 1621 8;
BA_ "MessageIdType" BO_ 1621 2;
BA_ "GenMsgCycleTime" BO_ 285 20;
BA_ "GenMsgCycleTime" BO_ 373 10;
BA_ "GenMsgCycleTime" BO_ 520 100;
BA_ "GenMsgSaltingFunction" BO_ 520 1;
BA_ "GenMsgCycleTime" BO_ 552 100;
BA_ "GenMsgSaltingFunction" BO_ 552 1;
BA_ "GenMsgCycleTime" BO_ 1992 100;
BA_ "GenMsgSaltingFunction" BO_ 1992 1;
BA_ "GenMsgCycleTime" BO_ 920 1000;
BA_ "GenMsgCycleTime" BO_ 857 1000;
BA_ "GatewayMessageAtomic" BO_ 792 1;
BA_ "GenMsgCycleTime" BO_ 792 100;
BA_ "GenMsgCycleTimeFast" BO_ 792 100;
BA_ "GenMsgDelayTime" BO_ 792 20;
BA_ "GenMsgTimeOut" BO_ 792 500;
BA_ "GenMsgCycleTime" BO_ 1048 100;
BA_ "GenMsgSaltingFunction" BO_ 1048 1;
BA_ "GenMsgCycleTime" BO_ 1912 1000;
BA_ "GenMsgSaltingFunction" BO_ 1912 1;
BA_ "GenMsgCycleTime" BO_ 1864 1000;
BA_ "GenMsgCycleTime" BO_ 296 100;
BA_ "GenMsgCycleTimeFast" BO_ 296 100;
BA_ "GenMsgDelayTime" BO_ 296 20;
BA_ "GenMsgTimeOut" BO_ 296 500;
BA_ "GatewayMessageAtomic" BO_ 257 1;
BA_ "GenMsgCycleTime" BO_ 257 100;
BA_ "GenMsgSaltingFunction" BO_ 257 1;
BA_ "MessageIdType" BO_ 257 10;
BA_ "GenMsgCycleTime" BO_ 1281 100;
BA_ "GenMsgSaltingFunction" BO_ 1281 1;
BA_ "MessageIdType" BO_ 1281 10;
BA_ "GenMsgCycleTime" BO_ 1368 10000;
BA_ "GenMsgCycleTime" BO_ 888 1000;
BA_ "GenMsgCycleTime" BO_ 2008 1000;
BA_ "GenMsgSaltingFunction" BO_ 2008 1;
BA_ "GatewayMessageAtomic" BO_ 776 1;
BA_ "GenMsgCycleTime" BO_ 776 100;
BA_ "GenMsgCycleTimeFast" BO_ 776 100;
BA_ "GenMsgDelayTime" BO_ 776 20;
BA_ "GenMsgTimeOut" BO_ 776 500;
BA_ "GenMsgCycleTime" BO_ 1960 1000;
BA_ "GenMsgSaltingFunction" BO_ 1960 1;
BA_ "GatewayMessageAtomic" BO_ 936 1;
BA_ "GenMsgCycleTime" BO_ 936 1000;
BA_ "GenMsgSaltingFunction" BO_ 936 1;
BA_ "GatewayMessageAtomic" BO_ 1832 1;
BA_ "GenMsgCycleTime" BO_ 1832 1000;
BA_ "GenMsgSaltingFunction" BO_ 1832 1;
BA_ "GenMsgCycleTime" BO_ 1880 1000;
BA_ "GenMsgCycleTime" BO_ 1896 60000;
BA_ "GenMsgCycleTime" BO_ 840 100;
BA_ "GenMsgSaltingFunction" BO_ 840 1;
BA_ "GenMsgCycleTime" BO_ 1800 300000;
BA_ "GenMsgSaltingFunction" BO_ 1800 1;
BA_ "GatewayMessageSendType" BO_ 856 1;
BA_ "GenMsgCycleTime" BO_ 856 1000;
BA_ "AlertLogSubSystemId" BO_ 1469 198;
BA_ "GatewayHandlerEnum" BO_ 1469 2;
BA_ "GenMsgSendType" BO_ 1469 8;
BA_ "GenMsgCycleTime" BO_ 1645 500;
BA_ "GenSigSNA" SG_ 325 ESP_longitudinalAccel "1023";
BA_ "GenSigStartValue" SG_ 325 ESP_longitudinalAccel 512;
BA_ "LogSignal" SG_ 325 ESP_longitudinalAccel "periodic ONE_SECOND driveModeModelS";
BA_ "GenSigSNA" SG_ 325 ESP_stabilityControlSts2 "7";
BA_ "GenSigSNA" SG_ 325 ESP_lateralAccel "1023";
BA_ "GenSigStartValue" SG_ 325 ESP_lateralAccel 512;
BA_ "LogSignal" SG_ 325 ESP_lateralAccel "periodic ONE_SECOND driveModeModelS";
BA_ "GenSigSNA" SG_ 325 ESP_btcTargetState "3";
BA_ "GenSigSNA" SG_ 325 ESP_ptcTargetState "3";
BA_ "LogSignal" SG_ 325 ESP_ptcTargetState "onChange";
BA_ "GenSigSNA" SG_ 325 ESP_brakeMasterCylPress "1023";
BA_ "GenSigStartValue" SG_ 325 ESP_brakeMasterCylPress 170;
BA_ "LogSignal" SG_ 325 ESP_brakeMasterCylPress "periodic ONE_SECOND driveModeModelS and NorwayCar";
BA_ "GenSigSNA" SG_ 341 ESP_wheelPulseCountFrL "255";
BA_ "GenSigSNA" SG_ 341 ESP_wheelPulseCountFrR "255";
BA_ "GenSigSNA" SG_ 341 ESP_wheelPulseCountReL "255";
BA_ "GenSigSNA" SG_ 341 ESP_wheelPulseCountReR "255";
BA_ "GenSigSNA" SG_ 341 ESP_vehicleSpeedQF "0";
BA_ "GenSigCycleTime" SG_ 522 ESP_YawRate_LR 100;
BA_ "GenSigCycleTimeActive" SG_ 522 ESP_YawRate_LR 100;
BA_ "GenSigStartValue" SG_ 522 ESP_YawRate_LR 500;
BA_ "GenSigSNA" SG_ 522 ESP_driverBrakeApply "3";
BA_ "LogSignal" SG_ 522 ESP_driverBrakeApply "onChange";
BA_ "FieldType" SG_ 522 ESP_WheelRotationFrR "ESP_WheelRotation";
BA_ "GenSigCycleTime" SG_ 522 ESP_WheelRotationFrR 100;
BA_ "GenSigCycleTimeActive" SG_ 522 ESP_WheelRotationFrR 100;
BA_ "FieldType" SG_ 522 ESP_WheelRotationFrL "ESP_WheelRotation";
BA_ "GenSigCycleTime" SG_ 522 ESP_WheelRotationFrL 100;
BA_ "GenSigCycleTimeActive" SG_ 522 ESP_WheelRotationFrL 100;
BA_ "FieldType" SG_ 522 ESP_WheelRotationReR "ESP_WheelRotation";
BA_ "GenSigCycleTime" SG_ 522 ESP_WheelRotationReR 100;
BA_ "GenSigCycleTimeActive" SG_ 522 ESP_WheelRotationReR 100;
BA_ "FieldType" SG_ 522 ESP_WheelRotationReL "ESP_WheelRotation";
BA_ "GenSigCycleTime" SG_ 522 ESP_WheelRotationReL 100;
BA_ "GenSigCycleTimeActive" SG_ 522 ESP_WheelRotationReL 100;
BA_ "GenSigCycleTime" SG_ 522 ESP_YawRateQF_LR 100;
BA_ "GenSigCycleTimeActive" SG_ 522 ESP_YawRateQF_LR 100;
BA_ "GenSigCycleTime" SG_ 522 ESP_CChecksum 10;
BA_ "GenSigSNA" SG_ 522 ESP_yawRate "4095";
BA_ "GenSigStartValue" SG_ 522 ESP_yawRate 2000;
BA_ "FlexKomComment" SG_ 522 ESP_CCounter "Momentenanforderung ESP";
BA_ "FlexKomIsMotorola" SG_ 522 ESP_CCounter 1;
BA_ "FlexKomSID" SG_ 522 ESP_CCounter 33554835;
BA_ "FlexKomSigLaenge" SG_ 522 ESP_CCounter 40;
BA_ "FlexKomSigStartPos" SG_ 522 ESP_CCounter 15;
BA_ "FlexKomSigStartValue" SG_ 522 ESP_CCounter "8000001FFFh";
BA_ "GenSigCycleTime" SG_ 522 ESP_CCounter 10;
BA_ "GenSigSNA" SG_ 522 ESP_brakeCommandResponse "7";
BA_ "GenSigSNA" SG_ 522 ESP_brakeTorqueTarget "8191";
BA_ "GenSigSendType" SG_ 853 ESP_ebdActive 3;
BA_ "GenSigSendType" SG_ 853 ESP_tsmActive 3;
BA_ "LogSignal" SG_ 853 ESP_tsmActive "onChange";
BA_ "GenSigSendType" SG_ 853 ESP_eucActive 3;
BA_ "LogSignal" SG_ 853 ESP_eucActive "onChange";
BA_ "GenSigSendType" SG_ 853 ESP_espAssistiBoosterActive 3;
BA_ "LogSignal" SG_ 853 ESP_espAssistiBoosterActive "onChange";
BA_ "GenSigSendType" SG_ 853 ESP_hbaActive 3;
BA_ "LogSignal" SG_ 853 ESP_hbaActive "onChange";
BA_ "GenSigSendType" SG_ 853 ESP_hbcActive 3;
BA_ "LogSignal" SG_ 853 ESP_hbcActive "onChange";
BA_ "GenSigSendType" SG_ 853 ESP_hfcActive 3;
BA_ "LogSignal" SG_ 853 ESP_hfcActive "onChange";
BA_ "GenSigSendType" SG_ 853 ESP_rmiActive 3;
BA_ "LogSignal" SG_ 853 ESP_rmiActive "onChange";
BA_ "GenSigSendType" SG_ 853 ESP_dMzOsActive 3;
BA_ "LogSignal" SG_ 853 ESP_dMzOsActive "onChange";
BA_ "GenSigSendType" SG_ 853 ESP_dMzUsActive 3;
BA_ "LogSignal" SG_ 853 ESP_dMzUsActive "onChange";
BA_ "GenSigSendType" SG_ 853 ESP_absFrontAxleActive 3;
BA_ "GenSigSendType" SG_ 853 ESP_absRearAxleActive 3;
BA_ "GenSigSendType" SG_ 853 ESP_driveTcActive 3;
BA_ "GenSigSendType" SG_ 853 ESP_regenTcActive 3;
BA_ "FlexKomIsMotorola" SG_ 389 ESP_brakeTorqueFrL 1;
BA_ "GenSigSNA" SG_ 389 ESP_brakeTorqueFrL "4095";
BA_ "FlexKomIsMotorola" SG_ 389 ESP_brakeTorqueFrR 1;
BA_ "GenSigSNA" SG_ 389 ESP_brakeTorqueFrR "4095";
BA_ "FlexKomIsMotorola" SG_ 389 ESP_brakeTorqueReL 1;
BA_ "GenSigSNA" SG_ 389 ESP_brakeTorqueReL "4095";
BA_ "FlexKomIsMotorola" SG_ 389 ESP_brakeTorqueReR 1;
BA_ "GenSigSNA" SG_ 389 ESP_brakeTorqueReR "4095";
BA_ "FlexKomIsMotorola" SG_ 389 ESP_brakeTorqueCounter 1;
BA_ "FieldType" SG_ 949 ESP_d000_absPumpMotorControl "DTC_VALUES";
BA_ "FieldType" SG_ 949 ESP_d001_wssFLLineGnd "DTC_VALUES";
BA_ "FieldType" SG_ 949 ESP_d002_wssFLLineHigh "DTC_VALUES";
BA_ "FieldType" SG_ 949 ESP_d003_wssFLLineUndef "DTC_VALUES";
BA_ "FieldType" SG_ 949 ESP_d004_wssFLOutOfRange "DTC_VALUES";
BA_ "FieldType" SG_ 949 ESP_d005_wssFLSignalMissing "DTC_VALUES";
BA_ "FieldType" SG_ 949 ESP_d006_wssFLWrongSen "DTC_VALUES";
BA_ "FieldType" SG_ 949 ESP_d007_wssFLPlausibility "DTC_VALUES";
BA_ "FieldType" SG_ 949 ESP_d008_wssFAWrongMounting "DTC_VALUES";
BA_ "FieldType" SG_ 949 ESP_d009_wssFLAirGap "DTC_VALUES";
BA_ "FieldType" SG_ 949 ESP_d010_wssFLSupGnd "DTC_VALUES";
BA_ "FieldType" SG_ 949 ESP_d011_wssTstFLFld "DTC_VALUES";
BA_ "FieldType" SG_ 949 ESP_d012_wssFRLineGnd "DTC_VALUES";
BA_ "FieldType" SG_ 949 ESP_d013_wssFRLineHigh "DTC_VALUES";
BA_ "FieldType" SG_ 949 ESP_d014_wssFRLineUndef "DTC_VALUES";
BA_ "FieldType" SG_ 949 ESP_d015_wssFROutOfRange "DTC_VALUES";
BA_ "FieldType" SG_ 949 ESP_d016_wssFRSignalMissing "DTC_VALUES";
BA_ "FieldType" SG_ 949 ESP_d017_wssFRWrongSen "DTC_VALUES";
BA_ "FieldType" SG_ 949 ESP_d018_wssFRPlausibility "DTC_VALUES";
BA_ "FieldType" SG_ 949 ESP_d019_wssMonWheelDirFR "DTC_VALUES";
BA_ "FieldType" SG_ 949 ESP_d020_wssFRAirGap "DTC_VALUES";
BA_ "FieldType" SG_ 949 ESP_d021_wssFRSupGnd "DTC_VALUES";
BA_ "FieldType" SG_ 949 ESP_d022_wssTstFRFld "DTC_VALUES";
BA_ "FieldType" SG_ 949 ESP_d023_wssRLLineGnd "DTC_VALUES";
BA_ "FieldType" SG_ 949 ESP_d024_wssRLLineHigh "DTC_VALUES";
BA_ "FieldType" SG_ 949 ESP_d025_wssRLLineUndef "DTC_VALUES";
BA_ "FieldType" SG_ 949 ESP_d026_wssRLOutOfRange "DTC_VALUES";
BA_ "FieldType" SG_ 949 ESP_d027_wssRLSignalMissing "DTC_VALUES";
BA_ "FieldType" SG_ 949 ESP_d028_wssRLWrongSen "DTC_VALUES";
BA_ "FieldType" SG_ 949 ESP_d029_wssRLPlausibility "DTC_VALUES";
BA_ "FieldType" SG_ 949 ESP_d030_wssRAWrongMounting "DTC_VALUES";
BA_ "FieldType" SG_ 949 ESP_d031_wssRLAirGap "DTC_VALUES";
BA_ "FieldType" SG_ 949 ESP_d032_wssRLSupGnd "DTC_VALUES";
BA_ "FieldType" SG_ 949 ESP_d033_wssTstRLFld "DTC_VALUES";
BA_ "FieldType" SG_ 949 ESP_d034_wssRRLineGnd "DTC_VALUES";
BA_ "FieldType" SG_ 949 ESP_d035_wssRRLineHigh "DTC_VALUES";
BA_ "FieldType" SG_ 949 ESP_d036_wssRRLineUndef "DTC_VALUES";
BA_ "FieldType" SG_ 949 ESP_d037_wssRROutOfRange "DTC_VALUES";
BA_ "FieldType" SG_ 949 ESP_d038_wssRRSignalMissing "DTC_VALUES";
BA_ "FieldType" SG_ 949 ESP_d039_wssRRWrongSen "DTC_VALUES";
BA_ "FieldType" SG_ 949 ESP_d040_wssRRPlausibility "DTC_VALUES";
BA_ "FieldType" SG_ 949 ESP_d041_wssMonWheelDirRR "DTC_VALUES";
BA_ "FieldType" SG_ 949 ESP_d042_wssRRAirGap "DTC_VALUES";
BA_ "FieldType" SG_ 949 ESP_d043_wssRRSupGnd "DTC_VALUES";
BA_ "FieldType" SG_ 949 ESP_d044_wssTstRRFld "DTC_VALUES";
BA_ "FieldType" SG_ 949 ESP_d045_wssGeneralFault "DTC_VALUES";
BA_ "FieldType" SG_ 949 ESP_d046_brakeSwitchStuckHigh "DTC_VALUES";
BA_ "FieldType" SG_ 949 ESP_d047_blsStatusInvd "DTC_VALUES";
BA_ "FieldType" SG_ 949 ESP_d048_brakeSwitchPlausib "DTC_VALUES";
BA_ "FieldType" SG_ 949 ESP_d049_pressSenMc1Line "DTC_VALUES";
BA_ "FieldType" SG_ 949 ESP_d050_acmPsOfstMc1 "DTC_VALUES";
BA_ "FieldType" SG_ 949 ESP_d051_acmPsTstpulseMc1 "DTC_VALUES";
BA_ "FieldType" SG_ 949 ESP_d052_comSclLowBrakeFluid "DTC_VALUES";
BA_ "FieldType" SG_ 949 ESP_d053_sasMonConstSig "DTC_VALUES";
BA_ "FieldType" SG_ 949 ESP_d054_sasMonOfst "DTC_VALUES";
BA_ "FieldType" SG_ 949 ESP_d055_sasPlausibility "DTC_VALUES";
BA_ "FieldType" SG_ 949 ESP_d056_aySensorFault "DTC_VALUES";
BA_ "FieldType" SG_ 949 ESP_d057_aysMonRange "DTC_VALUES";
BA_ "FieldType" SG_ 949 ESP_d058_aysOffset "DTC_VALUES";
BA_ "FieldType" SG_ 949 ESP_d059_aysPlaus "DTC_VALUES";
BA_ "FieldType" SG_ 949 ESP_d060_axSensorFault "DTC_VALUES";
BA_ "FieldType" SG_ 949 ESP_d061_axsMonRange "DTC_VALUES";
BA_ "FieldType" SG_ 949 ESP_d062_axOffsTooLarge "DTC_VALUES";
BA_ "FieldType" SG_ 949 ESP_d063_axSensorPlaus "DTC_VALUES";
BA_ "FieldType" SG_ 949 ESP_d064_yawSensorFault "DTC_VALUES";
BA_ "FieldType" SG_ 949 ESP_d065_yawSensorPlaus "DTC_VALUES";
BA_ "FieldType" SG_ 949 ESP_d066_absVdcContControl "DTC_VALUES";
BA_ "FieldType" SG_ 949 ESP_d067_undervoltage "DTC_VALUES";
BA_ "FieldType" SG_ 949 ESP_d068_overvoltage "DTC_VALUES";
BA_ "FieldType" SG_ 949 ESP_d069_memoryFault "DTC_VALUES";
BA_ "FieldType" SG_ 949 ESP_d070_ecuInternalGeneric "DTC_VALUES";
BA_ "FieldType" SG_ 949 ESP_d071_ecuInternalEcu "DTC_VALUES";
BA_ "FieldType" SG_ 949 ESP_d072_valveGeneric "DTC_VALUES";
BA_ "FieldType" SG_ 949 ESP_d073_valveAvFaults "DTC_VALUES";
BA_ "FieldType" SG_ 949 ESP_d074_valveEvFaults "DTC_VALUES";
BA_ "FieldType" SG_ 949 ESP_d075_valveHsvFaults "DTC_VALUES";
BA_ "FieldType" SG_ 949 ESP_d076_valveUsvFaults "DTC_VALUES";
BA_ "FieldType" SG_ 949 ESP_d077_refNotInitInTime "DTC_VALUES";
BA_ "FieldType" SG_ 949 ESP_d078_acmBtmOheatBraking "DTC_VALUES";
BA_ "FieldType" SG_ 949 ESP_d079_varCodeEeprom "DTC_VALUES";
BA_ "FieldType" SG_ 949 ESP_d080_reverseGearPlaus "DTC_VALUES";
BA_ "FieldType" SG_ 949 ESP_d081_comSclVinAllZeroFF "DTC_VALUES";
BA_ "FieldType" SG_ 949 ESP_d082_comSclVip405HsImpVin "DTC_VALUES";
BA_ "FieldType" SG_ 949 ESP_d083_comSclVip405HsDtCrpt "DTC_VALUES";
BA_ "FieldType" SG_ 949 ESP_d084_comSclVip405HsTout "DTC_VALUES";
BA_ "FieldType" SG_ 949 ESP_d085_rollerBenchActv "DTC_VALUES";
BA_ "FieldType" SG_ 949 ESP_d086_network0 "DTC_VALUES";
BA_ "FieldType" SG_ 949 ESP_d087_network1 "DTC_VALUES";
BA_ "FieldType" SG_ 949 ESP_d088_comMotorTOut "DTC_VALUES";
BA_ "FieldType" SG_ 949 ESP_d089_comDrsTxTOut "DTC_VALUES";
BA_ "FieldType" SG_ 949 ESP_d090_comSclStwAnglhpTout "DTC_VALUES";
BA_ "FieldType" SG_ 949 ESP_d091_comSclEpbStatusTout "DTC_VALUES";
BA_ "FieldType" SG_ 949 ESP_d092_comIbEsptTOut "DTC_VALUES";
BA_ "FieldType" SG_ 949 ESP_d093_comSclBdyStatusTout "DTC_VALUES";
BA_ "FieldType" SG_ 949 ESP_d094_comSclGtwEsp1Tout "DTC_VALUES";
BA_ "FieldType" SG_ 949 ESP_d095_comSclGtwOdoTout "DTC_VALUES";
BA_ "FieldType" SG_ 949 ESP_d096_comSclGtwCarCfgTout "DTC_VALUES";
BA_ "FieldType" SG_ 949 ESP_d097_comMotorCrpt "DTC_VALUES";
BA_ "FieldType" SG_ 949 ESP_d098_comMotorMsgCount "DTC_VALUES";
BA_ "FieldType" SG_ 949 ESP_d099_comMotorInvalidSig "DTC_VALUES";
BA_ "FieldType" SG_ 949 ESP_d100_comSclEpbStatusCrpt "DTC_VALUES";
BA_ "FieldType" SG_ 949 ESP_d101_comIbEspCrpt "DTC_VALUES";
BA_ "FieldType" SG_ 949 ESP_d102_comIbEspMsgCount "DTC_VALUES";
BA_ "FieldType" SG_ 949 ESP_d103_sclIbEspInvalidSig "DTC_VALUES";
BA_ "FieldType" SG_ 949 ESP_d104_comSclBdyStatusCrpt "DTC_VALUES";
BA_ "FieldType" SG_ 949 ESP_d105_comStwAnglHpCrpt "DTC_VALUES";
BA_ "FieldType" SG_ 949 ESP_d106_comStwAnglHpMsgCount "DTC_VALUES";
BA_ "FieldType" SG_ 949 ESP_d107_comSasInvalidSig "DTC_VALUES";
BA_ "FieldType" SG_ 949 ESP_d108_comDrsTxCrpt "DTC_VALUES";
BA_ "FieldType" SG_ 949 ESP_d109_sclMm3InvalidSig "DTC_VALUES";
BA_ "FieldType" SG_ 949 ESP_d110_comGtwEsp1Crpt "DTC_VALUES";
BA_ "FieldType" SG_ 949 ESP_d111_comSclGtwEsp1CntFlt "DTC_VALUES";
BA_ "FieldType" SG_ 949 ESP_d112_comSclGtwOdoDtCrpt "DTC_VALUES";
BA_ "FieldType" SG_ 949 ESP_d113_comSclGtwCrCfgDtCrpt "DTC_VALUES";
BA_ "FieldType" SG_ 949 ESP_d114_teslaChassisTypeSna "DTC_VALUES";
BA_ "FieldType" SG_ 949 ESP_d115_varPlatCalMismtch "DTC_VALUES";
BA_ "FieldType" SG_ 949 ESP_d116_ptsBlsStatusInvd "DTC_VALUES";
BA_ "FieldType" SG_ 949 ESP_d117_comSclBdwReqInvalid "DTC_VALUES";
BA_ "FieldType" SG_ 949 ESP_d118_rcmInvalidAx "DTC_VALUES";
BA_ "FieldType" SG_ 949 ESP_d119_rcmInvalidAy "DTC_VALUES";
BA_ "FieldType" SG_ 949 ESP_d120_rcmInvalidYaw "DTC_VALUES";
BA_ "FieldType" SG_ 949 ESP_d121_rcmInvalidFrame1 "DTC_VALUES";
BA_ "FieldType" SG_ 949 ESP_d122_rcmInvalidFrame2 "DTC_VALUES";
BA_ "FieldType" SG_ 949 ESP_d123_rcmLostComm "DTC_VALUES";
BA_ "FieldType" SG_ 949 ESP_d124_rcmIncompleteSensInfo "DTC_VALUES";
BA_ "FieldType" SG_ 949 ESP_d125_rcmSerialNumMismatch "DTC_VALUES";
BA_ "FieldType" SG_ 949 ESP_d126_rcmWrongSensorConfig "DTC_VALUES";
BA_ "FieldType" SG_ 949 ESP_d127_rcmInvalidCalibration "DTC_VALUES";
BA_ "FieldType" SG_ 949 ESP_d128_comSclPmState2TOut "DTC_VALUES";
BA_ "FieldType" SG_ 949 ESP_d129_sclBdwReqActiveInvd "DTC_VALUES";
BA_ "FieldType" SG_ 949 ESP_d130_comPmState2Crpt "DTC_VALUES";
BA_ "FieldType" SG_ 949 ESP_d131_comSclPmState2CntFlt "DTC_VALUES";
BA_ "FieldType" SG_ 949 ESP_d132_sclPmEbrCmdStateInvd "DTC_VALUES";
BA_ "FieldType" SG_ 949 ESP_d133_acmVsSignalPlaus "DTC_VALUES";
BA_ "FieldType" SG_ 949 ESP_d134_sasMonRange "DTC_VALUES";
BA_ "FieldType" SG_ 949 ESP_d135_sasMonGrad "DTC_VALUES";
BA_ "FieldType" SG_ 949 ESP_d136_yrsSignalOutOfRange "DTC_VALUES";
BA_ "FieldType" SG_ 949 ESP_d137_yrsMonGrad "DTC_VALUES";
BA_ "FieldType" SG_ 949 ESP_d138_yrsOffsetTooLarge "DTC_VALUES";
BA_ "FieldType" SG_ 949 ESP_d139_evpSigPlausibility "DTC_VALUES";
BA_ "FieldType" SG_ 949 ESP_d140_evpVacSigLow "DTC_VALUES";
BA_ "FieldType" SG_ 949 ESP_d141_vacSensorElectFail "DTC_VALUES";
BA_ "FieldType" SG_ 949 ESP_d142_canCommGeneral "DTC_VALUES";
BA_ "FieldType" SG_ 949 ESP_d143_mcuChassisContrDtCrpt "DTC_VALUES";
BA_ "FieldType" SG_ 949 ESP_d144_mcuChassisContrTout "DTC_VALUES";
BA_ "GenSigSNA" SG_ 533 ESP_brakeTorqueTarget2 "8191";
BA_ "GenSigStartValue" SG_ 805 ESP_applicationCrc 4294967295;
BA_ "GenSigStartValue" SG_ 805 ESP_vehicleVariant 255;
BA_ "GenSigStartValue" SG_ 805 ESP_variantCrc 4294967295;
BA_ "GenSigSNA" SG_ 901 ESP_latAccelOffsetComp "255";
BA_ "GenSigStartValue" SG_ 901 ESP_latAccelOffsetComp 112.5;
BA_ "GenSigSNA" SG_ 901 ESP_longAccelOffsetComp "255";
BA_ "GenSigStartValue" SG_ 901 ESP_longAccelOffsetComp 112.5;
BA_ "GenSigSNA" SG_ 901 ESP_yawrateOffsetComp "511";
BA_ "GenSigStartValue" SG_ 901 ESP_yawrateOffsetComp 245.76;
BA_ "GenSigSNA" SG_ 901 ESP_masterCylOffsetComp "127";
BA_ "GenSigStartValue" SG_ 901 ESP_masterCylOffsetComp 64;
BA_ "GenSigSNA" SG_ 285 ESP_wheelSlipFrL "1023";
BA_ "GenSigSNA" SG_ 285 ESP_wheelSlipFrR "1023";
BA_ "GenSigSNA" SG_ 285 ESP_wheelSlipReL "1023";
BA_ "GenSigSNA" SG_ 285 ESP_wheelSlipReR "1023";
BA_ "FieldType" SG_ 285 ESP_vdcActuatorState "ESP_vdcActuatorState";
BA_ "FieldType" SG_ 285 ESP_wheelSaturationFrL "ESP_wheelSaturation";
BA_ "FieldType" SG_ 285 ESP_wheelSaturationFrR "ESP_wheelSaturation";
BA_ "FieldType" SG_ 285 ESP_wheelSaturationReL "ESP_wheelSaturation";
BA_ "FieldType" SG_ 285 ESP_wheelSaturationReR "ESP_wheelSaturation";
BA_ "GenSigSNA" SG_ 373 ESP_wheelSpeedFrL_HS "8191";
BA_ "GenSigSNA" SG_ 373 ESP_wheelSpeedFrR_HS "8191";
BA_ "GenSigSNA" SG_ 373 ESP_wheelSpeedReL_HS "8191";
BA_ "GenSigSNA" SG_ 373 ESP_wheelSpeedReR_HS "8191";
BA_ "GenSigSendType" SG_ 520 GTW_ESP1Counter 11;
BA_ "GenSigStartValue" SG_ 520 GTW_hillStartAssistDisabled 1;
BA_ "GenSigSNA" SG_ 520 GTW_brakeDiscWipeRequest "3";
BA_ "FlexKomComment" SG_ 520 GTW_brakeFluidLow "Low brake fluid warning";
BA_ "FlexKomIsMotorola" SG_ 520 GTW_brakeFluidLow 1;
BA_ "FlexKomSID" SG_ 520 GTW_brakeFluidLow 33557542;
BA_ "FlexKomSigLaenge" SG_ 520 GTW_brakeFluidLow 1;
BA_ "FlexKomSigStartPos" SG_ 520 GTW_brakeFluidLow 15;
BA_ "FlexKomSigStartValue" SG_ 520 GTW_brakeFluidLow "00h";
BA_ "GenSigCycleTime" SG_ 520 GTW_brakeFluidLow 20;
BA_ "FlexKomComment" SG_ 520 GTW_ambientTemperature "Ambient temperature (unfiltered value)";
BA_ "FlexKomIsMotorola" SG_ 520 GTW_ambientTemperature 1;
BA_ "FlexKomSID" SG_ 520 GTW_ambientTemperature 33557534;
BA_ "FlexKomSigLaenge" SG_ 520 GTW_ambientTemperature 8;
BA_ "FlexKomSigStartPos" SG_ 520 GTW_ambientTemperature 23;
BA_ "FlexKomSigStartValue" SG_ 520 GTW_ambientTemperature "FFh";
BA_ "GenSigCycleTime" SG_ 520 GTW_ambientTemperature 100;
BA_ "GenSigSNA" SG_ 520 GTW_ambientTemperature "255";
BA_ "GenSigStartValue" SG_ 520 GTW_ambientTemperature 255;
BA_ "GenSigSNA" SG_ 520 GTW_pedalCalTargetCurve "6";
BA_ "GenSigSNA" SG_ 520 GTW_espModeSwitch "2";
BA_ "GenSigSNA" SG_ 552 GTW_airbagCutOffSwState "2";
BA_ "LogSignal" SG_ 552 GTW_airbagCutOffSwState "onChange";
BA_ "GenSigSNA" SG_ 552 GTW_warningIndicatorStatus "3";
BA_ "GenSigSNA" SG_ 920 GTW_performanceConfig "0";
BA_ "GenSigSNA" SG_ 920 GTW_fourWheelDrive "3";
BA_ "GenSigStartValue" SG_ 920 GTW_country 21843;
BA_ "GenSigSNA" SG_ 920 GTW_wheelType "31";
BA_ "GenSigStartValue" SG_ 920 GTW_wheelType 31;
BA_ "GenSigCycleTime" SG_ 792 YEAR 100;
BA_ "GenSigCycleTimeActive" SG_ 792 YEAR 100;
BA_ "GenSigSNA" SG_ 792 YEAR "127";
BA_ "GenSigStartValue" SG_ 792 YEAR 126;
BA_ "GenSigCycleTime" SG_ 792 CERRD 100;
BA_ "GenSigCycleTimeActive" SG_ 792 CERRD 100;
BA_ "GenSigStartValue" SG_ 792 CERRD 1;
BA_ "GenSigCycleTime" SG_ 792 MONTH 100;
BA_ "GenSigCycleTimeActive" SG_ 792 MONTH 100;
BA_ "GenSigSNA" SG_ 792 MONTH "15";
BA_ "GenSigStartValue" SG_ 792 MONTH 1;
BA_ "GenSigCycleTime" SG_ 792 DOOR_STATE_FL 100;
BA_ "GenSigCycleTimeActive" SG_ 792 DOOR_STATE_FL 100;
BA_ "GenSigSNA" SG_ 792 DOOR_STATE_FL "3";
BA_ "GenSigCycleTime" SG_ 792 DOOR_STATE_FR 100;
BA_ "GenSigCycleTimeActive" SG_ 792 DOOR_STATE_FR 100;
BA_ "GenSigSNA" SG_ 792 DOOR_STATE_FR "3";
BA_ "GenSigCycleTime" SG_ 792 SECOND 100;
BA_ "GenSigCycleTimeActive" SG_ 792 SECOND 100;
BA_ "GenSigSNA" SG_ 792 SECOND "63";
BA_ "GenSigStartValue" SG_ 792 SECOND 62;
BA_ "GenSigCycleTime" SG_ 792 DOOR_STATE_RL 100;
BA_ "GenSigCycleTimeActive" SG_ 792 DOOR_STATE_RL 100;
BA_ "GenSigSNA" SG_ 792 DOOR_STATE_RL "3";
BA_ "GenSigCycleTime" SG_ 792 Hour 100;
BA_ "GenSigCycleTimeActive" SG_ 792 Hour 100;
BA_ "GenSigSNA" SG_ 792 Hour "31";
BA_ "GenSigStartValue" SG_ 792 Hour 30;
BA_ "GenSigCycleTime" SG_ 792 DOOR_STATE_RR 100;
BA_ "GenSigCycleTimeActive" SG_ 792 DOOR_STATE_RR 100;
BA_ "GenSigSNA" SG_ 792 DOOR_STATE_RR "3";
BA_ "GenSigCycleTime" SG_ 792 DAY 100;
BA_ "GenSigCycleTimeActive" SG_ 792 DAY 100;
BA_ "GenSigSNA" SG_ 792 DAY "0";
BA_ "GenSigStartValue" SG_ 792 DAY 1;
BA_ "GenSigSendType" SG_ 792 BC_courtesyLightingActive 2;
BA_ "GenSigStartValue" SG_ 792 BC_courtesyLightingActive 3;
BA_ "GenSigCycleTime" SG_ 792 MINUTE 100;
BA_ "GenSigCycleTimeActive" SG_ 792 MINUTE 100;
BA_ "GenSigSNA" SG_ 792 MINUTE "63";
BA_ "GenSigStartValue" SG_ 792 MINUTE 62;
BA_ "GenSigCycleTime" SG_ 792 BOOT_STATE 100;
BA_ "GenSigCycleTimeActive" SG_ 792 BOOT_STATE 100;
BA_ "GenSigSNA" SG_ 792 BOOT_STATE "3";
BA_ "FieldType" SG_ 792 GTW_updateInProgress "GTW_updateInProgress";
BA_ "GenSigCycleTime" SG_ 792 GTW_updateInProgress 100;
BA_ "GenSigCycleTimeActive" SG_ 792 GTW_updateInProgress 100;
BA_ "GenSigSNA" SG_ 792 GTW_updateInProgress "3";
BA_ "GenSigCycleTime" SG_ 792 DOOR_STATE_FrontTrunk 100;
BA_ "GenSigCycleTimeActive" SG_ 792 DOOR_STATE_FrontTrunk 100;
BA_ "GenSigSNA" SG_ 792 DOOR_STATE_FrontTrunk "3";
BA_ "GenSigStartValue" SG_ 792 BC_headLightLStatus 3;
BA_ "GenSigStartValue" SG_ 792 BC_headLightRStatus 3;
BA_ "GenSigStartValue" SG_ 792 BC_indicatorLStatus 3;
BA_ "GenSigStartValue" SG_ 792 BC_indicatorRStatus 3;
BA_ "LogSignal" SG_ 1048 GTW_chGotoSleep "onChange";
BA_ "GenSigCycleTime" SG_ 296 REV_GEAR 100;
BA_ "GenSigCycleTimeActive" SG_ 296 REV_GEAR 100;
BA_ "GenSigSNA" SG_ 296 REV_GEAR "3";
BA_ "GenSigCycleTime" SG_ 296 GTW_diagDriveState 100;
BA_ "GenSigCycleTimeActive" SG_ 296 GTW_diagDriveState 100;
BA_ "GenSigSNA" SG_ 296 GTW_diagDriveState "0";
BA_ "GenSigCycleTime" SG_ 296 ENG_RPM 100;
BA_ "GenSigCycleTimeActive" SG_ 296 ENG_RPM 100;
BA_ "GenSigSNA" SG_ 296 ENG_RPM "65535";
BA_ "GenSigSNA" SG_ 257 GTW_epasPowerMode "15";
BA_ "LogSignal" SG_ 257 GTW_epasPowerMode "onChange";
BA_ "LogSignal" SG_ 257 GTW_epasControlType "onChange";
BA_ "GenSigSendType" SG_ 1281 EPAS_destinationAddress 7;
BA_ "GenSigStartValue" SG_ 1281 EPAS_destinationAddress 63;
BA_ "GenSigSendType" SG_ 1281 EPAS_controlField 7;
BA_ "GenSigStartValue" SG_ 1281 EPAS_controlField 2;
BA_ "GenSigStartValue" SG_ 1368 GTW_appGitHash0 255;
BA_ "GenSigStartValue" SG_ 1368 GTW_appGitHash1 255;
BA_ "GenSigStartValue" SG_ 1368 GTW_appGitHash2 255;
BA_ "GenSigStartValue" SG_ 1368 GTW_appGitHash3 255;
BA_ "GenSigStartValue" SG_ 1368 GTW_appGitHash4 255;
BA_ "GenSigStartValue" SG_ 1368 GTW_appGitHash5 255;
BA_ "GenSigStartValue" SG_ 1368 GTW_appGitHash6 255;
BA_ "GenSigStartValue" SG_ 1368 GTW_appGitHash7 255;
BA_ "GenSigSNA" SG_ 888 GTW_ibsVoltage "65535";
BA_ "LogSignal" SG_ 776 GTW_easManualLevelRequest "onChange";
BA_ "GenSigCycleTime" SG_ 776 HVBatteryLow 100;
BA_ "GenSigCycleTimeActive" SG_ 776 HVBatteryLow 100;
BA_ "LogSignal" SG_ 776 HVBatteryLow "onChange";
BA_ "GenSigCycleTime" SG_ 776 GTW_espPlatCalMismatch 100;
BA_ "GenSigCycleTimeActive" SG_ 776 GTW_espPlatCalMismatch 100;
BA_ "GenSigCycleTime" SG_ 776 GTW_ibstConnectivityDisable 100;
BA_ "GenSigCycleTimeActive" SG_ 776 GTW_ibstConnectivityDisable 100;
BA_ "GenSigCycleTime" SG_ 776 AMB_TEMP 100;
BA_ "GenSigCycleTimeActive" SG_ 776 AMB_TEMP 100;
BA_ "GenSigSNA" SG_ 776 AMB_TEMP "255";
BA_ "GenSigStartValue" SG_ 776 AMB_TEMP 255;
BA_ "GenSigCycleTime" SG_ 776 GTW_ODO 100;
BA_ "GenSigCycleTimeActive" SG_ 776 GTW_ODO 100;
BA_ "GenSigSNA" SG_ 776 GTW_ODO "16777215";
BA_ "GenSigSNA" SG_ 776 DI_tireFitment "3";
BA_ "GenSigSNA" SG_ 776 DI_steerCenter "-128";
BA_ "GenSigSNA" SG_ 936 MCU_requestBusWake "3";
BA_ "GenSigStartValue" SG_ 936 MCU_requestBusWake 3;
BA_ "GenSigSNA" SG_ 936 GTW_willBeGoingToSleep "3";
BA_ "GenSigStartValue" SG_ 936 GTW_willBeGoingToSleep 3;
BA_ "FieldType" SG_ 936 GTW_clusterState "GTW_clusterState";
BA_ "GenSigSNA" SG_ 936 MCU_clusterInstantOn "0";
BA_ "GenSigSNA" SG_ 936 MCU_gatewaySleepReq "7";
BA_ "GenSigStartValue" SG_ 936 MCU_gatewaySleepReq 7;
BA_ "GenSigSNA" SG_ 936 MCU_updaterSleepDelay "0";
BA_ "GenSigSNA" SG_ 1880 GTW_deepSleepMinutes "16383";
BA_ "GenSigStartValue" SG_ 1880 GTW_deepSleepMinutes 16383;
BA_ "LogSignal" SG_ 840 GTW_brakePressed "onChange";
BA_ "LogSignal" SG_ 840 GTW_icPowerOff "onChange";
BA_ "GenSigStartValue" SG_ 840 GTW_mcuOff 1;
BA_ "GenSigSNA" SG_ 840 DOOR_STATE_RearTrunk "3";
VAL_ 325 ESP_longitudinalAccel 1023 "SNA" ;
VAL_ 325 ESP_stabilityControlSts2 7 "SNA" 5 "INIT" 4 "NOT_CONFIGURED" 3 "FAULTED" 2 "ENGAGED" 1 "ON" 0 "OFF" ;
VAL_ 325 ESP_brakeMasterCylPressQF 1 "IN_SPEC" 0 "UNDEFINABLE_ACCURACY" ;
VAL_ 325 ESP_absBrakeEvent2 3 "ABS_EVENT_ACTIVE_REAR" 2 "ABS_EVENT_ACTIVE_FRONT" 1 "ABS_EVENT_ACTIVE_FRONT_REAR" 0 "ABS_EVENT_NOT_ACTIVE" ;
VAL_ 325 ESP_lateralAccel 1023 "SNA" ;
VAL_ 325 ESP_btcTargetState 3 "SNA" 2 "ON" 1 "BACKUP" 0 "OFF" ;
VAL_ 325 ESP_ptcTargetState 3 "SNA" 2 "ON" 1 "BACKUP" 0 "FAULT" ;
VAL_ 325 ESP_vehicleStandstillSts 1 "Standstill" 0 "Not_Standstill" ;
VAL_ 325 ESP_brakeMasterCylPress 1023 "PRESSURE_SNA" ;
VAL_ 325 ESP_wheelSpeedsQF 1 "ALL_WSS_VALID" 0 "ONE_OR_MORE_WSS_INVALID" ;
VAL_ 325 ESP_espModeActive 3 "ESP_DEV_MODE_2" 2 "ESP_DEV_MODE_1" 1 "MODE_01_TC_OFF" 0 "MODE_00_NORMAL" ;
VAL_ 325 ESP_lateralAccelQF 3 "IN_SPEC" 2 "NOT_WITHIN_SPECIFICATION" 1 "EVAL_IN_PROGRESS" 0 "UNDEFINABLE_ACCURACY" ;
VAL_ 325 ESP_longitudinalAccelQF 3 "IN_SPEC" 2 "NOT_WITHIN_SPECIFICATION" 1 "EVAL_IN_PROGRESS" 0 "UNDEFINABLE_ACCURACY" ;
VAL_ 341 ESP_wheelPulseCountFrL 255 "SNA" ;
VAL_ 341 ESP_wheelPulseCountFrR 255 "SNA" ;
VAL_ 341 ESP_wheelPulseCountReL 255 "SNA" ;
VAL_ 341 ESP_wheelPulseCountReR 255 "SNA" ;
VAL_ 341 ESP_vehicleSpeedQF 3 "IN_SPEC" 0 "UNDEFINABLE_ACCURACY_SNA" ;
VAL_ 341 ESP_BCounter 0 "COUNT_0" ;
VAL_ 522 ESP_YawRate_LR 1023 "Error_Marker" 1022 "Invalid_Undefined_0x3FE" 1021 "Invalid_Undefined_0x3FD" 1020 "Invalid_Undefined_0x3FC" 1019 "Invalid_Undefined_0x3FB" 1018 "Invalid_Undefined_0x3FA" 1017 "Invalid_Undefined_0x3F9" 1016 "Invalid_Undefined_0x3F8" 1015 "Invalid_Undefined_0x3F7" 1014 "Invalid_Undefined_0x3F6" 1013 "Invalid_Undefined_0x3F5" 1012 "Invalid_Undefined_0x3F4" 1011 "Invalid_Undefined_0x3F3" 1010 "Invalid_Undefined_0x3F2" 1009 "Invalid_Undefined_0x3F1" 1008 "Invalid_Undefined_0x3F0" 1007 "Invalid_Undefined_0x3EF" 1006 "Invalid_Undefined_0x3EE" 1005 "Invalid_Undefined_0x3ED" 1004 "Invalid_Undefined_0x3EC" 1003 "Invalid_Undefined_0x3EB" 1002 "Invalid_Undefined_0x3EA" 1001 "Invalid_Undefined_0x3E9" ;
VAL_ 522 ESP_driverBrakeApply 3 "Faulty_SNA" 2 "Driver_applying_brakes" 1 "Not_Applied" 0 "NotInit_orOff" ;
VAL_ 522 ESP_WheelRotationFrR 3 "WR_NOT_DEFINABLE" 2 "WR_STANDSTILL" 1 "WR_BACKWARD" 0 "WR_FORWARD" ;
VAL_ 522 ESP_WheelRotationFrL 3 "WR_NOT_DEFINABLE" 2 "WR_STANDSTILL" 1 "WR_BACKWARD" 0 "WR_FORWARD" ;
VAL_ 522 ESP_WheelRotationReR 3 "WR_NOT_DEFINABLE" 2 "WR_STANDSTILL" 1 "WR_BACKWARD" 0 "WR_FORWARD" ;
VAL_ 522 ESP_WheelRotationReL 3 "WR_NOT_DEFINABLE" 2 "WR_STANDSTILL" 1 "WR_BACKWARD" 0 "WR_FORWARD" ;
VAL_ 522 ESP_YawRateQF_LR 3 "IN_SPEC" 2 "NOT_WITHIN_SPECIFICATION" 1 "EVAL_IN_PROGRESS" 0 "UNDEFINABLE_ACCURACY" ;
VAL_ 522 ESP_blsActive 1 "BLS_ACTIVE" 0 "BLS_INACTIVE" ;
VAL_ 522 ESP_parkBrakeRequest 1 "ESP_REQUEST_PARK_BRAKE" 0 "ESP_NO_EPB_REQUEST" ;
VAL_ 522 ESP_yawRate 4095 "SNA" ;
VAL_ 522 ESP_brakeCommandResponse 7 "SNA" 6 "STANDSTILL_MANAGEMENT" 3 "PARK" 2 "AEB" 1 "ACC" 0 "No_Request" ;
VAL_ 522 ESP_brakeTorqueTarget 8191 "SNA" ;
VAL_ 1285 ESP_alertID 16528 "ESP_d144_mcuChassisContrTout" 16527 "ESP_d143_mcuChassisContrDtCrpt" 16526 "ESP_d142_canCommGeneral" 16525 "ESP_d141_vacSensorElectFail" 16524 "ESP_d140_evpVacSigLow" 16523 "ESP_d139_evpSigPlausibility" 16522 "ESP_d138_yrsOffsetTooLarge" 16521 "ESP_d137_yrsMonGrad" 16520 "ESP_d136_yrsSignalOutOfRange" 16519 "ESP_d135_sasMonGrad" 16518 "ESP_d134_sasMonRange" 16517 "ESP_d133_acmVsSignalPlaus" 16516 "ESP_d132_sclPmEbrCmdStateInvd" 16515 "ESP_d131_comSclPmState2CntFlt" 16514 "ESP_d130_comPmState2Crpt" 16513 "ESP_d129_sclBdwReqActiveInvd" 16512 "ESP_d128_comSclPmState2TOut" 16511 "ESP_d127_rcmInvalidCalibration" 16510 "ESP_d126_rcmWrongSensorConfig" 16509 "ESP_d125_rcmSerialNumMismatch" 16508 "ESP_d124_rcmIncompleteSensInfo" 16507 "ESP_d123_rcmLostComm" 16506 "ESP_d122_rcmInvalidFrame2" 16505 "ESP_d121_rcmInvalidFrame1" 16504 "ESP_d120_rcmInvalidYaw" 16503 "ESP_d119_rcmInvalidAy" 16502 "ESP_d118_rcmInvalidAx" 16501 "ESP_d117_comSclBdwReqInvalid" 16500 "ESP_d116_ptsBlsStatusInvd" 16499 "ESP_d115_varPlatCalMismtch" 16498 "ESP_d114_teslaChassisTypeSna" 16497 "ESP_d113_comSclGtwCrCfgDtCrpt" 16496 "ESP_d112_comSclGtwOdoDtCrpt" 16495 "ESP_d111_comSclGtwEsp1CntFlt" 16494 "ESP_d110_comGtwEsp1Crpt" 16493 "ESP_d109_sclMm3InvalidSig" 16492 "ESP_d108_comDrsTxCrpt" 16491 "ESP_d107_comSasInvalidSig" 16490 "ESP_d106_comStwAnglHpMsgCount" 16489 "ESP_d105_comStwAnglHpCrpt" 16488 "ESP_d104_comSclBdyStatusCrpt" 16487 "ESP_d103_sclIbEspInvalidSig" 16486 "ESP_d102_comIbEspMsgCount" 16485 "ESP_d101_comIbEspCrpt" 16484 "ESP_d100_comSclEpbStatusCrpt" 16483 "ESP_d099_comMotorInvalidSig" 16482 "ESP_d098_comMotorMsgCount" 16481 "ESP_d097_comMotorCrpt" 16480 "ESP_d096_comSclGtwCarCfgTout" 16479 "ESP_d095_comSclGtwOdoTout" 16478 "ESP_d094_comSclGtwEsp1Tout" 16477 "ESP_d093_comSclBdyStatusTout" 16476 "ESP_d092_comIbEsptTOut" 16475 "ESP_d091_comSclEpbStatusTout" 16474 "ESP_d090_comSclStwAnglhpTout" 16473 "ESP_d089_comDrsTxTOut" 16472 "ESP_d088_comMotorTOut" 16471 "ESP_d087_network1" 16470 "ESP_d086_network0" 16469 "ESP_d085_rollerBenchActv" 16468 "ESP_d084_comSclVip405HsTout" 16467 "ESP_d083_comSclVip405HsDtCrpt" 16466 "ESP_d082_comSclVip405HsImpVin" 16465 "ESP_d081_comSclVinAllZeroFF" 16464 "ESP_d080_reverseGearPlaus" 16463 "ESP_d079_varCodeEeprom" 16462 "ESP_d078_acmBtmOheatBraking" 16461 "ESP_d077_refNotInitInTime" 16460 "ESP_d076_valveUsvFaults" 16459 "ESP_d075_valveHsvFaults" 16458 "ESP_d074_valveEvFaults" 16457 "ESP_d073_valveAvFaults" 16456 "ESP_d072_valveGeneric" 16455 "ESP_d071_ecuInternalEcu" 16454 "ESP_d070_ecuInternalGeneric" 16453 "ESP_d069_memoryFault" 16452 "ESP_d068_overvoltage" 16451 "ESP_d067_undervoltage" 16450 "ESP_d066_absVdcContControl" 16449 "ESP_d065_yawSensorPlaus" 16448 "ESP_d064_yawSensorFault" 16447 "ESP_d063_axSensorPlaus" 16446 "ESP_d062_axOffsTooLarge" 16445 "ESP_d061_axsMonRange" 16444 "ESP_d060_axSensorFault" 16443 "ESP_d059_aysPlaus" 16442 "ESP_d058_aysOffset" 16441 "ESP_d057_aysMonRange" 16440 "ESP_d056_aySensorFault" 16439 "ESP_d055_sasPlausibility" 16438 "ESP_d054_sasMonOfst" 16437 "ESP_d053_sasMonConstSig" 16436 "ESP_d052_comSclLowBrakeFluid" 16435 "ESP_d051_acmPsTstpulseMc1" 16434 "ESP_d050_acmPsOfstMc1" 16433 "ESP_d049_pressSenMc1Line" 16432 "ESP_d048_brakeSwitchPlausib" 16431 "ESP_d047_blsStatusInvd" 16430 "ESP_d046_brakeSwitchStuckHigh" 16429 "ESP_d045_wssGeneralFault" 16428 "ESP_d044_wssTstRRFld" 16427 "ESP_d043_wssRRSupGnd" 16426 "ESP_d042_wssRRAirGap" 16425 "ESP_d041_wssMonWheelDirRR" 16424 "ESP_d040_wssRRPlausibility" 16423 "ESP_d039_wssRRWrongSen" 16422 "ESP_d038_wssRRSignalMissing" 16421 "ESP_d037_wssRROutOfRange" 16420 "ESP_d036_wssRRLineUndef" 16419 "ESP_d035_wssRRLineHigh" 16418 "ESP_d034_wssRRLineGnd" 16417 "ESP_d033_wssTstRLFld" 16416 "ESP_d032_wssRLSupGnd" 16415 "ESP_d031_wssRLAirGap" 16414 "ESP_d030_wssRAWrongMounting" 16413 "ESP_d029_wssRLPlausibility" 16412 "ESP_d028_wssRLWrongSen" 16411 "ESP_d027_wssRLSignalMissing" 16410 "ESP_d026_wssRLOutOfRange" 16409 "ESP_d025_wssRLLineUndef" 16408 "ESP_d024_wssRLLineHigh" 16407 "ESP_d023_wssRLLineGnd" 16406 "ESP_d022_wssTstFRFld" 16405 "ESP_d021_wssFRSupGnd" 16404 "ESP_d020_wssFRAirGap" 16403 "ESP_d019_wssMonWheelDirFR" 16402 "ESP_d018_wssFRPlausibility" 16401 "ESP_d017_wssFRWrongSen" 16400 "ESP_d016_wssFRSignalMissing" 16399 "ESP_d015_wssFROutOfRange" 16398 "ESP_d014_wssFRLineUndef" 16397 "ESP_d013_wssFRLineHigh" 16396 "ESP_d012_wssFRLineGnd" 16395 "ESP_d011_wssTstFLFld" 16394 "ESP_d010_wssFLSupGnd" 16393 "ESP_d009_wssFLAirGap" 16392 "ESP_d008_wssFAWrongMounting" 16391 "ESP_d007_wssFLPlausibility" 16390 "ESP_d006_wssFLWrongSen" 16389 "ESP_d005_wssFLSignalMissing" 16388 "ESP_d004_wssFLOutOfRange" 16387 "ESP_d003_wssFLLineUndef" 16386 "ESP_d002_wssFLLineHigh" 16385 "ESP_d001_wssFLLineGnd" 16384 "ESP_d000_absPumpMotorControl" ;
VAL_ 389 ESP_brakeTorqueFrL 4095 "SNA" ;
VAL_ 389 ESP_brakeTorqueFrR 4095 "SNA" ;
VAL_ 389 ESP_brakeTorqueReL 4095 "SNA" ;
VAL_ 389 ESP_brakeTorqueReR 4095 "SNA" ;
VAL_ 389 ESP_brakeTorqueQF 3 "IN_SPEC" 2 "NOT_WITHIN_SPECIFICATION" 1 "EVAL_IN_PROGRESS" 0 "UNDEFINABLE_ACCURACY" ;
VAL_ 949 ESP_d000_absPumpMotorControl 3 "UNABLE_TO_TEST_DTC" 2 "FAILED_DTC" 1 "PASSED_DTC" 0 "NOT_TESTED_DTC" ;
VAL_ 949 ESP_d001_wssFLLineGnd 3 "UNABLE_TO_TEST_DTC" 2 "FAILED_DTC" 1 "PASSED_DTC" 0 "NOT_TESTED_DTC" ;
VAL_ 949 ESP_d002_wssFLLineHigh 3 "UNABLE_TO_TEST_DTC" 2 "FAILED_DTC" 1 "PASSED_DTC" 0 "NOT_TESTED_DTC" ;
VAL_ 949 ESP_d003_wssFLLineUndef 3 "UNABLE_TO_TEST_DTC" 2 "FAILED_DTC" 1 "PASSED_DTC" 0 "NOT_TESTED_DTC" ;
VAL_ 949 ESP_d004_wssFLOutOfRange 3 "UNABLE_TO_TEST_DTC" 2 "FAILED_DTC" 1 "PASSED_DTC" 0 "NOT_TESTED_DTC" ;
VAL_ 949 ESP_d005_wssFLSignalMissing 3 "UNABLE_TO_TEST_DTC" 2 "FAILED_DTC" 1 "PASSED_DTC" 0 "NOT_TESTED_DTC" ;
VAL_ 949 ESP_d006_wssFLWrongSen 3 "UNABLE_TO_TEST_DTC" 2 "FAILED_DTC" 1 "PASSED_DTC" 0 "NOT_TESTED_DTC" ;
VAL_ 949 ESP_d007_wssFLPlausibility 3 "UNABLE_TO_TEST_DTC" 2 "FAILED_DTC" 1 "PASSED_DTC" 0 "NOT_TESTED_DTC" ;
VAL_ 949 ESP_d008_wssFAWrongMounting 3 "UNABLE_TO_TEST_DTC" 2 "FAILED_DTC" 1 "PASSED_DTC" 0 "NOT_TESTED_DTC" ;
VAL_ 949 ESP_d009_wssFLAirGap 3 "UNABLE_TO_TEST_DTC" 2 "FAILED_DTC" 1 "PASSED_DTC" 0 "NOT_TESTED_DTC" ;
VAL_ 949 ESP_d010_wssFLSupGnd 3 "UNABLE_TO_TEST_DTC" 2 "FAILED_DTC" 1 "PASSED_DTC" 0 "NOT_TESTED_DTC" ;
VAL_ 949 ESP_d011_wssTstFLFld 3 "UNABLE_TO_TEST_DTC" 2 "FAILED_DTC" 1 "PASSED_DTC" 0 "NOT_TESTED_DTC" ;
VAL_ 949 ESP_d012_wssFRLineGnd 3 "UNABLE_TO_TEST_DTC" 2 "FAILED_DTC" 1 "PASSED_DTC" 0 "NOT_TESTED_DTC" ;
VAL_ 949 ESP_d013_wssFRLineHigh 3 "UNABLE_TO_TEST_DTC" 2 "FAILED_DTC" 1 "PASSED_DTC" 0 "NOT_TESTED_DTC" ;
VAL_ 949 ESP_d014_wssFRLineUndef 3 "UNABLE_TO_TEST_DTC" 2 "FAILED_DTC" 1 "PASSED_DTC" 0 "NOT_TESTED_DTC" ;
VAL_ 949 ESP_d015_wssFROutOfRange 3 "UNABLE_TO_TEST_DTC" 2 "FAILED_DTC" 1 "PASSED_DTC" 0 "NOT_TESTED_DTC" ;
VAL_ 949 ESP_d016_wssFRSignalMissing 3 "UNABLE_TO_TEST_DTC" 2 "FAILED_DTC" 1 "PASSED_DTC" 0 "NOT_TESTED_DTC" ;
VAL_ 949 ESP_d017_wssFRWrongSen 3 "UNABLE_TO_TEST_DTC" 2 "FAILED_DTC" 1 "PASSED_DTC" 0 "NOT_TESTED_DTC" ;
VAL_ 949 ESP_d018_wssFRPlausibility 3 "UNABLE_TO_TEST_DTC" 2 "FAILED_DTC" 1 "PASSED_DTC" 0 "NOT_TESTED_DTC" ;
VAL_ 949 ESP_d019_wssMonWheelDirFR 3 "UNABLE_TO_TEST_DTC" 2 "FAILED_DTC" 1 "PASSED_DTC" 0 "NOT_TESTED_DTC" ;
VAL_ 949 ESP_d020_wssFRAirGap 3 "UNABLE_TO_TEST_DTC" 2 "FAILED_DTC" 1 "PASSED_DTC" 0 "NOT_TESTED_DTC" ;
VAL_ 949 ESP_d021_wssFRSupGnd 3 "UNABLE_TO_TEST_DTC" 2 "FAILED_DTC" 1 "PASSED_DTC" 0 "NOT_TESTED_DTC" ;
VAL_ 949 ESP_d022_wssTstFRFld 3 "UNABLE_TO_TEST_DTC" 2 "FAILED_DTC" 1 "PASSED_DTC" 0 "NOT_TESTED_DTC" ;
VAL_ 949 ESP_d023_wssRLLineGnd 3 "UNABLE_TO_TEST_DTC" 2 "FAILED_DTC" 1 "PASSED_DTC" 0 "NOT_TESTED_DTC" ;
VAL_ 949 ESP_d024_wssRLLineHigh 3 "UNABLE_TO_TEST_DTC" 2 "FAILED_DTC" 1 "PASSED_DTC" 0 "NOT_TESTED_DTC" ;
VAL_ 949 ESP_d025_wssRLLineUndef 3 "UNABLE_TO_TEST_DTC" 2 "FAILED_DTC" 1 "PASSED_DTC" 0 "NOT_TESTED_DTC" ;
VAL_ 949 ESP_d026_wssRLOutOfRange 3 "UNABLE_TO_TEST_DTC" 2 "FAILED_DTC" 1 "PASSED_DTC" 0 "NOT_TESTED_DTC" ;
VAL_ 949 ESP_d027_wssRLSignalMissing 3 "UNABLE_TO_TEST_DTC" 2 "FAILED_DTC" 1 "PASSED_DTC" 0 "NOT_TESTED_DTC" ;
VAL_ 949 ESP_d028_wssRLWrongSen 3 "UNABLE_TO_TEST_DTC" 2 "FAILED_DTC" 1 "PASSED_DTC" 0 "NOT_TESTED_DTC" ;
VAL_ 949 ESP_d029_wssRLPlausibility 3 "UNABLE_TO_TEST_DTC" 2 "FAILED_DTC" 1 "PASSED_DTC" 0 "NOT_TESTED_DTC" ;
VAL_ 949 ESP_d030_wssRAWrongMounting 3 "UNABLE_TO_TEST_DTC" 2 "FAILED_DTC" 1 "PASSED_DTC" 0 "NOT_TESTED_DTC" ;
VAL_ 949 ESP_d031_wssRLAirGap 3 "UNABLE_TO_TEST_DTC" 2 "FAILED_DTC" 1 "PASSED_DTC" 0 "NOT_TESTED_DTC" ;
VAL_ 949 ESP_d032_wssRLSupGnd 3 "UNABLE_TO_TEST_DTC" 2 "FAILED_DTC" 1 "PASSED_DTC" 0 "NOT_TESTED_DTC" ;
VAL_ 949 ESP_d033_wssTstRLFld 3 "UNABLE_TO_TEST_DTC" 2 "FAILED_DTC" 1 "PASSED_DTC" 0 "NOT_TESTED_DTC" ;
VAL_ 949 ESP_d034_wssRRLineGnd 3 "UNABLE_TO_TEST_DTC" 2 "FAILED_DTC" 1 "PASSED_DTC" 0 "NOT_TESTED_DTC" ;
VAL_ 949 ESP_d035_wssRRLineHigh 3 "UNABLE_TO_TEST_DTC" 2 "FAILED_DTC" 1 "PASSED_DTC" 0 "NOT_TESTED_DTC" ;
VAL_ 949 ESP_d036_wssRRLineUndef 3 "UNABLE_TO_TEST_DTC" 2 "FAILED_DTC" 1 "PASSED_DTC" 0 "NOT_TESTED_DTC" ;
VAL_ 949 ESP_d037_wssRROutOfRange 3 "UNABLE_TO_TEST_DTC" 2 "FAILED_DTC" 1 "PASSED_DTC" 0 "NOT_TESTED_DTC" ;
VAL_ 949 ESP_d038_wssRRSignalMissing 3 "UNABLE_TO_TEST_DTC" 2 "FAILED_DTC" 1 "PASSED_DTC" 0 "NOT_TESTED_DTC" ;
VAL_ 949 ESP_d039_wssRRWrongSen 3 "UNABLE_TO_TEST_DTC" 2 "FAILED_DTC" 1 "PASSED_DTC" 0 "NOT_TESTED_DTC" ;
VAL_ 949 ESP_d040_wssRRPlausibility 3 "UNABLE_TO_TEST_DTC" 2 "FAILED_DTC" 1 "PASSED_DTC" 0 "NOT_TESTED_DTC" ;
VAL_ 949 ESP_d041_wssMonWheelDirRR 3 "UNABLE_TO_TEST_DTC" 2 "FAILED_DTC" 1 "PASSED_DTC" 0 "NOT_TESTED_DTC" ;
VAL_ 949 ESP_d042_wssRRAirGap 3 "UNABLE_TO_TEST_DTC" 2 "FAILED_DTC" 1 "PASSED_DTC" 0 "NOT_TESTED_DTC" ;
VAL_ 949 ESP_d043_wssRRSupGnd 3 "UNABLE_TO_TEST_DTC" 2 "FAILED_DTC" 1 "PASSED_DTC" 0 "NOT_TESTED_DTC" ;
VAL_ 949 ESP_d044_wssTstRRFld 3 "UNABLE_TO_TEST_DTC" 2 "FAILED_DTC" 1 "PASSED_DTC" 0 "NOT_TESTED_DTC" ;
VAL_ 949 ESP_d045_wssGeneralFault 3 "UNABLE_TO_TEST_DTC" 2 "FAILED_DTC" 1 "PASSED_DTC" 0 "NOT_TESTED_DTC" ;
VAL_ 949 ESP_d046_brakeSwitchStuckHigh 3 "UNABLE_TO_TEST_DTC" 2 "FAILED_DTC" 1 "PASSED_DTC" 0 "NOT_TESTED_DTC" ;
VAL_ 949 ESP_d047_blsStatusInvd 3 "UNABLE_TO_TEST_DTC" 2 "FAILED_DTC" 1 "PASSED_DTC" 0 "NOT_TESTED_DTC" ;
VAL_ 949 ESP_d048_brakeSwitchPlausib 3 "UNABLE_TO_TEST_DTC" 2 "FAILED_DTC" 1 "PASSED_DTC" 0 "NOT_TESTED_DTC" ;
VAL_ 949 ESP_d049_pressSenMc1Line 3 "UNABLE_TO_TEST_DTC" 2 "FAILED_DTC" 1 "PASSED_DTC" 0 "NOT_TESTED_DTC" ;
VAL_ 949 ESP_d050_acmPsOfstMc1 3 "UNABLE_TO_TEST_DTC" 2 "FAILED_DTC" 1 "PASSED_DTC" 0 "NOT_TESTED_DTC" ;
VAL_ 949 ESP_d051_acmPsTstpulseMc1 3 "UNABLE_TO_TEST_DTC" 2 "FAILED_DTC" 1 "PASSED_DTC" 0 "NOT_TESTED_DTC" ;
VAL_ 949 ESP_d052_comSclLowBrakeFluid 3 "UNABLE_TO_TEST_DTC" 2 "FAILED_DTC" 1 "PASSED_DTC" 0 "NOT_TESTED_DTC" ;
VAL_ 949 ESP_d053_sasMonConstSig 3 "UNABLE_TO_TEST_DTC" 2 "FAILED_DTC" 1 "PASSED_DTC" 0 "NOT_TESTED_DTC" ;
VAL_ 949 ESP_d054_sasMonOfst 3 "UNABLE_TO_TEST_DTC" 2 "FAILED_DTC" 1 "PASSED_DTC" 0 "NOT_TESTED_DTC" ;
VAL_ 949 ESP_d055_sasPlausibility 3 "UNABLE_TO_TEST_DTC" 2 "FAILED_DTC" 1 "PASSED_DTC" 0 "NOT_TESTED_DTC" ;
VAL_ 949 ESP_d056_aySensorFault 3 "UNABLE_TO_TEST_DTC" 2 "FAILED_DTC" 1 "PASSED_DTC" 0 "NOT_TESTED_DTC" ;
VAL_ 949 ESP_d057_aysMonRange 3 "UNABLE_TO_TEST_DTC" 2 "FAILED_DTC" 1 "PASSED_DTC" 0 "NOT_TESTED_DTC" ;
VAL_ 949 ESP_d058_aysOffset 3 "UNABLE_TO_TEST_DTC" 2 "FAILED_DTC" 1 "PASSED_DTC" 0 "NOT_TESTED_DTC" ;
VAL_ 949 ESP_d059_aysPlaus 3 "UNABLE_TO_TEST_DTC" 2 "FAILED_DTC" 1 "PASSED_DTC" 0 "NOT_TESTED_DTC" ;
VAL_ 949 ESP_d060_axSensorFault 3 "UNABLE_TO_TEST_DTC" 2 "FAILED_DTC" 1 "PASSED_DTC" 0 "NOT_TESTED_DTC" ;
VAL_ 949 ESP_d061_axsMonRange 3 "UNABLE_TO_TEST_DTC" 2 "FAILED_DTC" 1 "PASSED_DTC" 0 "NOT_TESTED_DTC" ;
VAL_ 949 ESP_d062_axOffsTooLarge 3 "UNABLE_TO_TEST_DTC" 2 "FAILED_DTC" 1 "PASSED_DTC" 0 "NOT_TESTED_DTC" ;
VAL_ 949 ESP_d063_axSensorPlaus 3 "UNABLE_TO_TEST_DTC" 2 "FAILED_DTC" 1 "PASSED_DTC" 0 "NOT_TESTED_DTC" ;
VAL_ 949 ESP_d064_yawSensorFault 3 "UNABLE_TO_TEST_DTC" 2 "FAILED_DTC" 1 "PASSED_DTC" 0 "NOT_TESTED_DTC" ;
VAL_ 949 ESP_d065_yawSensorPlaus 3 "UNABLE_TO_TEST_DTC" 2 "FAILED_DTC" 1 "PASSED_DTC" 0 "NOT_TESTED_DTC" ;
VAL_ 949 ESP_d066_absVdcContControl 3 "UNABLE_TO_TEST_DTC" 2 "FAILED_DTC" 1 "PASSED_DTC" 0 "NOT_TESTED_DTC" ;
VAL_ 949 ESP_d067_undervoltage 3 "UNABLE_TO_TEST_DTC" 2 "FAILED_DTC" 1 "PASSED_DTC" 0 "NOT_TESTED_DTC" ;
VAL_ 949 ESP_d068_overvoltage 3 "UNABLE_TO_TEST_DTC" 2 "FAILED_DTC" 1 "PASSED_DTC" 0 "NOT_TESTED_DTC" ;
VAL_ 949 ESP_d069_memoryFault 3 "UNABLE_TO_TEST_DTC" 2 "FAILED_DTC" 1 "PASSED_DTC" 0 "NOT_TESTED_DTC" ;
VAL_ 949 ESP_d070_ecuInternalGeneric 3 "UNABLE_TO_TEST_DTC" 2 "FAILED_DTC" 1 "PASSED_DTC" 0 "NOT_TESTED_DTC" ;
VAL_ 949 ESP_d071_ecuInternalEcu 3 "UNABLE_TO_TEST_DTC" 2 "FAILED_DTC" 1 "PASSED_DTC" 0 "NOT_TESTED_DTC" ;
VAL_ 949 ESP_d072_valveGeneric 3 "UNABLE_TO_TEST_DTC" 2 "FAILED_DTC" 1 "PASSED_DTC" 0 "NOT_TESTED_DTC" ;
VAL_ 949 ESP_d073_valveAvFaults 3 "UNABLE_TO_TEST_DTC" 2 "FAILED_DTC" 1 "PASSED_DTC" 0 "NOT_TESTED_DTC" ;
VAL_ 949 ESP_d074_valveEvFaults 3 "UNABLE_TO_TEST_DTC" 2 "FAILED_DTC" 1 "PASSED_DTC" 0 "NOT_TESTED_DTC" ;
VAL_ 949 ESP_d075_valveHsvFaults 3 "UNABLE_TO_TEST_DTC" 2 "FAILED_DTC" 1 "PASSED_DTC" 0 "NOT_TESTED_DTC" ;
VAL_ 949 ESP_d076_valveUsvFaults 3 "UNABLE_TO_TEST_DTC" 2 "FAILED_DTC" 1 "PASSED_DTC" 0 "NOT_TESTED_DTC" ;
VAL_ 949 ESP_d077_refNotInitInTime 3 "UNABLE_TO_TEST_DTC" 2 "FAILED_DTC" 1 "PASSED_DTC" 0 "NOT_TESTED_DTC" ;
VAL_ 949 ESP_d078_acmBtmOheatBraking 3 "UNABLE_TO_TEST_DTC" 2 "FAILED_DTC" 1 "PASSED_DTC" 0 "NOT_TESTED_DTC" ;
VAL_ 949 ESP_d079_varCodeEeprom 3 "UNABLE_TO_TEST_DTC" 2 "FAILED_DTC" 1 "PASSED_DTC" 0 "NOT_TESTED_DTC" ;
VAL_ 949 ESP_d080_reverseGearPlaus 3 "UNABLE_TO_TEST_DTC" 2 "FAILED_DTC" 1 "PASSED_DTC" 0 "NOT_TESTED_DTC" ;
VAL_ 949 ESP_d081_comSclVinAllZeroFF 3 "UNABLE_TO_TEST_DTC" 2 "FAILED_DTC" 1 "PASSED_DTC" 0 "NOT_TESTED_DTC" ;
VAL_ 949 ESP_d082_comSclVip405HsImpVin 3 "UNABLE_TO_TEST_DTC" 2 "FAILED_DTC" 1 "PASSED_DTC" 0 "NOT_TESTED_DTC" ;
VAL_ 949 ESP_d083_comSclVip405HsDtCrpt 3 "UNABLE_TO_TEST_DTC" 2 "FAILED_DTC" 1 "PASSED_DTC" 0 "NOT_TESTED_DTC" ;
VAL_ 949 ESP_d084_comSclVip405HsTout 3 "UNABLE_TO_TEST_DTC" 2 "FAILED_DTC" 1 "PASSED_DTC" 0 "NOT_TESTED_DTC" ;
VAL_ 949 ESP_d085_rollerBenchActv 3 "UNABLE_TO_TEST_DTC" 2 "FAILED_DTC" 1 "PASSED_DTC" 0 "NOT_TESTED_DTC" ;
VAL_ 949 ESP_d086_network0 3 "UNABLE_TO_TEST_DTC" 2 "FAILED_DTC" 1 "PASSED_DTC" 0 "NOT_TESTED_DTC" ;
VAL_ 949 ESP_d087_network1 3 "UNABLE_TO_TEST_DTC" 2 "FAILED_DTC" 1 "PASSED_DTC" 0 "NOT_TESTED_DTC" ;
VAL_ 949 ESP_d088_comMotorTOut 3 "UNABLE_TO_TEST_DTC" 2 "FAILED_DTC" 1 "PASSED_DTC" 0 "NOT_TESTED_DTC" ;
VAL_ 949 ESP_d089_comDrsTxTOut 3 "UNABLE_TO_TEST_DTC" 2 "FAILED_DTC" 1 "PASSED_DTC" 0 "NOT_TESTED_DTC" ;
VAL_ 949 ESP_d090_comSclStwAnglhpTout 3 "UNABLE_TO_TEST_DTC" 2 "FAILED_DTC" 1 "PASSED_DTC" 0 "NOT_TESTED_DTC" ;
VAL_ 949 ESP_d091_comSclEpbStatusTout 3 "UNABLE_TO_TEST_DTC" 2 "FAILED_DTC" 1 "PASSED_DTC" 0 "NOT_TESTED_DTC" ;
VAL_ 949 ESP_d092_comIbEsptTOut 3 "UNABLE_TO_TEST_DTC" 2 "FAILED_DTC" 1 "PASSED_DTC" 0 "NOT_TESTED_DTC" ;
VAL_ 949 ESP_d093_comSclBdyStatusTout 3 "UNABLE_TO_TEST_DTC" 2 "FAILED_DTC" 1 "PASSED_DTC" 0 "NOT_TESTED_DTC" ;
VAL_ 949 ESP_d094_comSclGtwEsp1Tout 3 "UNABLE_TO_TEST_DTC" 2 "FAILED_DTC" 1 "PASSED_DTC" 0 "NOT_TESTED_DTC" ;
VAL_ 949 ESP_d095_comSclGtwOdoTout 3 "UNABLE_TO_TEST_DTC" 2 "FAILED_DTC" 1 "PASSED_DTC" 0 "NOT_TESTED_DTC" ;
VAL_ 949 ESP_d096_comSclGtwCarCfgTout 3 "UNABLE_TO_TEST_DTC" 2 "FAILED_DTC" 1 "PASSED_DTC" 0 "NOT_TESTED_DTC" ;
VAL_ 949 ESP_d097_comMotorCrpt 3 "UNABLE_TO_TEST_DTC" 2 "FAILED_DTC" 1 "PASSED_DTC" 0 "NOT_TESTED_DTC" ;
VAL_ 949 ESP_d098_comMotorMsgCount 3 "UNABLE_TO_TEST_DTC" 2 "FAILED_DTC" 1 "PASSED_DTC" 0 "NOT_TESTED_DTC" ;
VAL_ 949 ESP_d099_comMotorInvalidSig 3 "UNABLE_TO_TEST_DTC" 2 "FAILED_DTC" 1 "PASSED_DTC" 0 "NOT_TESTED_DTC" ;
VAL_ 949 ESP_d100_comSclEpbStatusCrpt 3 "UNABLE_TO_TEST_DTC" 2 "FAILED_DTC" 1 "PASSED_DTC" 0 "NOT_TESTED_DTC" ;
VAL_ 949 ESP_d101_comIbEspCrpt 3 "UNABLE_TO_TEST_DTC" 2 "FAILED_DTC" 1 "PASSED_DTC" 0 "NOT_TESTED_DTC" ;
VAL_ 949 ESP_d102_comIbEspMsgCount 3 "UNABLE_TO_TEST_DTC" 2 "FAILED_DTC" 1 "PASSED_DTC" 0 "NOT_TESTED_DTC" ;
VAL_ 949 ESP_d103_sclIbEspInvalidSig 3 "UNABLE_TO_TEST_DTC" 2 "FAILED_DTC" 1 "PASSED_DTC" 0 "NOT_TESTED_DTC" ;
VAL_ 949 ESP_d104_comSclBdyStatusCrpt 3 "UNABLE_TO_TEST_DTC" 2 "FAILED_DTC" 1 "PASSED_DTC" 0 "NOT_TESTED_DTC" ;
VAL_ 949 ESP_d105_comStwAnglHpCrpt 3 "UNABLE_TO_TEST_DTC" 2 "FAILED_DTC" 1 "PASSED_DTC" 0 "NOT_TESTED_DTC" ;
VAL_ 949 ESP_d106_comStwAnglHpMsgCount 3 "UNABLE_TO_TEST_DTC" 2 "FAILED_DTC" 1 "PASSED_DTC" 0 "NOT_TESTED_DTC" ;
VAL_ 949 ESP_d107_comSasInvalidSig 3 "UNABLE_TO_TEST_DTC" 2 "FAILED_DTC" 1 "PASSED_DTC" 0 "NOT_TESTED_DTC" ;
VAL_ 949 ESP_d108_comDrsTxCrpt 3 "UNABLE_TO_TEST_DTC" 2 "FAILED_DTC" 1 "PASSED_DTC" 0 "NOT_TESTED_DTC" ;
VAL_ 949 ESP_d109_sclMm3InvalidSig 3 "UNABLE_TO_TEST_DTC" 2 "FAILED_DTC" 1 "PASSED_DTC" 0 "NOT_TESTED_DTC" ;
VAL_ 949 ESP_d110_comGtwEsp1Crpt 3 "UNABLE_TO_TEST_DTC" 2 "FAILED_DTC" 1 "PASSED_DTC" 0 "NOT_TESTED_DTC" ;
VAL_ 949 ESP_d111_comSclGtwEsp1CntFlt 3 "UNABLE_TO_TEST_DTC" 2 "FAILED_DTC" 1 "PASSED_DTC" 0 "NOT_TESTED_DTC" ;
VAL_ 949 ESP_d112_comSclGtwOdoDtCrpt 3 "UNABLE_TO_TEST_DTC" 2 "FAILED_DTC" 1 "PASSED_DTC" 0 "NOT_TESTED_DTC" ;
VAL_ 949 ESP_d113_comSclGtwCrCfgDtCrpt 3 "UNABLE_TO_TEST_DTC" 2 "FAILED_DTC" 1 "PASSED_DTC" 0 "NOT_TESTED_DTC" ;
VAL_ 949 ESP_d114_teslaChassisTypeSna 3 "UNABLE_TO_TEST_DTC" 2 "FAILED_DTC" 1 "PASSED_DTC" 0 "NOT_TESTED_DTC" ;
VAL_ 949 ESP_d115_varPlatCalMismtch 3 "UNABLE_TO_TEST_DTC" 2 "FAILED_DTC" 1 "PASSED_DTC" 0 "NOT_TESTED_DTC" ;
VAL_ 949 ESP_d116_ptsBlsStatusInvd 3 "UNABLE_TO_TEST_DTC" 2 "FAILED_DTC" 1 "PASSED_DTC" 0 "NOT_TESTED_DTC" ;
VAL_ 949 ESP_d117_comSclBdwReqInvalid 3 "UNABLE_TO_TEST_DTC" 2 "FAILED_DTC" 1 "PASSED_DTC" 0 "NOT_TESTED_DTC" ;
VAL_ 949 ESP_d118_rcmInvalidAx 3 "UNABLE_TO_TEST_DTC" 2 "FAILED_DTC" 1 "PASSED_DTC" 0 "NOT_TESTED_DTC" ;
VAL_ 949 ESP_d119_rcmInvalidAy 3 "UNABLE_TO_TEST_DTC" 2 "FAILED_DTC" 1 "PASSED_DTC" 0 "NOT_TESTED_DTC" ;
VAL_ 949 ESP_d120_rcmInvalidYaw 3 "UNABLE_TO_TEST_DTC" 2 "FAILED_DTC" 1 "PASSED_DTC" 0 "NOT_TESTED_DTC" ;
VAL_ 949 ESP_d121_rcmInvalidFrame1 3 "UNABLE_TO_TEST_DTC" 2 "FAILED_DTC" 1 "PASSED_DTC" 0 "NOT_TESTED_DTC" ;
VAL_ 949 ESP_d122_rcmInvalidFrame2 3 "UNABLE_TO_TEST_DTC" 2 "FAILED_DTC" 1 "PASSED_DTC" 0 "NOT_TESTED_DTC" ;
VAL_ 949 ESP_d123_rcmLostComm 3 "UNABLE_TO_TEST_DTC" 2 "FAILED_DTC" 1 "PASSED_DTC" 0 "NOT_TESTED_DTC" ;
VAL_ 949 ESP_d124_rcmIncompleteSensInfo 3 "UNABLE_TO_TEST_DTC" 2 "FAILED_DTC" 1 "PASSED_DTC" 0 "NOT_TESTED_DTC" ;
VAL_ 949 ESP_d125_rcmSerialNumMismatch 3 "UNABLE_TO_TEST_DTC" 2 "FAILED_DTC" 1 "PASSED_DTC" 0 "NOT_TESTED_DTC" ;
VAL_ 949 ESP_d126_rcmWrongSensorConfig 3 "UNABLE_TO_TEST_DTC" 2 "FAILED_DTC" 1 "PASSED_DTC" 0 "NOT_TESTED_DTC" ;
VAL_ 949 ESP_d127_rcmInvalidCalibration 3 "UNABLE_TO_TEST_DTC" 2 "FAILED_DTC" 1 "PASSED_DTC" 0 "NOT_TESTED_DTC" ;
VAL_ 949 ESP_d128_comSclPmState2TOut 3 "UNABLE_TO_TEST_DTC" 2 "FAILED_DTC" 1 "PASSED_DTC" 0 "NOT_TESTED_DTC" ;
VAL_ 949 ESP_d129_sclBdwReqActiveInvd 3 "UNABLE_TO_TEST_DTC" 2 "FAILED_DTC" 1 "PASSED_DTC" 0 "NOT_TESTED_DTC" ;
VAL_ 949 ESP_d130_comPmState2Crpt 3 "UNABLE_TO_TEST_DTC" 2 "FAILED_DTC" 1 "PASSED_DTC" 0 "NOT_TESTED_DTC" ;
VAL_ 949 ESP_d131_comSclPmState2CntFlt 3 "UNABLE_TO_TEST_DTC" 2 "FAILED_DTC" 1 "PASSED_DTC" 0 "NOT_TESTED_DTC" ;
VAL_ 949 ESP_d132_sclPmEbrCmdStateInvd 3 "UNABLE_TO_TEST_DTC" 2 "FAILED_DTC" 1 "PASSED_DTC" 0 "NOT_TESTED_DTC" ;
VAL_ 949 ESP_d133_acmVsSignalPlaus 3 "UNABLE_TO_TEST_DTC" 2 "FAILED_DTC" 1 "PASSED_DTC" 0 "NOT_TESTED_DTC" ;
VAL_ 949 ESP_d134_sasMonRange 3 "UNABLE_TO_TEST_DTC" 2 "FAILED_DTC" 1 "PASSED_DTC" 0 "NOT_TESTED_DTC" ;
VAL_ 949 ESP_d135_sasMonGrad 3 "UNABLE_TO_TEST_DTC" 2 "FAILED_DTC" 1 "PASSED_DTC" 0 "NOT_TESTED_DTC" ;
VAL_ 949 ESP_d136_yrsSignalOutOfRange 3 "UNABLE_TO_TEST_DTC" 2 "FAILED_DTC" 1 "PASSED_DTC" 0 "NOT_TESTED_DTC" ;
VAL_ 949 ESP_d137_yrsMonGrad 3 "UNABLE_TO_TEST_DTC" 2 "FAILED_DTC" 1 "PASSED_DTC" 0 "NOT_TESTED_DTC" ;
VAL_ 949 ESP_d138_yrsOffsetTooLarge 3 "UNABLE_TO_TEST_DTC" 2 "FAILED_DTC" 1 "PASSED_DTC" 0 "NOT_TESTED_DTC" ;
VAL_ 949 ESP_d139_evpSigPlausibility 3 "UNABLE_TO_TEST_DTC" 2 "FAILED_DTC" 1 "PASSED_DTC" 0 "NOT_TESTED_DTC" ;
VAL_ 949 ESP_d140_evpVacSigLow 3 "UNABLE_TO_TEST_DTC" 2 "FAILED_DTC" 1 "PASSED_DTC" 0 "NOT_TESTED_DTC" ;
VAL_ 949 ESP_d141_vacSensorElectFail 3 "UNABLE_TO_TEST_DTC" 2 "FAILED_DTC" 1 "PASSED_DTC" 0 "NOT_TESTED_DTC" ;
VAL_ 949 ESP_d142_canCommGeneral 3 "UNABLE_TO_TEST_DTC" 2 "FAILED_DTC" 1 "PASSED_DTC" 0 "NOT_TESTED_DTC" ;
VAL_ 949 ESP_d143_mcuChassisContrDtCrpt 3 "UNABLE_TO_TEST_DTC" 2 "FAILED_DTC" 1 "PASSED_DTC" 0 "NOT_TESTED_DTC" ;
VAL_ 949 ESP_d144_mcuChassisContrTout 3 "UNABLE_TO_TEST_DTC" 2 "FAILED_DTC" 1 "PASSED_DTC" 0 "NOT_TESTED_DTC" ;
VAL_ 533 ESP_ebrMode 5 "FULL_SYSTEM" 4 "FAILED_OPERATIONAL" 3 "FAILED_DEGRADED" 2 "EMERGENCY_MODE" 1 "UNABLE_TO_EXECUTE" 0 "FAULTED" ;
VAL_ 533 ESP_ebrSystemMode 5 "FULL_SYSTEM" 4 "FAILED_OPERATIONAL" 3 "FAILED_DEGRADED" 2 "EMERGENCY_MODE" 1 "UNABLE_TO_EXECUTE" 0 "FAULTED" ;
VAL_ 533 ESP_brakeTorqueTarget2 8191 "SNA" ;
VAL_ 533 ESP_ebrSource 1 "DAS_EBR" 0 "DI_EBR" ;
VAL_ 533 ESP_ebrState 2 "EBR_RELEASING_FOR_SKID" 1 "ACTIVE" 0 "INACTIVE" ;
VAL_ 805 ESP_infoIndex 255 "INFO_END" 22 "INFO_VARIANT_CRC" 20 "INFO_UDS_PROTOCOL_BOOTCRC" 19 "INFO_VERSION_DEPRECATED" 18 "INFO_BOOTLOADER_GITHASH" 17 "INFO_APP_GITHASH" 16 "INFO_SUBCOMPONENT" 15 "INFO_BOOTLOADER_CRC" 14 "INFO_BOOTLOADER_SVN" 13 "INFO_APP_CRC" 11 "INFO_PCBAID_ASSYID_USAGEID" 10 "INFO_BUILD_HWID_COMPONENTID" 9 "INFO_DEPRECATED_9" 8 "INFO_DEPRECATED_8" 7 "INFO_DEPRECATED_7" 6 "INFO_DEPRECATED_6" 5 "INFO_DEPRECATED_5" 4 "INFO_DEPRECATED_4" 3 "INFO_DEPRECATED_3" 2 "INFO_DEPRECATED_2" 1 "INFO_DEPRECATED_1" 0 "INFO_DEPRECATED_0" ;
VAL_ 805 ESP_vehicleVariant 4 "MODEL_X_AWD" 3 "MODEL_S_AWD" 2 "MODEL_S_RWD_ESP_TC" 1 "MODEL_S_RWD_TESLA_TC" ;
VAL_ 901 ESP_latAccelOffsetComp 255 "SNA" ;
VAL_ 901 ESP_longAccelOffsetComp 255 "SNA" ;
VAL_ 901 ESP_yawrateOffsetComp 511 "SNA" ;
VAL_ 901 ESP_masterCylOffsetComp 127 "PRESSURE_OFFSET_SNA" ;
VAL_ 285 ESP_wheelSlipFrL 1023 "SNA" ;
VAL_ 285 ESP_wheelSlipFrR 1023 "SNA" ;
VAL_ 285 ESP_wheelSlipReL 1023 "SNA" ;
VAL_ 285 ESP_wheelSlipReR 1023 "SNA" ;
VAL_ 285 ESP_vdcActuatorState 3 "VDC_COMMAND_INVALID" 2 "VDC_ACTUATOR_AVAILABLE" 1 "VDC_ACTUATOR_DEGRADED" 0 "VDC_ACTUATOR_UNAVAILABLE" ;
VAL_ 285 ESP_wheelSaturationFrL 2 "OTHER_LIMIT" 1 "BSC_SLIP_LIMIT" 0 "NOT_SATURATED" ;
VAL_ 285 ESP_wheelSaturationFrR 2 "OTHER_LIMIT" 1 "BSC_SLIP_LIMIT" 0 "NOT_SATURATED" ;
VAL_ 285 ESP_wheelSaturationReL 2 "OTHER_LIMIT" 1 "BSC_SLIP_LIMIT" 0 "NOT_SATURATED" ;
VAL_ 285 ESP_wheelSaturationReR 2 "OTHER_LIMIT" 1 "BSC_SLIP_LIMIT" 0 "NOT_SATURATED" ;
VAL_ 373 ESP_wheelSpeedFrL_HS 8191 "SNA" ;
VAL_ 373 ESP_wheelSpeedFrR_HS 8191 "SNA" ;
VAL_ 373 ESP_wheelSpeedReL_HS 8191 "SNA" ;
VAL_ 373 ESP_wheelSpeedReR_HS 8191 "SNA" ;
VAL_ 520 GTW_hillStartAssistDisabled 1 "HSA_DISABLED" 0 "HSA_ENABLED" ;
VAL_ 520 GTW_brakeDiscWipeRequest 3 "BDW_SNA" 2 "BDW_STRONG" 1 "BDW_LIGHT" 0 "BDW_NO_REQUEST" ;
VAL_ 520 GTW_pedalCalRxEnable 1 "ENABLED" 0 "DISABLED" ;
VAL_ 520 GTW_ambientTemperature 255 "SNA" ;
VAL_ 520 GTW_pedalCalTargetCurve 6 "SNA" 5 "PEDAL_CURVE_5" 4 "PEDAL_CURVE_4" 3 "PEDAL_CURVE_3" 2 "PEDAL_CURVE_2" 1 "PEDAL_CURVE_1" 0 "PEDAL_CURVE_0" ;
VAL_ 520 GTW_espModeSwitch 5 "SWITCH_03_PRESSED_ESP_DEV_2" 4 "SWITCH_02_PRESSED_ESP_DEV_1" 3 "SWITCH_01_PRESSED_TC_OFF" 2 "SNA" 1 "SWITCH_00_PRESSED_NORMAL" 0 "SWITCH_NOT_PRESSED" ;
VAL_ 552 GTW_airbagCutOffSwState 3 "UNUSED" 2 "SNA" 1 "PASSENGER_AIRBAG_OFF" 0 "PASSENGER_AIRBAG_ON" ;
VAL_ 552 GTW_warningIndicatorStatus 3 "SNA" 2 "UNUSED" 1 "WARNING_LAMP_ON" 0 "WARNING_LAMP_OFF" ;
VAL_ 920 GTW_performanceConfig 7 "P7" 6 "P6" 5 "P5" 4 "P4" 3 "P3" 2 "P2" 1 "P1" 0 "CONFIG_SNA" ;
VAL_ 920 GTW_fourWheelDrive 3 "SNA" 2 "UNUSED" 1 "4WD" 0 "2WD" ;
VAL_ 920 GTW_rearDriveUnitType 1 "SMALL_REAR" 0 "LARGE_REAR" ;
VAL_ 920 GTW_brakeHwType 2 "BREMBO_P44_MANDO_43MOC" 1 "BREMBO_P40_MANDO_43MOC" 0 "BREMBO_P40_BREMBO_P28_BREMBO_EPB" ;
VAL_ 920 GTW_parkAssistInstalled 3 "VALEO_5" 2 "BOSCH_5" 1 "BOSCH_4_5" 0 "NONE" ;
VAL_ 920 GTW_forwardRadarHw 2 "CONTI_ARS410" 1 "BOSCH_MRR14" 0 "NONE" ;
VAL_ 920 GTW_airSuspensionInstalled 5 "TESLA_ADAPTIVE" 4 "TESLA_PLUS" 3 "TESLA_STANDARD" 2 "PLUS" 1 "STANDARD" 0 "NONE" ;
VAL_ 920 GTW_parkSensorGeometryType 2 "MODELX" 1 "MODELS_2" 0 "MODELS" ;
VAL_ 920 GTW_bodyControlsType 1 "TESLA" 0 "PEKTRON" ;
VAL_ 920 GTW_radarPosition 2 "MODELX" 1 "MODELS_2" 0 "MODELS" ;
VAL_ 920 GTW_dasHw 4 "TESLA_AP3" 3 "PARKER_PASCAL_2_5" 2 "PARKER_PASCAL" 1 "MONOCAM" 0 "NONE" ;
VAL_ 920 GTW_epasType 4 "MANDO_VGR66_GEN3" 3 "MANDO_VGR66" 2 "MANDO_FGR64" 1 "BOSCH_L405" 0 "BOSCH_L538" ;
VAL_ 920 GTW_restraintControlsType 1 "BOSCH_RCM" 0 "SDM" ;
VAL_ 920 GTW_wheelType 31 "CONFIG_SNA" 26 "TEMPEST_19_SONICSILVER" 25 "TWINTURBINE_21_CARBON" 24 "TWINTURBINE_21_SILVER" 23 "SLIPSTREAM_19_CARBON" 22 "SLIPSTREAM_20_SLVRBLK" 21 "SLIPSTREAM_20_CARBON" 20 "ARACHNID_21_GREY" 19 "ARACHNID_21_BLACK" 18 "ARACHNID_21_SILVER" 17 "TURBINE_22_BLACK" 16 "AERO_TURBINE_20_SLVRBLK" 15 "CYCLONE_19_GREY" 14 "TURBINE_22_SILVER" 13 "AERO_TURBINE_20_SILVER" 12 "HELIX_20_SILVER" 11 "AERO_TURBINE_19_BLACK" 10 "AERO_TURBINE_19_METAL" 9 "TURBINE_19_CHARCOAL" 8 "TURBINE_19" 7 "SUPER_21_SILVER" 6 "SUPER_21_GRAY" 5 "CHARCOAL_21_EURO" 4 "AERO_19" 3 "SILVER_21_EURO" 2 "CHARCOAL_21" 1 "SILVER_21" 0 "BASE_19" ;
VAL_ 920 GTW_efuseType 1 "TESLA_REV1" 0 "NONE" ;
VAL_ 920 GTW_autopilot 4 "BASIC" 3 "SELF_DRIVING" 2 "ENHANCED" 1 "HIGHWAY" 0 "NONE" ;
VAL_ 920 GTW_chassisType 2 "MODEL_3_CHASSIS" 1 "MODEL_X_CHASSIS" 0 "MODEL_S_CHASSIS" ;
VAL_ 857 GTW_memorySeatsInstalled 3 "TESLA_GEN1" 2 "BITRON_GEN2" 1 "BITRON_GEN1" 0 "SEAT_NONE" ;
VAL_ 857 GTW_autopilotCameraType 2 "RCCB_CAMERAS" 1 "RCCC_CAMERAS" 0 "UNKNOWN" ;
VAL_ 792 YEAR 127 "SNA" 126 "Init" ;
VAL_ 792 CERRD 1 "CAN error detect" 0 "no Can error detected" ;
VAL_ 792 MONTH 15 "SNA" 1 "Init" ;
VAL_ 792 DOOR_STATE_FL 3 "SNA" 2 "Init" 1 "open" 0 "closed" ;
VAL_ 792 DOOR_STATE_FR 3 "SNA" 2 "Init" 1 "open" 0 "closed" ;
VAL_ 792 SECOND 63 "SNA" 62 "Init" ;
VAL_ 792 DOOR_STATE_RL 3 "SNA" 2 "Init" 1 "open" 0 "closed" ;
VAL_ 792 Hour 31 "SNA" 30 "Init" ;
VAL_ 792 DOOR_STATE_RR 3 "SNA" 2 "Init" 1 "open" 0 "closed" ;
VAL_ 792 DAY 1 "Init" 0 "SNA" ;
VAL_ 792 BC_courtesyLightingActive 3 "Default" 2 "Not_defined" 1 "Active" 0 "Not_Active" ;
VAL_ 792 MINUTE 63 "SNA" 62 "Init" ;
VAL_ 792 BOOT_STATE 3 "SNA" 2 "Init" 1 "open" 0 "closed" ;
VAL_ 792 GTW_updateInProgress 3 "UPDATE_IN_PROGRESS_SNA" 2 "UPDATE_IN_PROGRESS_NOT_USED" 1 "UPDATE_IN_PROGRESS" 0 "UPDATE_NOT_IN_PROGRESS" ;
VAL_ 792 DOOR_STATE_FrontTrunk 3 "SNA" 2 "Init" 1 "open" 0 "closed" ;
VAL_ 792 MCU_factoryMode 1 "FACTORY_MODE" 0 "NORMAL_MODE" ;
VAL_ 792 MCU_transportModeOn 1 "TRANSPORT_MODE" 0 "NORMAL_MODE" ;
VAL_ 792 BC_headLightLStatus 3 "default_headlight" 2 "Failed" 1 "On" 0 "Off" ;
VAL_ 792 BC_headLightRStatus 3 "default_headlight" 2 "Failed" 1 "On" 0 "Off" ;
VAL_ 792 BC_indicatorLStatus 3 "default" 2 "Failed" 1 "On" 0 "Off" ;
VAL_ 792 BC_indicatorRStatus 3 "default" 2 "Failed" 1 "On" 0 "Off" ;
VAL_ 1912 GTW_chargeState 6 "CHARGE_STATE_MAX" 5 "CHARGE_STATE_STOPPED" 4 "CHARGE_STATE_COMPLETE" 3 "CHARGE_STATE_CHARGING" 2 "CHARGE_STATE_ABOUT_TO_CHARGE" 1 "CHARGE_STATE_NO_POWER" 0 "CHARGE_STATE_DISCONNECTED" ;
VAL_ 1912 GTW_chargeDisconElab 18 "CHARGE_STATE_ELAB_NOT_COMPLETE" 17 "CHARGE_STATE_ELAB_CHG_REQ_CHANGE" 16 "CHARGE_STATE_ELAB_NO_CHG_ENABLE" 15 "CHARGE_STATE_ELAB_MALFUNCTION" 13 "CHARGE_STATE_ELAB_WALL_PLUG_OUT" 12 "CHARGE_STATE_ELAB_DIS_WHILE_CHG" 11 "CHARGE_STATE_ELAB_WAIT_BMS" 10 "CHARGE_STATE_ELAB_WALL_FAULT" 9 "CHARGE_STATE_ELAB_CHG_FAULT" 8 "CHARGE_STATE_ELAB_BMS_FAULT" 7 "CHARGE_STATE_ELAB_COMPLETE" 6 "CHARGE_STATE_ELAB_NO_CHARGE_REQ" 5 "CHARGE_STATE_ELAB_POWER_NOT_GOOD" 4 "CHARGE_STATE_ELAB_POWER_GOOD" 3 "CHARGE_STATE_ELAB_PILOT_NOT_GOOD" 2 "CHARGE_STATE_ELAB_PILOT_GOOD" 1 "CHARGE_STATE_ELAB_LATCHED" 0 "CHARGE_STATE_ELAB_DISCON" ;
VAL_ 1912 GTW_chargeNoPowerElab 18 "CHARGE_STATE_ELAB_NOT_COMPLETE" 17 "CHARGE_STATE_ELAB_CHG_REQ_CHANGE" 16 "CHARGE_STATE_ELAB_NO_CHG_ENABLE" 15 "CHARGE_STATE_ELAB_MALFUNCTION" 13 "CHARGE_STATE_ELAB_WALL_PLUG_OUT" 12 "CHARGE_STATE_ELAB_DIS_WHILE_CHG" 11 "CHARGE_STATE_ELAB_WAIT_BMS" 10 "CHARGE_STATE_ELAB_WALL_FAULT" 9 "CHARGE_STATE_ELAB_CHG_FAULT" 8 "CHARGE_STATE_ELAB_BMS_FAULT" 7 "CHARGE_STATE_ELAB_COMPLETE" 6 "CHARGE_STATE_ELAB_NO_CHARGE_REQ" 5 "CHARGE_STATE_ELAB_POWER_NOT_GOOD" 4 "CHARGE_STATE_ELAB_POWER_GOOD" 3 "CHARGE_STATE_ELAB_PILOT_NOT_GOOD" 2 "CHARGE_STATE_ELAB_PILOT_GOOD" 1 "CHARGE_STATE_ELAB_LATCHED" 0 "CHARGE_STATE_ELAB_DISCON" ;
VAL_ 1912 GTW_aboutToChargeElab 18 "CHARGE_STATE_ELAB_NOT_COMPLETE" 17 "CHARGE_STATE_ELAB_CHG_REQ_CHANGE" 16 "CHARGE_STATE_ELAB_NO_CHG_ENABLE" 15 "CHARGE_STATE_ELAB_MALFUNCTION" 13 "CHARGE_STATE_ELAB_WALL_PLUG_OUT" 12 "CHARGE_STATE_ELAB_DIS_WHILE_CHG" 11 "CHARGE_STATE_ELAB_WAIT_BMS" 10 "CHARGE_STATE_ELAB_WALL_FAULT" 9 "CHARGE_STATE_ELAB_CHG_FAULT" 8 "CHARGE_STATE_ELAB_BMS_FAULT" 7 "CHARGE_STATE_ELAB_COMPLETE" 6 "CHARGE_STATE_ELAB_NO_CHARGE_REQ" 5 "CHARGE_STATE_ELAB_POWER_NOT_GOOD" 4 "CHARGE_STATE_ELAB_POWER_GOOD" 3 "CHARGE_STATE_ELAB_PILOT_NOT_GOOD" 2 "CHARGE_STATE_ELAB_PILOT_GOOD" 1 "CHARGE_STATE_ELAB_LATCHED" 0 "CHARGE_STATE_ELAB_DISCON" ;
VAL_ 1912 GTW_chargeChargingElab 18 "CHARGE_STATE_ELAB_NOT_COMPLETE" 17 "CHARGE_STATE_ELAB_CHG_REQ_CHANGE" 16 "CHARGE_STATE_ELAB_NO_CHG_ENABLE" 15 "CHARGE_STATE_ELAB_MALFUNCTION" 13 "CHARGE_STATE_ELAB_WALL_PLUG_OUT" 12 "CHARGE_STATE_ELAB_DIS_WHILE_CHG" 11 "CHARGE_STATE_ELAB_WAIT_BMS" 10 "CHARGE_STATE_ELAB_WALL_FAULT" 9 "CHARGE_STATE_ELAB_CHG_FAULT" 8 "CHARGE_STATE_ELAB_BMS_FAULT" 7 "CHARGE_STATE_ELAB_COMPLETE" 6 "CHARGE_STATE_ELAB_NO_CHARGE_REQ" 5 "CHARGE_STATE_ELAB_POWER_NOT_GOOD" 4 "CHARGE_STATE_ELAB_POWER_GOOD" 3 "CHARGE_STATE_ELAB_PILOT_NOT_GOOD" 2 "CHARGE_STATE_ELAB_PILOT_GOOD" 1 "CHARGE_STATE_ELAB_LATCHED" 0 "CHARGE_STATE_ELAB_DISCON" ;
VAL_ 1912 GTW_chargeCompleteElab 18 "CHARGE_STATE_ELAB_NOT_COMPLETE" 17 "CHARGE_STATE_ELAB_CHG_REQ_CHANGE" 16 "CHARGE_STATE_ELAB_NO_CHG_ENABLE" 15 "CHARGE_STATE_ELAB_MALFUNCTION" 13 "CHARGE_STATE_ELAB_WALL_PLUG_OUT" 12 "CHARGE_STATE_ELAB_DIS_WHILE_CHG" 11 "CHARGE_STATE_ELAB_WAIT_BMS" 10 "CHARGE_STATE_ELAB_WALL_FAULT" 9 "CHARGE_STATE_ELAB_CHG_FAULT" 8 "CHARGE_STATE_ELAB_BMS_FAULT" 7 "CHARGE_STATE_ELAB_COMPLETE" 6 "CHARGE_STATE_ELAB_NO_CHARGE_REQ" 5 "CHARGE_STATE_ELAB_POWER_NOT_GOOD" 4 "CHARGE_STATE_ELAB_POWER_GOOD" 3 "CHARGE_STATE_ELAB_PILOT_NOT_GOOD" 2 "CHARGE_STATE_ELAB_PILOT_GOOD" 1 "CHARGE_STATE_ELAB_LATCHED" 0 "CHARGE_STATE_ELAB_DISCON" ;
VAL_ 1912 GTW_chargeStoppedElab 18 "CHARGE_STATE_ELAB_NOT_COMPLETE" 17 "CHARGE_STATE_ELAB_CHG_REQ_CHANGE" 16 "CHARGE_STATE_ELAB_NO_CHG_ENABLE" 15 "CHARGE_STATE_ELAB_MALFUNCTION" 13 "CHARGE_STATE_ELAB_WALL_PLUG_OUT" 12 "CHARGE_STATE_ELAB_DIS_WHILE_CHG" 11 "CHARGE_STATE_ELAB_WAIT_BMS" 10 "CHARGE_STATE_ELAB_WALL_FAULT" 9 "CHARGE_STATE_ELAB_CHG_FAULT" 8 "CHARGE_STATE_ELAB_BMS_FAULT" 7 "CHARGE_STATE_ELAB_COMPLETE" 6 "CHARGE_STATE_ELAB_NO_CHARGE_REQ" 5 "CHARGE_STATE_ELAB_POWER_NOT_GOOD" 4 "CHARGE_STATE_ELAB_POWER_GOOD" 3 "CHARGE_STATE_ELAB_PILOT_NOT_GOOD" 2 "CHARGE_STATE_ELAB_PILOT_GOOD" 1 "CHARGE_STATE_ELAB_LATCHED" 0 "CHARGE_STATE_ELAB_DISCON" ;
VAL_ 296 REV_GEAR 3 "SNA" 2 "INIT" 1 "REVERSE_ACTIVE" 0 "REVERSE_NOT_ACTIVE" ;
VAL_ 296 GTW_diagDriveState 4 "DIAG_DRIVE_KEYPAIRING" 3 "DIAG_DRIVE_ENGINEERING" 2 "DIAG_DRIVE_SERVICE" 1 "DIAG_DRIVE_FACTORY" 0 "DIAG_DRIVE_OFF_SNA" ;
VAL_ 296 ENG_RPM 65535 "SNA" 65534 "Init" ;
VAL_ 257 GTW_epasTuneRequest 7 "RESERVED" 6 "RWD_SPORT" 5 "RWD_STANDARD" 4 "RWD_COMFORT" 3 "DM_SPORT" 2 "DM_STANDARD" 1 "DM_COMFORT" 0 "FAIL_SAFE_DEFAULT" ;
VAL_ 257 GTW_epasPowerMode 15 "SNA" 3 "LOAD_SHED" 2 "SHUTTING_DOWN" 1 "DRIVE_ON" 0 "DRIVE_OFF" ;
VAL_ 257 GTW_epasEmergencyOn 1 "EMERGENCY_POWER" 0 "NONE" ;
VAL_ 257 GTW_epasLDWEnabled 1 "LDW_ALLOWED" 0 "LDW_INHIBITED" ;
VAL_ 257 GTW_epasControlType 3 "POWER_STEERING_WITH_BOTH" 2 "POWER_STEERING_WITH_TORQUE" 1 "POWER_STEERING_WITH_ANGLE" 0 "POWER_STEERING_WITHOUT" ;
VAL_ 888 GTW_ibsVoltage 65535 "SNA" ;
VAL_ 776 GTW_easManualLevelRequest 7 "REQUEST_VERY_LOW_LEVEL" 6 "SWITCH_DEFECT" 5 "TOGGLE_JACK_MODE" 4 "REQUEST_VERY_HIGH_LEVEL" 3 "REQUEST_HIGH_LEVEL" 2 "REQUEST_NORMAL_LEVEL" 1 "REQUEST_LOW_LEVEL" 0 "REQUEST_NONE" ;
VAL_ 776 GTW_espPlatCalMismatch 1 "MISMATCHED_CAL" 0 "VALID_CAL" ;
VAL_ 776 GTW_ibstConnectivityDisable 1 "CONNECTIVITY_DISABLED" 0 "CONNECTIVITY_ENABLED" ;
VAL_ 776 AMB_TEMP 255 "SNA" ;
VAL_ 776 GTW_ODO 16777215 "SNA" 16777214 "Init" ;
VAL_ 776 DI_tireFitment 3 "FITMENT_SNA" 1 "FITMENT_STAGGERED" 0 "FITMENT_SQUARE" ;
VAL_ 776 DI_steerCenter -128 "SNA" ;
VAL_ 936 MCU_requestBusWake 3 "SNA" 2 "BUS_MAY_SLEEP_NOW" 1 "BUS_AWAKE_NOW" ;
VAL_ 936 GTW_willBeGoingToSleep 3 "SNA" 2 "ABORTED" 1 "ACTIVE" 0 "IDLE" ;
VAL_ 936 GTW_clusterState 7 "CLUSTER_BOOT_WAIT" 6 "FORCED_OFF_CLUSTER" 5 "FORCING_OFF_CLUSTER" 4 "POWER_ON_CLUSTER" 3 "POWER_WAITING_CLUSTER" 2 "POWER_ENABLED_CLUSTER" 1 "OFF_WAIT_DONE_CLUSTER" 0 "OFF_CLUSTER" ;
VAL_ 936 MCU_clusterInstantOn 0 "ALLOW_CLUSTER_OFF_SNA" ;
VAL_ 936 MCU_gatewaySleepReq 7 "SNA" 3 "LOW_POWER_SLEEP" 2 "SLEEP_NOW" 1 "OK_TO_START" 0 "DONT_SLEEP" ;
VAL_ 936 MCU_updaterSleepDelay 0 "SNA" ;
VAL_ 1880 GTW_deepSleepMinutes 16383 "SNA" 16382 "NEVER" ;
VAL_ 840 GTW_vehiclePowerState 1 "DRIVE" 0 "NOT_DRIVE" ;
VAL_ 840 DOOR_STATE_RearTrunk 3 "SNA" 2 "Init" 1 "open" 0 "closed" ;
VAL_ 856 GTW_TPMSMode 2 "TPMS_PERFORMANCE_MODE" 1 "TPMS_NORMAL_MODE" 0 "TPMS_UNUSED_MODE" ;
VAL_ 856 GTW_TPMSLearnIDMode 4 "AUTO_LOCATION_ACTIVE_AFTER_PWR" 3 "AUTO_LEARN_ACTIVE_AFTER_PWR" 2 "AUTO_LOCATION_ACTIVE_BY_MANUAL" 1 "AUTO_LEARN_ACTIVE_BY_MANUAL" 0 "NO_ID_LEARN_FUNCTION" ;
VAL_ 856 GTW_sizeOfWheelSelect 2 "21_INCH_WHEEL" 1 "19_INCH_WHEEL" 0 "UNUSED" ;
VAL_ 856 GTW_sizeOfReqCANAutoLearn 2 "DO_NOT_DISPLAY_CAN_FRAME" 1 "DISPLAY_CAN_FRAME_AUTO_LEARN" 0 "UNUSED" ;
VAL_ 1469 IBST_alertID 16604 "IBST_d220_comSclDiTrq1CntFlt" 16603 "IBST_d219_comSclDiTrq1CsErr" 16602 "IBST_d218_comSclDiTrq1Corrpt" 16601 "IBST_d217_comSclDiTrq1Tout" 16600 "IBST_d216_comSclEpbStatCntFlt" 16599 "IBST_d215_comSclEpbStatCsErr" 16598 "IBST_d214_comsclEpbStatTout" 16597 "IBST_d213_comsclGtwStatTout" 16596 "IBST_d212_comsclGtwOdoTout" 16595 "IBST_d211_comsclEpbStatCorrpt" 16594 "IBST_d210_comsclGtwStatCorrpt" 16593 "IBST_d209_comsclGtwOdoCorrpt" 16592 "IBST_d208_sysSwClockMismatch" 16591 "IBST_d207_maxStrokeReached" 16590 "IBST_d206_netErrPassivNet1" 16589 "IBST_d205_netBusOffNet1" 16588 "IBST_d204_netErrPassivNet0" 16587 "IBST_d203_netBusOffNet0" 16586 "IBST_d202_sclEspIb3pTarDriver" 16585 "IBST_d201_sclEspIb3pMc1" 16584 "IBST_d200_sclEspIb3pFBlend" 16583 "IBST_d199_sclEspIb2qTarExt" 16582 "IBST_d198_sclEspIb2pLimExt" 16581 "IBST_d197_sclEspIb1VehSpd" 16580 "IBST_d196_sclEspIb1pEstMax" 16579 "IBST_d195_ecuIbEnContErr" 16578 "IBST_d194_ecuEnableB6Fail" 16577 "IBST_d193_ToutVin" 16576 "IBST_d192_dlCorCSumVin" 16575 "IBST_d191_plausVin" 16574 "IBST_d190_notProgVin" 16573 "IBST_d189_diffStrokeRange" 16572 "IBST_d188_pts1OffsEeReadFail" 16571 "IBST_d187_ltmSelfProtDeact" 16570 "IBST_d186_psOffsMcEeWriteFail" 16569 "IBST_d185_psOffsMcEeReadFail" 16568 "IBST_d184_maxTrvlAdjstReadErr" 16567 "IBST_d183_shutDownEeWriteFail" 16566 "IBST_d182_shutDownEeReadFail" 16565 "IBST_d181_rpsLengthAbsolLow" 16564 "IBST_d180_rpsLengthAbsolHigh" 16563 "IBST_d179_dcomSmrtActuNotInit" 16562 "IBST_d178_comsclGtwEsp1Tout" 16561 "IBST_d177_comsclGtwEsp1Corrpt" 16560 "IBST_d176_comsclGtwEsp1CsErr" 16559 "IBST_d175_comsclGtwEsp1CntErr" 16558 "IBST_d174_comsclEspIb3Tout" 16557 "IBST_d173_comsclEspIb3DlcErr" 16556 "IBST_d172_comsclEspIb3CsErr" 16555 "IBST_d171_comsclEspIb3CntErr" 16554 "IBST_d170_comsclEspIb2Tout" 16553 "IBST_d169_comsclEspIb2DlcErr" 16552 "IBST_d168_comsclEspIb2CsErr" 16551 "IBST_d167_comsclEspIb2CntErr" 16550 "IBST_d166_comsclEspIb1Tout" 16549 "IBST_d165_comsclEspIb1DlcErr" 16548 "IBST_d164_comsclEspIb1CsErr" 16547 "IBST_d163_comsclEspIb1CntErr" 16546 "IBST_d162_comsclBrkPrsPduTout" 16545 "IBST_d161_comsclBrkPrsPduLen" 16544 "IBST_d160_assertionFail" 16543 "IBST_d159_rpsSynchEeWriteFail" 16542 "IBST_d158_rpsSynchEeReadEmpty" 16541 "IBST_d157_rpsOffsYEeWriteFail" 16540 "IBST_d156_rpsOffsYEeReadEmpty" 16539 "IBST_d155_rpsOffsXEeWriteFail" 16538 "IBST_d154_rpsOffsXEeReadEmpty" 16537 "IBST_d153_pts2OffsEeWriteFail" 16536 "IBST_d152_pts2OffsEeReadFail" 16535 "IBST_d151_pts2CalEeWriteFail" 16534 "IBST_d150_pts2CalEeReadFail" 16533 "IBST_d149_pts1OffsEeWriteFail" 16532 "IBST_d148_rpsFailCompErr" 16531 "IBST_d147_pts1CalEeWriteFail" 16530 "IBST_d146_pts1CalEeReadFail" 16529 "IBST_d145_ptsCalValuesChkFail" 16528 "IBST_d144_ptsCalHysWritFail" 16527 "IBST_d143_pdmInternalHWErr" 16526 "IBST_d142_pdmHwAcsErr" 16525 "IBST_d141_pdmFieldSizeMis" 16524 "IBST_d140_pdmOutOfMemory" 16523 "IBST_d139_pdmDtFormatMis" 16522 "IBST_d138_pdmCustomerIdMis" 16521 "IBST_d137_motAnglGradTooLarge" 16520 "IBST_d136_motAnglBndWriteErr" 16519 "IBST_d135_motAnglBndReadErr" 16518 "IBST_d134_motPosTrvlWriteFail" 16517 "IBST_d133_motPosTrvlReadFail" 16516 "IBST_d132_esmSafetyFlt" 16515 "IBST_d131_esmNmiFlt" 16514 "IBST_d130_ecuRomCheck" 16513 "IBST_d129_ccmFlt" 16512 "IBST_d128_ecuAdcSelftestErr" 16511 "IBST_d127_ecuAdcConversionErr" 16510 "IBST_d126_ptsEeReadEmpty" 16509 "IBST_d125_motTrvlRelReadEmpty" 16508 "IBST_d124_motTrvlRelWriteFail" 16507 "IBST_d123_rpsAnglRecalcErr" 16506 "IBST_d122_rpsSynchEeReadFail" 16505 "IBST_d121_rpsOffsYEeReadFail" 16504 "IBST_d120_rpsOffsXEeReadFail" 16503 "IBST_d119_pts2OffsEeReadEmpty" 16502 "IBST_d118_pts1OffsEeReadEmpty" 16501 "IBST_d117_pdurEPduInstLost" 16500 "IBST_d116_pdurEInitFail" 16499 "IBST_d115_osErrHook" 16498 "IBST_d114_motShaftShiftDetect" 16497 "IBST_d113_motAngBoundReadEmpt" 16496 "IBST_d112_motPosTrvlReadEmpty" 16495 "IBST_d111_micIntVoltMonFld" 16494 "IBST_d110_micIntMonGenBitMon" 16493 "IBST_d109_micInitSpiTransfErr" 16492 "IBST_d108_micInitSpiTstFld" 16491 "IBST_d107_hetRefError" 16490 "IBST_d106_ecuTaskMissing" 16489 "IBST_d105_ecuHetTuException" 16488 "IBST_d104_ecuHetTuBusyErr" 16487 "IBST_d103_ecuHetTuBusErr" 16486 "IBST_d102_ecuHetTuAddErr" 16485 "IBST_d101_ecuHetException" 16484 "IBST_d100_ecuErrpinCntTstFls" 16483 "IBST_d099_ecuBmsOnWhileWdTout" 16482 "IBST_d098_ecuBandGap" 16481 "IBST_d097_cpuException" 16480 "IBST_d096_canETout" 16479 "IBST_d095_canEHwError" 16478 "IBST_d094_CalDataNotPlaus" 16477 "IBST_d093_bertFlt" 16476 "IBST_d092_ramsinlgeFlt" 16475 "IBST_d091_ramInitErr" 16474 "IBST_d090_pbistErr" 16473 "IBST_d089_ptsOffsTooHigh" 16472 "IBST_d088_faildevInputStroke" 16471 "IBST_d087_pts2LineHigh" 16470 "IBST_d086_pts2LineGnd" 16469 "IBST_d085_pts2Err" 16468 "IBST_d084_inputStroke2Grad" 16467 "IBST_d083_pts1LineHigh" 16466 "IBST_d082_pts1LineGnd" 16465 "IBST_d081_pts1Err" 16464 "IBST_d080_inputstroke1Grad" 16463 "IBST_d079_ecuSupVoltDivDrift" 16462 "IBST_d078_bcsFltCurrentLow" 16461 "IBST_d077_bcsFltCurrentHigh" 16460 "IBST_d076_tle5012VoltFail" 16459 "IBST_d075_hevSwitchOffDcom" 16458 "IBST_d074_tempB6Ch2LineLow" 16457 "IBST_d073_tempB6Ch2LineHigh" 16456 "IBST_d072_tempB6Ch1LineLow" 16455 "IBST_d071_tempB6Ch1LineHigh" 16454 "IBST_d070_cdmExtendedOvrvolt" 16453 "IBST_d069_cdmExtendedUndrvolt" 16452 "IBST_d068_tle5012LifeCnt" 16451 "IBST_d067_sOutRodToPressVal" 16450 "IBST_d066_ibSupVoltDivDrift" 16449 "IBST_d065_inputStroke2RngLow" 16448 "IBST_d064_inputStroke2RngHigh" 16447 "IBST_d063_inputStroke1RngLow" 16446 "IBST_d062_inputStroke1RngHigh" 16445 "IBST_d061_dcomEcuDefect" 16444 "IBST_d060_ltmLimitReached" 16443 "IBST_d059_maxTrvlAdjstUpdFail" 16442 "IBST_d058_cdmHardOvrvolt" 16441 "IBST_d057_cdmHardUndrvolt" 16440 "IBST_d056_ibNotShutDownRight" 16439 "IBST_d055_kl15HwPlausSw" 16438 "IBST_d054_bmsGateUndrvolt" 16437 "IBST_d053_tle5012UnexpReset" 16436 "IBST_d052_motTrvlRelReadFail" 16435 "IBST_d051_cdmUndrvoltLevel1" 16434 "IBST_d050_cdmUndrvoltLevel2" 16433 "IBST_d049_cdmOvrvoltLevel1" 16432 "IBST_d048_unintendMotorReturn" 16431 "IBST_d047_dcomIboosterNotInit" 16430 "IBST_d046_spiAnglOrRawNotUp" 16429 "IBST_d045_B6TempDegradeLevel2" 16428 "IBST_d044_b6TempDegradeLevel1" 16427 "IBST_d043_rpsVctrLengthRelErr" 16426 "IBST_d042_ltmWarnLevelReached" 16425 "IBST_d041_hswInitPhseUndrvolt" 16424 "IBST_d040_bmcGateUndervoltPro" 16423 "IBST_d039_calRoutineAbort" 16422 "IBST_d038_boostSupUndrvolt" 16421 "IBST_d037_calIdlePosNotPlaus" 16420 "IBST_d036_sysErrHook" 16419 "IBST_d035_rpsOffsEeReadFail" 16418 "IBST_d034_motorOscillationDet" 16417 "IBST_d033_oc6Monitor" 16416 "IBST_d032_oc6InitTestFail" 16415 "IBST_d031_ibDtrFail" 16414 "IBST_d030_controllerDevTooBig" 16413 "IBST_d029_bmcShortedGateTest" 16412 "IBST_d028_ecuWdErrCntContErr" 16411 "IBST_d027_tempB6Plaus" 16410 "IBST_d026_ptsSupplyUndvolt" 16409 "IBST_d025_ptsSupply" 16408 "IBST_d024_smmOneReqsInit" 16407 "IBST_d023_stackOvrUndFlow" 16406 "IBST_d022_stmAswSysTout" 16405 "IBST_d021_ubbSupplyLine" 16404 "IBST_d020_voltPreRegModeFld" 16403 "IBST_d019_unsupportedHw" 16402 "IBST_d018_ucSafetyFlt" 16401 "IBST_d017_preDriveChckFail" 16400 "IBST_d016_xpassEchoCountErr" 16399 "IBST_d015_rtpEnaHigh" 16398 "IBST_d014_rpsOffsEeReadEmpty" 16397 "IBST_d013_xpassToutErr" 16396 "IBST_d012_netUndvolt" 16395 "IBST_d011_micSpiTransferErr" 16394 "IBST_d010_micSpiTout" 16393 "IBST_d009_netOvrvolt" 16392 "IBST_d008_ecuWdStatusContErr" 16391 "IBST_d007_ecuWdStarttestFls" 16390 "IBST_d006_ecuWdScheduleTout" 16389 "IBST_d005_ecuWdFltCntTstFls" 16388 "IBST_d004_deadlMonTaskx1Ovr" 16387 "IBST_d003_tle5012Config" 16386 "IBST_d002_tle5012SsccrcFail" 16385 "IBST_d001_bmcSingleTransTest" 16384 "IBST_d000_bmsInitTestFail" ;
